VERSION "dbc-export 1 2026.26.6.5"

NS_ :

BS_:

BU_: ADSP APB APP APS APSB BB BMS CC CMP CMPD CP DAS DI DIF DIR DPB EPAS3P EPAS3S EPASTP EPASTS EPBL EPBR ESP EVSE FC GTW HCML HCMR HVP IBST ICR IDB LS OCS1P PARK PCS PCS2 PM PMF PMR PNCD PTC RADC RCM RCM2 RCM3 RCU SCCM SCM SCS SDCR TAS TCU TCU2 TPMS TRCM UI UIS UMC USM V2G VC VCBATT VCBATT0 VCBATT1 VCBATT2 VCCC VCFRONT VCFRONT1 VCFRONT2 VCLEFT VCRIGHT VCSEAT2L VCSEAT2R VCSEC VEH

BO_ 811 APS_warningMatrix0: 8 APS
 SG_ APS_w001_DEPRECATED : 0|1@1+ (1,0) [0|1] "" Vector__XXX
 SG_ APS_w002_ldwDisabled : 1|1@1+ (1,0) [0|1] "" Vector__XXX
 SG_ APS_w003_isaDisabled : 2|1@1+ (1,0) [0|1] "" Vector__XXX
 SG_ APS_w004_accDisabled : 3|1@1+ (1,0) [0|1] "" Vector__XXX
 SG_ APS_w005_fcwCancelled : 4|1@1+ (1,0) [0|1] "" Vector__XXX
 SG_ APS_w006_aebCancelled : 5|1@1+ (1,0) [0|1] "" Vector__XXX
 SG_ APS_w007_ahlbDisabled : 6|1@1+ (1,0) [0|1] "" Vector__XXX
 SG_ APS_w008_parkDisabled : 7|1@1+ (1,0) [0|1] "" Vector__XXX
 SG_ APS_w009_aebFault : 8|1@1+ (1,0) [0|1] "" Vector__XXX
 SG_ APS_w010_radcCalibIssue : 9|1@1+ (1,0) [0|1] "" Vector__XXX
 SG_ APS_w011_scaEvent : 10|1@1+ (1,0) [0|1] "" Vector__XXX
 SG_ APS_w012_Cam_BootFailure : 11|1@1+ (1,0) [0|1] "" Vector__XXX
 SG_ APS_w013_Cam_Watchdog : 12|1@1+ (1,0) [0|1] "" Vector__XXX
 SG_ APS_w014_swAssert : 13|1@1+ (1,0) [0|1] "" Vector__XXX
 SG_ APS_w015_Camera_Failsafes : 14|1@1+ (1,0) [0|1] "" Vector__XXX
 SG_ APS_w016_aeb_e_event : 15|1@1+ (1,0) [0|1] "" Vector__XXX
 SG_ APS_w017_Cam_Msg_MIA : 16|1@1+ (1,0) [0|1] "" Vector__XXX
 SG_ APS_w018_ECU_Power_Issue : 17|1@1+ (1,0) [0|1] "" Vector__XXX
 SG_ APS_w019_ECU_Stack_Overflow : 18|1@1+ (1,0) [0|1] "" Vector__XXX
 SG_ APS_w020_ECU_checkstopError : 19|1@1+ (1,0) [0|1] "" Vector__XXX
 SG_ APS_w021_ECU_Temperature_Issue : 20|1@1+ (1,0) [0|1] "" Vector__XXX
 SG_ APS_w022_ECU_EEPROM_Failure : 21|1@1+ (1,0) [0|1] "" Vector__XXX
 SG_ APS_w023_ECU_Cam_Statemismatc : 22|1@1+ (1,0) [0|1] "" Vector__XXX
 SG_ APS_w024_ECU_Watchdog_Reset : 23|1@1+ (1,0) [0|1] "" Vector__XXX
 SG_ APS_w025_LC_Steering_Override : 24|1@1+ (1,0) [0|1] "" Vector__XXX
 SG_ APS_w026_ECU_timingIssue : 25|1@1+ (1,0) [0|1] "" Vector__XXX
 SG_ APS_w027_ECU_Reset_Fault : 26|1@1+ (1,0) [0|1] "" Vector__XXX
 SG_ APS_w028_spi_rx_error : 27|1@1+ (1,0) [0|1] "" Vector__XXX
 SG_ APS_w029_spi_tx_error : 28|1@1+ (1,0) [0|1] "" Vector__XXX
 SG_ APS_w030_Heater_Issue : 29|1@1+ (1,0) [0|1] "" Vector__XXX
 SG_ APS_w031_canRxError : 30|1@1+ (1,0) [0|1] "" Vector__XXX
 SG_ APS_w032_canTxError : 31|1@1+ (1,0) [0|1] "" Vector__XXX
 SG_ APS_w033_gtwMia : 32|1@1+ (1,0) [0|1] "" Vector__XXX
 SG_ APS_w034_sccmMia : 33|1@1+ (1,0) [0|1] "" Vector__XXX
 SG_ APS_w035_espMia : 34|1@1+ (1,0) [0|1] "" Vector__XXX
 SG_ APS_w036_bdyMia : 35|1@1+ (1,0) [0|1] "" Vector__XXX
 SG_ APS_w037_camTacIssue : 36|1@1+ (1,0) [0|1] "" Vector__XXX
 SG_ APS_w038_camFailure : 37|1@1+ (1,0) [0|1] "" Vector__XXX
 SG_ APS_w039_sdm_rcm_Mia : 38|1@1+ (1,0) [0|1] "" Vector__XXX
 SG_ APS_w040_autopilotAngleSaturated : 39|1@1+ (1,0) [0|1] "" Vector__XXX
 SG_ APS_w041_autopilotRateSaturated : 40|1@1+ (1,0) [0|1] "" Vector__XXX
 SG_ APS_w042_autopilotAborting : 41|1@1+ (1,0) [0|1] "" Vector__XXX
 SG_ APS_w043_camLongRunTime : 42|1@1+ (1,0) [0|1] "" Vector__XXX
 SG_ APS_w044_appMobileyeFailure : 43|1@1+ (1,0) [0|1] "" Vector__XXX
 SG_ APS_w045_radMia : 44|1@1+ (1,0) [0|1] "" Vector__XXX
 SG_ APS_w046_eepromRecordAbsent : 45|1@1+ (1,0) [0|1] "" Vector__XXX
 SG_ APS_w047_edrEvent : 46|1@1+ (1,0) [0|1] "" Vector__XXX
 SG_ APS_w048_DAS_Features_Disabled : 47|1@1+ (1,0) [0|1] "" Vector__XXX
 SG_ APS_w049_eyeqVersionMismatch : 48|1@1+ (1,0) [0|1] "" Vector__XXX
 SG_ APS_w050_aeb_event : 49|1@1+ (1,0) [0|1] "" Vector__XXX
 SG_ APS_w051_radcEcuIssue : 50|1@1+ (1,0) [0|1] "" Vector__XXX
 SG_ APS_w052_radcSensorIssue : 51|1@1+ (1,0) [0|1] "" Vector__XXX
 SG_ APS_w053_radcCommIssue : 52|1@1+ (1,0) [0|1] "" Vector__XXX
 SG_ APS_w054_camAutofix : 53|1@1+ (1,0) [0|1] "" Vector__XXX
 SG_ APS_w055_radcVersionMismatch : 54|1@1+ (1,0) [0|1] "" Vector__XXX
 SG_ APS_w056_diMia : 55|1@1+ (1,0) [0|1] "" Vector__XXX
 SG_ APS_w057_mcuMia : 56|1@1+ (1,0) [0|1] "" Vector__XXX
 SG_ APS_w058_epbMia : 57|1@1+ (1,0) [0|1] "" Vector__XXX
 SG_ APS_w059_parkMia : 58|1@1+ (1,0) [0|1] "" Vector__XXX
 SG_ APS_w060_fcw_event : 59|1@1+ (1,0) [0|1] "" Vector__XXX
 SG_ APS_w061_tasMia : 60|1@1+ (1,0) [0|1] "" Vector__XXX
 SG_ APS_w062_radcAlignment : 61|1@1+ (1,0) [0|1] "" Vector__XXX
 SG_ APS_w063_parkVersionMismatch : 62|1@1+ (1,0) [0|1] "" Vector__XXX
 SG_ APS_w064_epasMia : 63|1@1+ (1,0) [0|1] "" Vector__XXX

BO_ 876 APS_warningMatrix1: 8 APS
 SG_ APS_w065_deserializerOvercurrent : 0|1@1+ (1,0) [0|1] "" Vector__XXX
 SG_ APS_w066_deserializerLockLost : 1|1@1+ (1,0) [0|1] "" Vector__XXX
 SG_ APS_w067_steeringAlignment : 2|1@1+ (1,0) [0|1] "" Vector__XXX
 SG_ APS_w068_vlInconsistency : 3|1@1+ (1,0) [0|1] "" Vector__XXX
 SG_ APS_w069_apcSpaceMasked : 4|1@1+ (1,0) [0|1] "" Vector__XXX
 SG_ APS_w070_apcIncompleteCal : 5|1@1+ (1,0) [0|1] "" Vector__XXX
 SG_ APS_w071_selfparkStarted : 6|1@1+ (1,0) [0|1] "" Vector__XXX
 SG_ APS_w072_selfparkComplete : 7|1@1+ (1,0) [0|1] "" Vector__XXX
 SG_ APS_w073_issueEscalatedLDW : 8|1@1+ (1,0) [0|1] "" Vector__XXX
 SG_ APS_w074_inPathStationaryObst : 9|1@1+ (1,0) [0|1] "" Vector__XXX
 SG_ APS_w075_scMia : 10|1@1+ (1,0) [0|1] "" Vector__XXX
 SG_ APS_w076_mobilEyeSetC : 11|1@1+ (1,0) [0|1] "" Vector__XXX
 SG_ APS_w077_pmmActive : 12|1@1+ (1,0) [0|1] "" Vector__XXX
 SG_ APS_w078_pmmActive2 : 13|1@1+ (1,0) [0|1] "" Vector__XXX
 SG_ APS_w079_edrAvailable : 14|1@1+ (1,0) [0|1] "" Vector__XXX
 SG_ APS_w080_accFailedActivation : 15|1@1+ (1,0) [0|1] "" Vector__XXX
 SG_ APS_w081_pmmActiveBraking : 16|1@1+ (1,0) [0|1] "" Vector__XXX
 SG_ APS_w082_inPathFSviolation : 17|1@1+ (1,0) [0|1] "" Vector__XXX
 SG_ APS_w083_inPathRADObject : 18|1@1+ (1,0) [0|1] "" Vector__XXX
 SG_ APS_w084_pmmIPSO : 19|1@1+ (1,0) [0|1] "" Vector__XXX
 SG_ APS_w085_pmmSteering : 20|1@1+ (1,0) [0|1] "" Vector__XXX
 SG_ APS_w086_robCollision : 21|1@1+ (1,0) [0|1] "" Vector__XXX
 SG_ APS_w087_DEPRECATED : 22|1@1+ (1,0) [0|1] "" Vector__XXX
 SG_ APS_w088_DEPRECATED : 23|1@1+ (1,0) [0|1] "" Vector__XXX
 SG_ APS_w089_DEPRECATED : 24|1@1+ (1,0) [0|1] "" Vector__XXX
 SG_ APS_w090_DEPRECATED : 25|1@1+ (1,0) [0|1] "" Vector__XXX
 SG_ APS_w091_DEPRECATED : 26|1@1+ (1,0) [0|1] "" Vector__XXX
 SG_ APS_w092_DEPRECATED : 27|1@1+ (1,0) [0|1] "" Vector__XXX
 SG_ APS_w093_DEPRECATED : 28|1@1+ (1,0) [0|1] "" Vector__XXX
 SG_ APS_w094_DEPRECATED : 29|1@1+ (1,0) [0|1] "" Vector__XXX
 SG_ APS_w095_DEPRECATED : 30|1@1+ (1,0) [0|1] "" Vector__XXX
 SG_ APS_w096_DEPRECATED : 31|1@1+ (1,0) [0|1] "" Vector__XXX
 SG_ APS_w097_DEPRECATED : 32|1@1+ (1,0) [0|1] "" Vector__XXX
 SG_ APS_w098_DEPRECATED : 33|1@1+ (1,0) [0|1] "" Vector__XXX
 SG_ APS_w099_DEPRECATED : 34|1@1+ (1,0) [0|1] "" Vector__XXX
 SG_ APS_w100_DEPRECATED : 35|1@1+ (1,0) [0|1] "" Vector__XXX
 SG_ APS_w101_DEPRECATED : 36|1@1+ (1,0) [0|1] "" Vector__XXX
 SG_ APS_w102_DEPRECATED : 37|1@1+ (1,0) [0|1] "" Vector__XXX
 SG_ APS_w103_robExperimentalAEB : 38|1@1+ (1,0) [0|1] "" Vector__XXX
 SG_ APS_w104_DEPRECATED : 39|1@1+ (1,0) [0|1] "" Vector__XXX
 SG_ APS_w105_DEPRECATED : 40|1@1+ (1,0) [0|1] "" Vector__XXX
 SG_ APS_w106_torsionBarOffset : 41|1@1+ (1,0) [0|1] "" Vector__XXX

BO_ 1113 APS_warningMatrix2: 8 APS
 SG_ APS_w129_ECU_Power_Issue : 0|1@1+ (1,0) [0|1] "" Vector__XXX
 SG_ APS_w130_ECU_Thermal_Issue : 1|1@1+ (1,0) [0|1] "" Vector__XXX
 SG_ APS_w131_trap_exception : 2|1@1+ (1,0) [0|1] "" Vector__XXX
 SG_ APS_w132_appVersionMismatch : 3|1@1+ (1,0) [0|1] "" Vector__XXX
 SG_ APS_w133_ETHSwitchError : 4|1@1+ (1,0) [0|1] "" Vector__XXX
 SG_ APS_w134_appMia : 5|1@1+ (1,0) [0|1] "" Vector__XXX
 SG_ APS_w135_appCritical : 6|1@1+ (1,0) [0|1] "" Vector__XXX
 SG_ APS_w136_gpsDisabled : 7|1@1+ (1,0) [0|1] "" Vector__XXX
 SG_ APS_w137_gpsFaultReset : 8|1@1+ (1,0) [0|1] "" Vector__XXX
 SG_ APS_w138_gpsComIssue : 9|1@1+ (1,0) [0|1] "" Vector__XXX
 SG_ APS_w139_udpBufferOverflow : 10|1@1+ (1,0) [0|1] "" Vector__XXX
 SG_ APS_w140_vcfrontMiaVehicleBus : 11|1@1+ (1,0) [0|1] "" Vector__XXX
 SG_ APS_w141_rcmMiaPartyBus : 12|1@1+ (1,0) [0|1] "" Vector__XXX
 SG_ APS_w142_diMiaPartyBus : 13|1@1+ (1,0) [0|1] "" Vector__XXX
 SG_ APS_w143_espMiaPartyBus : 14|1@1+ (1,0) [0|1] "" Vector__XXX
 SG_ APS_w144_vcleftMiaPartyBus : 15|1@1+ (1,0) [0|1] "" Vector__XXX
 SG_ APS_w145_vcrightMiaPartyBus : 16|1@1+ (1,0) [0|1] "" Vector__XXX
 SG_ APS_w146_epas3pMiaPartyBus : 17|1@1+ (1,0) [0|1] "" Vector__XXX
 SG_ APS_w147_vcleftMiaVehBus : 18|1@1+ (1,0) [0|1] "" Vector__XXX
 SG_ APS_w148_vcrightMiaVehBus : 19|1@1+ (1,0) [0|1] "" Vector__XXX
 SG_ APS_w149_epblMiaVehBus : 20|1@1+ (1,0) [0|1] "" Vector__XXX
 SG_ APS_w150_sccmMiaVehBus : 21|1@1+ (1,0) [0|1] "" Vector__XXX
 SG_ APS_w151_apRecovered : 22|1@1+ (1,0) [0|1] "" Vector__XXX
 SG_ APS_w152_gpsFusionStatus : 23|1@1+ (1,0) [0|1] "" Vector__XXX
 SG_ APS_w153_eacInhibit : 24|1@1+ (1,0) [0|1] "" Vector__XXX
 SG_ APS_w155_ethLwipError : 26|1@1+ (1,0) [0|1] "" Vector__XXX
 SG_ APS_w156_lwipAssert : 27|1@1+ (1,0) [0|1] "" Vector__XXX
 SG_ APS_w157_autopilotReboot : 28|1@1+ (1,0) [0|1] "" Vector__XXX
 SG_ APS_w158_apbMia : 29|1@1+ (1,0) [0|1] "" Vector__XXX
 SG_ APS_w159_apbCritical : 30|1@1+ (1,0) [0|1] "" Vector__XXX
 SG_ APS_w160_apbVersionMismatch : 31|1@1+ (1,0) [0|1] "" Vector__XXX
 SG_ APS_w161_gpsAntennaDisconnected : 32|1@1+ (1,0) [0|1] "" Vector__XXX
 SG_ APS_w162_TurboA_DisRegPgoodErr : 33|1@1+ (1,0) [0|1] "" Vector__XXX
 SG_ APS_w163_TurboA_DisRegNFault : 34|1@1+ (1,0) [0|1] "" Vector__XXX
 SG_ APS_w164_TurboA_12VFuseFault : 35|1@1+ (1,0) [0|1] "" Vector__XXX
 SG_ APS_w165_TurboA_Temp_NOS : 36|1@1+ (1,0) [0|1] "" Vector__XXX
 SG_ APS_w166_TurboA_SMSLockStepErr : 37|1@1+ (1,0) [0|1] "" Vector__XXX
 SG_ APS_w167_TurboA_TMU_Throttle : 38|1@1+ (1,0) [0|1] "" Vector__XXX
 SG_ APS_w168_TurboA_SMS_WDOG : 39|1@1+ (1,0) [0|1] "" Vector__XXX
 SG_ APS_w169_TurboA_SCS_LKUP : 40|1@1+ (1,0) [0|1] "" Vector__XXX
 SG_ APS_w170_TurboA_A72_watchdog : 41|1@1+ (1,0) [0|1] "" Vector__XXX
 SG_ APS_w171_TurboA_SMS_taskUtilErr : 42|1@1+ (1,0) [0|1] "" Vector__XXX
 SG_ APS_w172_apFeaturesUnavailable : 43|1@1+ (1,0) [0|1] "" Vector__XXX
 SG_ APS_w178_TurboB_DisRegPgoodErr : 49|1@1+ (1,0) [0|1] "" Vector__XXX
 SG_ APS_w179_TurboB_DisRegNFault : 50|1@1+ (1,0) [0|1] "" Vector__XXX
 SG_ APS_w180_TurboB_12VFuseFault : 51|1@1+ (1,0) [0|1] "" Vector__XXX
 SG_ APS_w181_TurboB_Temp_NOS : 52|1@1+ (1,0) [0|1] "" Vector__XXX
 SG_ APS_w182_TurboB_SMSLockStepErr : 53|1@1+ (1,0) [0|1] "" Vector__XXX
 SG_ APS_w183_TurboB_TMU_Throttle : 54|1@1+ (1,0) [0|1] "" Vector__XXX
 SG_ APS_w184_TurboB_SMS_WDOG : 55|1@1+ (1,0) [0|1] "" Vector__XXX
 SG_ APS_w185_TurboB_SCS_LKUP : 56|1@1+ (1,0) [0|1] "" Vector__XXX
 SG_ APS_w186_TurboB_A72_watchdog : 57|1@1+ (1,0) [0|1] "" Vector__XXX
 SG_ APS_w187_TurboB_SMS_taskUtilErr : 58|1@1+ (1,0) [0|1] "" Vector__XXX
 SG_ APS_w188_otherTurboUartMIA : 59|1@1+ (1,0) [0|1] "" Vector__XXX
 SG_ APS_w189_vcfrontMiaPartyBus : 60|1@1+ (1,0) [0|1] "" Vector__XXX
 SG_ APS_w190_iboosterMia : 61|1@1+ (1,0) [0|1] "" Vector__XXX
 SG_ APS_w191_timesyncError : 62|1@1+ (1,0) [0|1] "" Vector__XXX
 SG_ APS_w192_CANFault : 63|1@1+ (1,0) [0|1] "" Vector__XXX

BO_ 848 APS_warningMatrix3: 8 APS
 SG_ APS_w193_camWindshieldUnclean : 0|1@1+ (1,0) [0|1] "" Vector__XXX
 SG_ APS_w194_accDriverResumeRqrd : 1|1@1+ (1,0) [0|1] "" Vector__XXX
 SG_ APS_w195_scwUnavailable : 2|1@1+ (1,0) [0|1] "" Vector__XXX
 SG_ APS_w196_stopSignWarning : 3|1@1+ (1,0) [0|1] "" Vector__XXX
 SG_ APS_w197_redLightWarning : 4|1@1+ (1,0) [0|1] "" Vector__XXX
 SG_ APS_w198_tsrUnavailable : 5|1@1+ (1,0) [0|1] "" Vector__XXX
 SG_ APS_w199_apcAbort : 6|1@1+ (1,0) [0|1] "" Vector__XXX
 SG_ APS_w200_lcSlowdown : 7|1@1+ (1,0) [0|1] "" Vector__XXX
 SG_ APS_w201_lcAborting : 8|1@1+ (1,0) [0|1] "" Vector__XXX
 SG_ APS_w202_scwNoisyEnvironment : 9|1@1+ (1,0) [0|1] "" Vector__XXX
 SG_ APS_w203_apcActivation : 10|1@1+ (1,0) [0|1] "" Vector__XXX
 SG_ APS_w204_apcFinalFront : 11|1@1+ (1,0) [0|1] "" Vector__XXX
 SG_ APS_w205_apcFinalRear : 12|1@1+ (1,0) [0|1] "" Vector__XXX
 SG_ APS_w206_autosteerNotEnabled : 13|1@1+ (1,0) [0|1] "" Vector__XXX
 SG_ APS_w207_autosteerUnavailable : 14|1@1+ (1,0) [0|1] "" Vector__XXX
 SG_ APS_w208_rackDetected : 15|1@1+ (1,0) [0|1] "" Vector__XXX
 SG_ APS_w209_autoSummonRequest : 16|1@1+ (1,0) [0|1] "" Vector__XXX
 SG_ APS_w210_camObstrcted : 17|1@1+ (1,0) [0|1] "" Vector__XXX
 SG_ APS_w211_accNoSeatBelt : 18|1@1+ (1,0) [0|1] "" Vector__XXX
 SG_ APS_w212_lcUnavailableStrikeOut : 19|1@1+ (1,0) [0|1] "" Vector__XXX
 SG_ APS_w213_autosteerStruckOut : 20|1@1+ (1,0) [0|1] "" Vector__XXX
 SG_ APS_w214_driverNotIntracting : 21|1@1+ (1,0) [0|1] "" Vector__XXX
 SG_ APS_w215_contDriverNotIntracting : 22|1@1+ (1,0) [0|1] "" Vector__XXX
 SG_ APS_w216_driverOverriding : 23|1@1+ (1,0) [0|1] "" Vector__XXX
 SG_ APS_w217_lcUnavailableSpeeding : 24|1@1+ (1,0) [0|1] "" Vector__XXX
 SG_ APS_w218_lcSpeedExceededLimit : 25|1@1+ (1,0) [0|1] "" Vector__XXX
 SG_ APS_w219_lcTempUnavailableSpeed : 26|1@1+ (1,0) [0|1] "" Vector__XXX
 SG_ APS_w220_lcTempUnavailableRoad : 27|1@1+ (1,0) [0|1] "" Vector__XXX
 SG_ APS_w221_accRadarBlind : 28|1@1+ (1,0) [0|1] "" Vector__XXX
 SG_ APS_w222_accCameraBlind : 29|1@1+ (1,0) [0|1] "" Vector__XXX
 SG_ APS_w223_accObjectInPath : 30|1@1+ (1,0) [0|1] "" Vector__XXX
 SG_ APS_w224_accCameraCalibration : 31|1@1+ (1,0) [0|1] "" Vector__XXX
 SG_ APS_w225_lcDegradedVisSpeedLmt : 32|1@1+ (1,0) [0|1] "" Vector__XXX
 SG_ APS_w226_lcCamCalNeededSpeedLmt : 33|1@1+ (1,0) [0|1] "" Vector__XXX
 SG_ APS_w227_virtualWallBlocked : 34|1@1+ (1,0) [0|1] "" Vector__XXX
 SG_ APS_w228_DEPRECATED : 35|1@1+ (1,0) [0|1] "" Vector__XXX
 SG_ APS_w229_alcUltrasoundDamaged : 36|1@1+ (1,0) [0|1] "" Vector__XXX
 SG_ APS_w230_alcUltrasoundBlocked : 37|1@1+ (1,0) [0|1] "" Vector__XXX
 SG_ APS_w231_idfEvent : 38|1@1+ (1,0) [0|1] "" Vector__XXX
 SG_ APS_w232_laneChangeRequested : 39|1@1+ (1,0) [0|1] "" Vector__XXX
 SG_ APS_w235_a72LoopDetected : 42|1@1+ (1,0) [0|1] "" Vector__XXX
 SG_ APS_w236_canSharedMemError : 43|1@1+ (1,0) [0|1] "" Vector__XXX
 SG_ APS_w237_faultMgrEventDetected : 44|1@1+ (1,0) [0|1] "" Vector__XXX
 SG_ APS_w238_resetReason : 45|1@1+ (1,0) [0|1] "" Vector__XXX
 SG_ APS_w241_ddrInitFailures : 48|1@1+ (1,0) [0|1] "" Vector__XXX
 SG_ APS_w242_tripMBISTFailure : 49|1@1+ (1,0) [0|1] "" Vector__XXX
 SG_ APS_w243_tripHWErrorStatus : 50|1@1+ (1,0) [0|1] "" Vector__XXX
 SG_ APS_w244_gpuHWFaultStatus : 51|1@1+ (1,0) [0|1] "" Vector__XXX
 SG_ APS_w245_eloopRxFromUnexpectedSo : 52|1@1+ (1,0) [0|1] "" Vector__XXX
 SG_ APS_w246_ethloopSwitchPortLinkDo : 53|1@1+ (1,0) [0|1] "" Vector__XXX
 SG_ APS_w247_ethernetFrameError : 54|1@1+ (1,0) [0|1] "" Vector__XXX
 SG_ APS_w248_ethloopSwitchPoorSqi : 55|1@1+ (1,0) [0|1] "" Vector__XXX
 SG_ APS_w249_ufsFailures : 56|1@1+ (1,0) [0|1] "" Vector__XXX
 SG_ APS_w250_ethloopSwitchMemUsageTo : 57|1@1+ (1,0) [0|1] "" Vector__XXX
 SG_ APS_w251_ethloopSwitchMemUsageTo : 58|1@1+ (1,0) [0|1] "" Vector__XXX
 SG_ APS_w252_ethSwitchPortLinkDown : 59|1@1+ (1,0) [0|1] "" Vector__XXX
 SG_ APS_w253_powerStateTimeout : 60|1@1+ (1,0) [0|1] "" Vector__XXX
 SG_ APS_w254_sleepStateTimeout : 61|1@1+ (1,0) [0|1] "" Vector__XXX
 SG_ APS_w255_bootHealth : 62|1@1+ (1,0) [0|1] "" Vector__XXX

BO_ 784 APS_warningMatrix4: 8 APS
 SG_ APS_w257_assertFailure : 0|1@1+ (1,0) [0|1] "" Vector__XXX
 SG_ APS_w258_qspiFlashSectorChecksum : 1|1@1+ (1,0) [0|1] "" Vector__XXX
 SG_ APS_w259_qspiFailure : 2|1@1+ (1,0) [0|1] "" Vector__XXX
 SG_ APS_w260_pgoodFailure : 3|1@1+ (1,0) [0|1] "" Vector__XXX
 SG_ APS_w261_vrmFaultGrpA : 4|1@1+ (1,0) [0|1] "" Vector__XXX
 SG_ APS_w262_vrmFaultGrpB : 5|1@1+ (1,0) [0|1] "" Vector__XXX
 SG_ APS_w263_vrmFaultGrpC : 6|1@1+ (1,0) [0|1] "" Vector__XXX
 SG_ APS_w264_ddrPhy0Failures : 7|1@1+ (1,0) [0|1] "" Vector__XXX
 SG_ APS_w265_ddrPhy1Failures : 8|1@1+ (1,0) [0|1] "" Vector__XXX
 SG_ APS_w266_ddrPhy2Failures : 9|1@1+ (1,0) [0|1] "" Vector__XXX
 SG_ APS_w267_ddrPhy3Failures : 10|1@1+ (1,0) [0|1] "" Vector__XXX
 SG_ APS_w268_ddrControllerFailures : 11|1@1+ (1,0) [0|1] "" Vector__XXX
 SG_ APS_w269_ethSwitchRxPageCountToo : 12|1@1+ (1,0) [0|1] "" Vector__XXX
 SG_ APS_w270_ethSwitchRxPageCountToo : 13|1@1+ (1,0) [0|1] "" Vector__XXX
 SG_ APS_w271_ddrScheduler0EccErrors : 14|1@1+ (1,0) [0|1] "" Vector__XXX
 SG_ APS_w272_ddrScheduler1EccErrors : 15|1@1+ (1,0) [0|1] "" Vector__XXX
 SG_ APS_w273_ddrScheduler2EccErrors : 16|1@1+ (1,0) [0|1] "" Vector__XXX
 SG_ APS_w274_ddrScheduler3EccErrors : 17|1@1+ (1,0) [0|1] "" Vector__XXX
 SG_ APS_w275_ddrScheduler4EccErrors : 18|1@1+ (1,0) [0|1] "" Vector__XXX
 SG_ APS_w276_ddrScheduler5EccErrors : 19|1@1+ (1,0) [0|1] "" Vector__XXX
 SG_ APS_w277_ddrScheduler6EccErrors : 20|1@1+ (1,0) [0|1] "" Vector__XXX
 SG_ APS_w278_ddrScheduler7EccErrors : 21|1@1+ (1,0) [0|1] "" Vector__XXX
 SG_ APS_w279_ufsPartitionError : 22|1@1+ (1,0) [0|1] "" Vector__XXX
 SG_ APS_w280_pepsMia : 23|1@1+ (1,0) [0|1] "" Vector__XXX
 SG_ APS_w281_rsaMia : 24|1@1+ (1,0) [0|1] "" Vector__XXX
 SG_ APS_w282_smmuError : 25|1@1+ (1,0) [0|1] "" Vector__XXX
 SG_ APS_w283_psfaMia : 26|1@1+ (1,0) [0|1] "" Vector__XXX
 SG_ APS_w284_cam12VBuckBoostAPwrIssu : 27|1@1+ (1,0) [0|1] "" Vector__XXX
 SG_ APS_w285_cam12VBuckBoostBPwrIssu : 28|1@1+ (1,0) [0|1] "" Vector__XXX
 SG_ APS_w286_cam12VEFuseAPrimaryIssu : 29|1@1+ (1,0) [0|1] "" Vector__XXX
 SG_ APS_w287_cam12VEFuseASecondaryIs : 30|1@1+ (1,0) [0|1] "" Vector__XXX
 SG_ APS_w288_brakeboosterMia : 31|1@1+ (1,0) [0|1] "" Vector__XXX
 SG_ APS_w289_turboTemperatureWarning : 32|1@1+ (1,0) [0|1] "" Vector__XXX
 SG_ APS_w290_cam12VBuckBoostBPwrRing : 33|1@1+ (1,0) [0|1] "" Vector__XXX
 SG_ APS_w291_eplannerError : 34|1@1+ (1,0) [0|1] "" Vector__XXX
 SG_ APS_w292_CH_busOff : 35|1@1+ (1,0) [0|1] "" Vector__XXX
 SG_ APS_w293_PARTY_busOff : 36|1@1+ (1,0) [0|1] "" Vector__XXX
 SG_ APS_w294_VEH_busOff : 37|1@1+ (1,0) [0|1] "" Vector__XXX
 SG_ APS_w295_PT_busOff : 38|1@1+ (1,0) [0|1] "" Vector__XXX
 SG_ APS_w296_wdogMonTaskDeadlineMiss : 39|1@1+ (1,0) [0|1] "" Vector__XXX
 SG_ APS_w297_earlyWDogAlert : 40|1@1+ (1,0) [0|1] "" Vector__XXX
 SG_ APS_w298_cpuToApCanSharedMemErro : 41|1@1+ (1,0) [0|1] "" Vector__XXX
 SG_ APS_w299_apToCpuCanSharedMemErro : 42|1@1+ (1,0) [0|1] "" Vector__XXX
 SG_ APS_w300_sharedMemoryAccessError : 43|1@1+ (1,0) [0|1] "" Vector__XXX
 SG_ APS_w301_nocTimeoutDetected : 44|1@1+ (1,0) [0|1] "" Vector__XXX
 SG_ APS_w302_canAPShmFifoFull : 45|1@1+ (1,0) [0|1] "" Vector__XXX
 SG_ APS_w303_canAPShmFifoEmpty : 46|1@1+ (1,0) [0|1] "" Vector__XXX
 SG_ APS_w304_dataAbort : 47|1@1+ (1,0) [0|1] "" Vector__XXX
 SG_ APS_w305_gpsPgoodFailure : 48|1@1+ (1,0) [0|1] "" Vector__XXX
 SG_ APS_w306_ethPgoodFailure : 49|1@1+ (1,0) [0|1] "" Vector__XXX
 SG_ APS_w307_eccEventDetected : 50|1@1+ (1,0) [0|1] "" Vector__XXX
 SG_ APS_w308_pmicErrorDetected : 51|1@1+ (1,0) [0|1] "" Vector__XXX
 SG_ APS_w309_ethBridgeDown : 52|1@1+ (1,0) [0|1] "" Vector__XXX
 SG_ APS_w310_wakeBootMetrics : 53|1@1+ (1,0) [0|1] "" Vector__XXX
 SG_ APS_w311_apbdgDasMia : 54|1@1+ (1,0) [0|1] "" Vector__XXX
 SG_ APS_w312_apbdgApMia : 55|1@1+ (1,0) [0|1] "" Vector__XXX
 SG_ APS_w313_BDY_busOff : 56|1@1+ (1,0) [0|1] "" Vector__XXX
 SG_ APS_w315_epas3pMiaBdyBus : 58|1@1+ (1,0) [0|1] "" Vector__XXX
 SG_ APS_w316_apBootHealth : 59|1@1+ (1,0) [0|1] "" Vector__XXX
 SG_ APS_w317_uiMia : 60|1@1+ (1,0) [0|1] "" Vector__XXX
 SG_ APS_w318_ethernetNetworkBufferHi : 61|1@1+ (1,0) [0|1] "" Vector__XXX
 SG_ APS_w319_vehDasImposterDetected : 62|1@1+ (1,0) [0|1] "" Vector__XXX
 SG_ APS_w320_eplannerPreconditionsMe : 63|1@1+ (1,0) [0|1] "" Vector__XXX

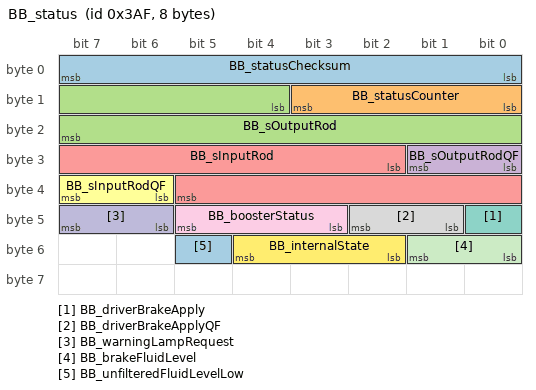
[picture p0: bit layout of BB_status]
BO_ 943 BB_status: 8 BB
 SG_ BB_statusChecksum : 0|8@1+ (1,0) [0|255] "" Vector__XXX
 SG_ BB_statusCounter : 8|4@1+ (1,0) [0|15] "" Vector__XXX
 SG_ BB_sOutputRod : 12|12@1+ (0.015625,-5) [-5|47] "mm" Vector__XXX
 SG_ BB_sOutputRodQF : 24|2@1+ (1,0) [0|3] "" Vector__XXX
 SG_ BB_sInputRod : 26|12@1+ (0.015625,-5) [-5|47] "mm" Vector__XXX
 SG_ BB_sInputRodQF : 38|2@1+ (1,0) [0|3] "" Vector__XXX
 SG_ BB_driverBrakeApply : 40|1@1+ (1,0) [0|1] "" Vector__XXX
 SG_ BB_driverBrakeApplyQF : 41|2@1+ (1,0) [0|3] "" Vector__XXX
 SG_ BB_boosterStatus : 43|3@1+ (1,0) [0|7] "" Vector__XXX
 SG_ BB_warningLampRequest : 46|2@1+ (1,0) [0|3] "" Vector__XXX
 SG_ BB_brakeFluidLevel : 48|2@1+ (1,0) [0|3] "" Vector__XXX
 SG_ BB_internalState : 50|3@1+ (1,0) [0|7] "" Vector__XXX
 SG_ BB_unfilteredFluidLevelLow : 53|1@1+ (1,0) [0|1] "" Vector__XXX

BO_ 1343 BMS_alertLog: 8 BMS
 SG_ BMS_alertID M : 0|9@1+ (1,0) [0|511] "" Vector__XXX
 SG_ BMS_alertSet : 15|1@1+ (1,0) [0|1] "" Vector__XXX
 SG_ BMS_a001_gatewayPackEnergy m1 : 16|2@1+ (1,0) [0|3] "" Vector__XXX
 SG_ BMS_a001_expectedPackEnergy m1 : 18|2@1+ (1,0) [0|3] "" Vector__XXX
 SG_ BMS_a002_gatewayPackPerformanceD m2 : 16|3@1+ (1,0) [0|7] "" Vector__XXX
 SG_ BMS_a002_expectedPackPerformance m2 : 19|3@1+ (1,0) [0|7] "" Vector__XXX
 SG_ BMS_a002_bmsPackMass m2 : 24|8@1+ (1,300) [300|555] "" Vector__XXX
 SG_ BMS_a003_calBlockData_0 m3 : 16|32@1+ (1,0) [0|4294967295] "" Vector__XXX
 SG_ BMS_a017_packCurrent m17 : 16|8@1+ (8,-1500) [-1500|540] "" Vector__XXX
 SG_ BMS_a017_ovBrickVID m17 : 24|7@1+ (1,1) [1|128] "" Vector__XXX
 SG_ BMS_a017_ovBrickV m17 : 32|16@1+ (7.62939453125e-05,0) [0|4.99992370605] "" Vector__XXX
 SG_ BMS_a018_packCurrent m18 : 16|8@1+ (8,-1496) [-1496|544] "" Vector__XXX
 SG_ BMS_a018_uvBrickVID m18 : 24|7@1+ (1,1) [1|128] "" Vector__XXX
 SG_ BMS_a018_uvBrickV m18 : 32|16@1+ (7.62939453125e-05,0) [0|4.99992370605] "" Vector__XXX
 SG_ BMS_a019_coolantInletT m19 : 16|8@1+ (0.4,-20) [-20|82] "" Vector__XXX
 SG_ BMS_a019_activeCoolingTarget m19 : 24|8@1+ (0.4,-20) [-20|82] "" Vector__XXX
 SG_ BMS_a019_maxBrickT m19 : 32|8@1+ (0.4,-20) [-20|82] "" Vector__XXX
 SG_ BMS_a019_maxBrickTID m19 : 40|5@1+ (1,1) [1|32] "" Vector__XXX
 SG_ BMS_a021_chargeViolation m21 : 16|1@1+ (1,0) [0|1] "" Vector__XXX
 SG_ BMS_a021_currentLimit m21 : 24|8@1+ (8,-1496) [-1496|544] "" Vector__XXX
 SG_ BMS_a021_packCurrent m21 : 32|8@1+ (8,-1496) [-1496|544] "" Vector__XXX
 SG_ BMS_a022_chargeAccumulatorViolat m22 : 16|1@1+ (1,0) [0|1] "" Vector__XXX
 SG_ BMS_a022_chargeAccumulatorValue m22 : 17|23@1+ (10,0) [0|83886070] "" Vector__XXX
 SG_ BMS_a022_chargeAccumulatorLimit m22 : 40|23@1+ (10,0) [0|83886070] "" Vector__XXX
 SG_ BMS_a023_ovStackDeviceID m23 : 16|5@1+ (1,1) [1|32] "" Vector__XXX
 SG_ BMS_a023_ovStackV m23 : 24|16@1+ (0.00128,0) [0|83.8848] "" Vector__XXX
 SG_ BMS_a024_brickID m24 : 16|8@1+ (1,1) [1|256] "" Vector__XXX
 SG_ BMS_a024_deltaV m24 : 24|16@1- (0.0001,0) [-3.2768|3.2767] "" Vector__XXX
 SG_ BMS_a024_avgDvPrev m24 : 40|16@1- (0.0001,0) [-3.2768|3.2767] "" Vector__XXX
 SG_ BMS_a024_packCurrent m24 : 56|8@1+ (8,-1500) [-1500|540] "" Vector__XXX
 SG_ BMS_a027_swIsolationCount m27 : 16|8@1+ (1,0) [0|255] "" Vector__XXX
 SG_ BMS_a030_worstBrickID m30 : 16|8@1+ (1,1) [1|256] "" Vector__XXX
 SG_ BMS_a030_maxBrickImpedance m30 : 24|10@1+ (0.1,0) [0|102.3] "" Vector__XXX
 SG_ BMS_a030_maxNormalizedImpedanceD m30 : 34|7@1+ (0.04,0) [0|5.08] "" Vector__XXX
 SG_ BMS_a030_faultThreshold m30 : 41|7@1+ (0.04,0) [0|5.08] "" Vector__XXX
 SG_ BMS_a030_numBricks m30 : 48|8@1+ (1,0) [0|255] "" Vector__XXX
 SG_ BMS_a030_worstBrickSoc m30 : 56|8@1+ (0.5,0) [0|127.5] "" Vector__XXX
 SG_ BMS_a035_isoR m35 : 16|9@1+ (10,0) [0|5110] "" Vector__XXX
 SG_ BMS_a035_mode m35 : 25|3@1+ (1,0) [0|7] "" Vector__XXX
 SG_ BMS_a035_activeSideVNoR m35 : 28|9@1+ (1,0) [0|511] "" Vector__XXX
 SG_ BMS_a035_activeSideVWithR m35 : 37|9@1+ (1,0) [0|511] "" Vector__XXX
 SG_ BMS_a035_passiveSideVNoR m35 : 46|9@1+ (1,0) [0|511] "" Vector__XXX
 SG_ BMS_a035_passiveSideVWithR m35 : 55|9@1+ (1,0) [0|511] "" Vector__XXX
 SG_ BMS_a039_dcLinkVoltage m39 : 16|10@1+ (1,0) [0|1023] "" Vector__XXX
 SG_ BMS_a039_packVoltage m39 : 26|10@1+ (1,0) [0|1023] "" Vector__XXX
 SG_ BMS_a039_packContactorState m39 : 36|4@1+ (1,0) [0|15] "" Vector__XXX
 SG_ BMS_a039_packCurrent m39 : 40|8@1+ (8,-1496) [-1496|544] "" Vector__XXX
 SG_ BMS_a039_maxBrickV m39 : 48|8@1+ (0.01,2) [2|4.55] "" Vector__XXX
 SG_ BMS_a039_state m39 : 56|4@1+ (1,0) [0|15] "" Vector__XXX
 SG_ BMS_a041_resetType m41 : 16|4@1+ (1,0) [0|15] "" Vector__XXX
 SG_ BMS_a050_MIA_numBadReadings m50 : 16|8@1+ (1,0) [0|255] "" Vector__XXX
 SG_ BMS_a050_MIA_numSnaReadings m50 : 24|8@1+ (1,0) [0|255] "" Vector__XXX
 SG_ BMS_a050_MIA_brickId m50 : 32|8@1+ (1,1) [1|256] "" Vector__XXX
 SG_ BMS_a051_hvp1V5Ref m51 : 16|12@1+ (0.001,0) [0|4.095] "" Vector__XXX
 SG_ BMS_a051_hvp3V0Ref m51 : 28|12@1+ (0.001,0) [0|4.095] "" Vector__XXX
 SG_ BMS_a051_bms3V0Ref m51 : 40|12@1+ (0.001,0) [0|4.095] "" Vector__XXX
 SG_ BMS_a059_sumBrickVoltages m59 : 16|16@1+ (0.01,0) [0|655.35] "" Vector__XXX
 SG_ BMS_a059_packVoltage m59 : 32|16@1+ (0.01,0) [0|655.35] "" Vector__XXX
 SG_ BMS_a062_state m62 : 16|4@1+ (1,0) [0|15] "" Vector__XXX
 SG_ BMS_a062_minBrickVId m62 : 24|7@1+ (1,1) [1|128] "" Vector__XXX
 SG_ BMS_a062_minBrickVoltage m62 : 32|12@1+ (0.002,0) [0|8.19] "" Vector__XXX
 SG_ BMS_a062_maxBrickVId m62 : 44|7@1+ (1,1) [1|128] "" Vector__XXX
 SG_ BMS_a062_maxBrickVoltage m62 : 51|12@1+ (0.002,0) [0|8.19] "" Vector__XXX
 SG_ BMS_a063_cpFaultInV m63 : 16|12@1+ (0.001,0) [0|4.095] "" Vector__XXX
 SG_ BMS_a064_minBrickSOCID m64 : 16|7@1+ (1,1) [1|128] "" Vector__XXX
 SG_ BMS_a064_minBrickSOC m64 : 24|8@1+ (0.5,0) [0|127.5] "" Vector__XXX
 SG_ BMS_a064_maxBrickSOCID m64 : 32|7@1+ (1,1) [1|128] "" Vector__XXX
 SG_ BMS_a064_maxBrickSOC m64 : 40|8@1+ (0.5,0) [0|127.5] "" Vector__XXX
 SG_ BMS_a064_avgBrickSOC m64 : 48|8@1+ (0.5,0) [0|127.5] "" Vector__XXX
 SG_ BMS_a065_minBrickCacId m65 : 16|7@1+ (1,1) [1|128] "" Vector__XXX
 SG_ BMS_a065_minBrickCac m65 : 24|13@1+ (0.1,0) [0|819.1] "" Vector__XXX
 SG_ BMS_a065_avgBrickCac m65 : 40|13@1+ (0.1,0) [0|819.1] "" Vector__XXX
 SG_ BMS_a065_modCacImbalancePct m65 : 53|10@1+ (0.1,0) [0|102.3] "" Vector__XXX
 SG_ BMS_a066_minBrickSocId m66 : 16|7@1+ (1,1) [1|128] "" Vector__XXX
 SG_ BMS_a066_minBrickSocByOcvMax m66 : 24|8@1+ (0.5,0) [0|127.5] "" Vector__XXX
 SG_ BMS_a066_maxBrickSocId m66 : 32|7@1+ (1,1) [1|128] "" Vector__XXX
 SG_ BMS_a066_maxBrickSocByOcvMin m66 : 40|8@1+ (0.5,0) [0|127.5] "" Vector__XXX
 SG_ BMS_a066_maxBrickSoc m66 : 48|8@1+ (0.5,0) [0|127.5] "" Vector__XXX
 SG_ BMS_a066_avgBrickSoc m66 : 56|8@1+ (0.5,0) [0|127.5] "" Vector__XXX
 SG_ BMS_a067_minBrickCacId m67 : 16|7@1+ (1,1) [1|128] "" Vector__XXX
 SG_ BMS_a067_minBrickCac m67 : 24|13@1+ (0.1,0) [0|819.1] "" Vector__XXX
 SG_ BMS_a067_avgBrickCac m67 : 40|13@1+ (0.1,0) [0|819.1] "" Vector__XXX
 SG_ BMS_a067_modCacImbalancePct m67 : 53|10@1+ (0.1,0) [0|102.3] "" Vector__XXX
 SG_ BMS_a068_minBrickCacId m68 : 16|7@1+ (1,1) [1|128] "" Vector__XXX
 SG_ BMS_a068_minBrickCac m68 : 24|13@1+ (0.1,0) [0|819.1] "" Vector__XXX
 SG_ BMS_a068_avgBrickCac m68 : 40|13@1+ (0.1,0) [0|819.1] "" Vector__XXX
 SG_ BMS_a068_modCacImbalancePct m68 : 53|10@1+ (0.1,0) [0|102.3] "" Vector__XXX
 SG_ BMS_a069_dischargePowerPackVolta m69 : 16|8@1- (0.025,-3.15) [-6.35|0.025] "" Vector__XXX
 SG_ BMS_a069_dischargePowerBrickVolt m69 : 24|8@1- (0.005,-0.63) [-1.27|0.005] "" Vector__XXX
 SG_ BMS_a069_SOC m69 : 32|8@1+ (0.05,0) [0|12.75] "" Vector__XXX
 SG_ BMS_a069_minBrickT m69 : 40|8@1- (0.5,24) [-40|87.5] "" Vector__XXX
 SG_ BMS_a069_minBrickVLimit m69 : 48|8@1+ (0.01,2) [2|4.55] "" Vector__XXX
 SG_ BMS_a069_minBrickV m69 : 56|8@1+ (0.01,2) [2|4.55] "" Vector__XXX
 SG_ BMS_a070_state m70 : 16|4@1+ (1,0) [0|15] "" Vector__XXX
 SG_ BMS_a070_minBrickVId m70 : 24|7@1+ (1,1) [1|128] "" Vector__XXX
 SG_ BMS_a070_minBrickVoltage m70 : 32|12@1+ (0.002,0) [0|8.19] "" Vector__XXX
 SG_ BMS_a070_maxBrickVId m70 : 44|7@1+ (1,1) [1|128] "" Vector__XXX
 SG_ BMS_a070_maxBrickVoltage m70 : 51|12@1+ (0.002,0) [0|8.19] "" Vector__XXX
 SG_ BMS_a071_stateRequest m71 : 16|4@1+ (1,0) [0|15] "" Vector__XXX
 SG_ BMS_a071_state m71 : 20|4@1+ (1,0) [0|15] "" Vector__XXX
 SG_ BMS_a071_transitionAlertId m71 : 24|10@1+ (1,0) [0|1023] "" Vector__XXX
 SG_ BMS_a074_maxBrickVTarget m74 : 16|8@1+ (0.01,2) [2|4.55] "" Vector__XXX
 SG_ BMS_a074_maxBrickV m74 : 24|8@1+ (0.01,2) [2|4.55] "" Vector__XXX
 SG_ BMS_a075_chargeType m75 : 16|1@1+ (1,0) [0|1] "" Vector__XXX
 SG_ BMS_a076_netAh m76 : 16|21@1- (0.01,0) [-10485.76|10485.75] "" Vector__XXX
 SG_ BMS_a076_tetheringActive m76 : 37|1@1+ (1,0) [0|1] "" Vector__XXX
 SG_ BMS_a077_chargeErrType m77 : 16|1@1+ (1,0) [0|1] "" Vector__XXX
 SG_ BMS_a077_maxBrickVTarget m77 : 24|8@1+ (0.01,2) [2|4.55] "" Vector__XXX
 SG_ BMS_a077_maxBrickV m77 : 32|8@1+ (0.01,2) [2|4.55] "" Vector__XXX
 SG_ BMS_a077_packTargetCurrent m77 : 40|8@1+ (8,-1496) [-1496|544] "" Vector__XXX
 SG_ BMS_a077_packCurrent m77 : 48|8@1+ (8,-1496) [-1496|544] "" Vector__XXX
 SG_ BMS_a078_peakDchInChg m78 : 16|16@1- (0.1,0) [-3276.8|3276.7] "" Vector__XXX
 SG_ BMS_a079_maxBrickVTarget m79 : 16|8@1+ (0.01,2) [2|4.55] "" Vector__XXX
 SG_ BMS_a079_maxBrickV m79 : 24|8@1+ (0.01,2) [2|4.55] "" Vector__XXX
 SG_ BMS_a081_stateRequest m81 : 16|4@1+ (1,0) [0|15] "" Vector__XXX
 SG_ BMS_a081_firstBlockingAlertId m81 : 20|9@1+ (1,0) [0|511] "" Vector__XXX
 SG_ BMS_a081_secondBlockingAlertId m81 : 29|9@1+ (1,0) [0|511] "" Vector__XXX
 SG_ BMS_a081_thirdBlockingAlertId m81 : 38|9@1+ (1,0) [0|511] "" Vector__XXX
 SG_ BMS_a081_fourthBlockingAlertId m81 : 47|9@1+ (1,0) [0|511] "" Vector__XXX
 SG_ BMS_a081_totalAlertCount m81 : 56|8@1+ (1,0) [0|255] "" Vector__XXX
 SG_ BMS_a082_stateRequest m82 : 16|4@1+ (1,0) [0|15] "" Vector__XXX
 SG_ BMS_a082_firstAlertId m82 : 20|9@1+ (1,0) [0|511] "" Vector__XXX
 SG_ BMS_a082_secondAlertId m82 : 29|9@1+ (1,0) [0|511] "" Vector__XXX
 SG_ BMS_a082_thirdAlertId m82 : 38|9@1+ (1,0) [0|511] "" Vector__XXX
 SG_ BMS_a082_fourthAlertId m82 : 47|9@1+ (1,0) [0|511] "" Vector__XXX
 SG_ BMS_a082_totalAlertCount m82 : 56|8@1+ (1,0) [0|255] "" Vector__XXX
 SG_ BMS_a083_packContactorRequest m83 : 16|3@1+ (1,0) [0|7] "" Vector__XXX
 SG_ BMS_a085_packContactorSetStatePr m85 : 16|4@1+ (1,0) [0|15] "" Vector__XXX
 SG_ BMS_a085_packContactorSetState m85 : 20|4@1+ (1,0) [0|15] "" Vector__XXX
 SG_ BMS_a085_packContactorSetRe_0001 m85 : 24|3@1+ (1,0) [0|7] "" Vector__XXX
 SG_ BMS_a085_packContactorSetRequest m85 : 27|3@1+ (1,0) [0|7] "" Vector__XXX
 SG_ BMS_a086_fcContactorSetStatePrev m86 : 16|4@1+ (1,0) [0|15] "" Vector__XXX
 SG_ BMS_a086_fcContactorSetState m86 : 20|4@1+ (1,0) [0|15] "" Vector__XXX
 SG_ BMS_a086_fcContactorSetRequestPr m86 : 24|3@1+ (1,0) [0|7] "" Vector__XXX
 SG_ BMS_a086_fcContactorSetRequest m86 : 27|3@1+ (1,0) [0|7] "" Vector__XXX
 SG_ BMS_a087_blockingAlert m87 : 16|9@1+ (1,0) [0|511] "" Vector__XXX
 SG_ BMS_a090_GTWmessageTout m90 : 16|4@1+ (1,0) [0|15] "" Vector__XXX
 SG_ BMS_a098_breakLocationA m98 : 16|5@1+ (1,0) [0|31] "" Vector__XXX
 SG_ BMS_a098_bmbCommStatusTypeA m98 : 21|2@1+ (1,0) [0|3] "" Vector__XXX
 SG_ BMS_a098_breakLocationB m98 : 24|5@1+ (1,0) [0|31] "" Vector__XXX
 SG_ BMS_a098_bmbCommStatusTypeB m98 : 29|2@1+ (1,0) [0|3] "" Vector__XXX
 SG_ BMS_a098_alertFromHvp m98 : 31|1@1+ (1,0) [0|1] "" Vector__XXX
 SG_ BMS_a099_breakLocationA m99 : 16|5@1+ (1,0) [0|31] "" Vector__XXX
 SG_ BMS_a099_bmbCommStatusTypeA m99 : 21|2@1+ (1,0) [0|3] "" Vector__XXX
 SG_ BMS_a099_breakLocationB m99 : 24|5@1+ (1,0) [0|31] "" Vector__XXX
 SG_ BMS_a099_bmbCommStatusTypeB m99 : 29|2@1+ (1,0) [0|3] "" Vector__XXX
 SG_ BMS_a099_bmbChainBreakType m99 : 32|3@1+ (1,0) [0|7] "" Vector__XXX
 SG_ BMS_a099_alertFromHvp m99 : 35|1@1+ (1,0) [0|1] "" Vector__XXX
 SG_ BMS_a100_testTrigger m100 : 16|1@1+ (1,0) [0|1] "" Vector__XXX
 SG_ BMS_a100_setFromNvm m100 : 17|1@1+ (1,0) [0|1] "" Vector__XXX
 SG_ BMS_a100_voltageDeviation m100 : 18|1@1+ (1,0) [0|1] "" Vector__XXX
 SG_ BMS_a100_voltageLoss m100 : 19|1@1+ (1,0) [0|1] "" Vector__XXX
 SG_ BMS_a105_tSenseFailedModule1 m105 : 16|1@1+ (1,0) [0|1] "" Vector__XXX
 SG_ BMS_a105_avgBrickTModule1 m105 : 17|8@1+ (0.5,0) [0|127.5] "" Vector__XXX
 SG_ BMS_a105_tSenseFailedModule2 m105 : 25|1@1+ (1,0) [0|1] "" Vector__XXX
 SG_ BMS_a105_avgBrickTModule2 m105 : 26|8@1+ (0.5,0) [0|127.5] "" Vector__XXX
 SG_ BMS_a105_tSenseFailedModule3 m105 : 34|1@1+ (1,0) [0|1] "" Vector__XXX
 SG_ BMS_a105_avgBrickTModule3 m105 : 35|8@1+ (0.5,0) [0|127.5] "" Vector__XXX
 SG_ BMS_a105_tSenseFailedModule4 m105 : 43|1@1+ (1,0) [0|1] "" Vector__XXX
 SG_ BMS_a105_avgBrickTModule4 m105 : 44|8@1+ (0.5,0) [0|127.5] "" Vector__XXX
 SG_ BMS_a105_inletTemp m105 : 52|8@1+ (0.5,0) [0|127.5] "" Vector__XXX
 SG_ BMS_a106_minBrickT m106 : 16|8@1+ (0.5,0) [0|127.5] "" Vector__XXX
 SG_ BMS_a106_maxBrickT m106 : 24|8@1+ (0.5,0) [0|127.5] "" Vector__XXX
 SG_ BMS_a106_avgBrickT m106 : 32|8@1+ (0.5,0) [0|127.5] "" Vector__XXX
 SG_ BMS_a106_inletTemp m106 : 40|8@1+ (0.5,0) [0|127.5] "" Vector__XXX
 SG_ BMS_a107_MIA_numBadReadings m107 : 16|8@1+ (1,0) [0|255] "" Vector__XXX
 SG_ BMS_a107_MIA_numSnaReadings m107 : 24|8@1+ (1,0) [0|255] "" Vector__XXX
 SG_ BMS_a107_MIA_stackId m107 : 32|8@1+ (1,1) [1|256] "" Vector__XXX
 SG_ BMS_a109_muteMask m109 : 16|16@1+ (1,0) [0|65535] "" Vector__XXX
 SG_ BMS_a109_packInBleed m109 : 32|1@1+ (1,0) [0|1] "" Vector__XXX
 SG_ BMS_a117_brickID m117 : 16|7@1+ (1,1) [1|128] "" Vector__XXX
 SG_ BMS_a117_brickSoc2 m117 : 23|10@1+ (0.1,0) [0|102.3] "" Vector__XXX
 SG_ BMS_a117_dSocAlertThreshold m117 : 33|5@1+ (0.125,-4) [-4|-0.125] "" Vector__XXX
 SG_ BMS_a117_dSocAlpha m117 : 48|12@1+ (0.0030517578125,-12.4969482422) [-12.4969482422|-1.25002230789e-11] "" Vector__XXX
 SG_ BMS_a118_brickID m118 : 16|7@1+ (1,1) [1|128] "" Vector__XXX
 SG_ BMS_a118_brickSoc2 m118 : 23|10@1+ (0.1,0) [0|102.3] "" Vector__XXX
 SG_ BMS_a118_dSocAlertThreshold m118 : 33|5@1+ (0.125,-4) [-4|-0.125] "" Vector__XXX
 SG_ BMS_a118_dSocAlpha m118 : 48|12@1+ (0.0030517578125,-12.4969482422) [-12.4969482422|-1.25002230789e-11] "" Vector__XXX
 SG_ BMS_a122_thermistorID m122 : 16|5@1+ (1,1) [1|32] "" Vector__XXX
 SG_ BMS_a122_irrationalThermistorTem m122 : 24|8@1+ (0.5,-40) [-40|87.5] "" Vector__XXX
 SG_ BMS_a122_averageRawThermistorTem m122 : 32|8@1+ (0.5,-40) [-40|87.5] "" Vector__XXX
 SG_ BMS_a122_minRawThermistorTemp m122 : 40|8@1+ (0.5,-40) [-40|87.5] "" Vector__XXX
 SG_ BMS_a122_maxRawThermistorTemp m122 : 48|8@1+ (0.5,-40) [-40|87.5] "" Vector__XXX
 SG_ BMS_a122_numValidThermistors m122 : 56|5@1+ (1,0) [0|31] "" Vector__XXX
 SG_ BMS_a123_packPlus m123 : 32|8@1+ (4,0) [0|1020] "" Vector__XXX
 SG_ BMS_a123_isoR m123 : 40|10@1+ (10,0) [0|10230] "" Vector__XXX
 SG_ BMS_a123_packMinus m123 : 56|8@1- (4,0) [-512|508] "" Vector__XXX
 SG_ BMS_a129_brickID m129 : 16|8@1+ (1,1) [1|256] "" Vector__XXX
 SG_ BMS_a129_deltaV m129 : 24|16@1- (0.0002,0) [-6.5536|6.5534] "" Vector__XXX
 SG_ BMS_a129_retryCount m129 : 40|4@1+ (1,0) [0|15] "" Vector__XXX
 SG_ BMS_a131_brickID m131 : 16|8@1+ (1,1) [1|256] "" Vector__XXX
 SG_ BMS_a131_deltaV m131 : 24|16@1- (0.0002,0) [-6.5536|6.5534] "" Vector__XXX
 SG_ BMS_a131_retryCount m131 : 40|4@1+ (1,0) [0|15] "" Vector__XXX
 SG_ BMS_a132_multiVendorErrorMask m132 : 16|16@1+ (1,0) [0|65535] "" Vector__XXX
 SG_ BMS_a135_bmbDiagnosticsType m135 : 16|2@1+ (1,0) [0|3] "" Vector__XXX
 SG_ BMS_a135_bmbDeviceId m135 : 18|4@1+ (1,1) [1|16] "" Vector__XXX
 SG_ BMS_a135_readCVA m135 : 22|1@1+ (1,0) [0|1] "" Vector__XXX
 SG_ BMS_a135_readCVB m135 : 23|1@1+ (1,0) [0|1] "" Vector__XXX
 SG_ BMS_a135_readCVC m135 : 24|1@1+ (1,0) [0|1] "" Vector__XXX
 SG_ BMS_a135_readCVD m135 : 25|1@1+ (1,0) [0|1] "" Vector__XXX
 SG_ BMS_a135_readCVE m135 : 26|1@1+ (1,0) [0|1] "" Vector__XXX
 SG_ BMS_a135_readCVF m135 : 27|1@1+ (1,0) [0|1] "" Vector__XXX
 SG_ BMS_a135_readSNA m135 : 28|1@1+ (1,0) [0|1] "" Vector__XXX
 SG_ BMS_a135_readSNB m135 : 29|1@1+ (1,0) [0|1] "" Vector__XXX
 SG_ BMS_a135_readSNC m135 : 30|1@1+ (1,0) [0|1] "" Vector__XXX
 SG_ BMS_a135_readSND m135 : 31|1@1+ (1,0) [0|1] "" Vector__XXX
 SG_ BMS_a135_readSNE m135 : 32|1@1+ (1,0) [0|1] "" Vector__XXX
 SG_ BMS_a135_readSNF m135 : 33|1@1+ (1,0) [0|1] "" Vector__XXX
 SG_ BMS_a135_readAUXA m135 : 34|1@1+ (1,0) [0|1] "" Vector__XXX
 SG_ BMS_a135_readAUXB m135 : 35|1@1+ (1,0) [0|1] "" Vector__XXX
 SG_ BMS_a135_readSTAT m135 : 36|1@1+ (1,0) [0|1] "" Vector__XXX
 SG_ BMS_a136_maxBrickTID m136 : 16|5@1+ (1,1) [1|32] "" Vector__XXX
 SG_ BMS_a136_coolantInletT m136 : 24|8@1+ (0.4,-20) [-20|82] "" Vector__XXX
 SG_ BMS_a136_activeCoolingTarget m136 : 32|8@1+ (0.4,-20) [-20|82] "" Vector__XXX
 SG_ BMS_a136_maxBrickT m136 : 40|8@1+ (0.4,-20) [-20|82] "" Vector__XXX
 SG_ BMS_a139_packVoltage m139 : 16|16@1- (0.01,0) [-327.68|327.67] "" Vector__XXX
 SG_ BMS_a139_dcLinkVoltage m139 : 32|16@1+ (0.01,0) [0|655.35] "" Vector__XXX
 SG_ BMS_a140_bmbDeviceMask m140 : 16|16@1+ (1,0) [0|65535] "" Vector__XXX
 SG_ BMS_a140_faultType m140 : 32|8@1+ (1,0) [0|255] "" Vector__XXX
 SG_ BMS_a142_isolationResistance m142 : 16|10@1+ (10,0) [0|10230] "" Vector__XXX
 SG_ BMS_a142_mode m142 : 32|3@1+ (1,0) [0|7] "" Vector__XXX
 SG_ BMS_a143_initialSoc m143 : 16|9@1+ (0.2,0) [0|102.2] "" Vector__XXX
 SG_ BMS_a143_endingSoc m143 : 25|9@1+ (0.2,0) [0|102.2] "" Vector__XXX
 SG_ BMS_a143_deltaAh m143 : 34|9@1+ (0.5,0) [0|255.5] "" Vector__XXX
 SG_ BMS_a143_cacChangeBrickID m143 : 48|7@1+ (1,1) [1|128] "" Vector__XXX
 SG_ BMS_a143_cacUpdateError m143 : 56|8@1+ (0.1,0) [0|25.5] "" Vector__XXX
 SG_ BMS_a144_HVP_major_version m144 : 16|16@1+ (1,0) [0|65535] "" Vector__XXX
 SG_ BMS_a144_HVP_minor_version m144 : 32|16@1+ (1,0) [0|65535] "" Vector__XXX
 SG_ BMS_a144_BMS_minor_version m144 : 48|16@1+ (1,0) [0|65535] "" Vector__XXX
 SG_ BMS_a145_maxSocChange m145 : 16|11@1- (0.1,0) [-102.4|102.3] "" Vector__XXX
 SG_ BMS_a145_maxSocChangeBrickID m145 : 32|7@1+ (1,1) [1|128] "" Vector__XXX
 SG_ BMS_a145_numBricksChanged m145 : 40|7@1+ (1,0) [0|127] "" Vector__XXX
 SG_ BMS_a145_brickChangeHystRatio m145 : 48|10@1+ (0.001,0) [0|1.023] "" Vector__XXX
 SG_ BMS_a146_maxBrickV m146 : 16|8@1+ (0.01,2) [2|4.55] "" Vector__XXX
 SG_ BMS_a146_state m146 : 24|4@1+ (1,0) [0|15] "" Vector__XXX
 SG_ BMS_a146_packCurrent m146 : 32|8@1+ (8,-1496) [-1496|544] "" Vector__XXX
 SG_ BMS_a146_uvBrickVID m146 : 40|7@1+ (1,1) [1|128] "" Vector__XXX
 SG_ BMS_a146_uvBrickV m146 : 48|16@1+ (7.62939453125e-05,0) [0|4.99992370605] "" Vector__XXX
 SG_ BMS_a151_isoPositiveR m151 : 32|10@1+ (10,0) [0|10230] "" Vector__XXX
 SG_ BMS_a151_isoNegativeR m151 : 42|10@1+ (10,0) [0|10230] "" Vector__XXX
 SG_ BMS_a152_isoR m152 : 16|9@1+ (10,0) [0|5110] "" Vector__XXX
 SG_ BMS_a152_mode m152 : 25|3@1+ (1,0) [0|7] "" Vector__XXX
 SG_ BMS_a152_activeSideVNoR m152 : 28|9@1+ (1,0) [0|511] "" Vector__XXX
 SG_ BMS_a152_activeSideVWithR m152 : 37|9@1+ (1,0) [0|511] "" Vector__XXX
 SG_ BMS_a152_passiveSideVNoR m152 : 46|9@1+ (1,0) [0|511] "" Vector__XXX
 SG_ BMS_a152_passiveSideVWithR m152 : 55|9@1+ (1,0) [0|511] "" Vector__XXX
 SG_ BMS_a154_packCurrent m154 : 16|8@1+ (4,0) [0|1020] "" Vector__XXX
 SG_ BMS_a154_ovBrickVID m154 : 24|7@1+ (1,1) [1|128] "" Vector__XXX
 SG_ BMS_a154_ovBrickV m154 : 32|16@1+ (7.62939453125e-05,0) [0|4.99992370605] "" Vector__XXX
 SG_ BMS_a156_VrefSample m156 : 16|16@1+ (0.0001,0) [0|6.5535] "" Vector__XXX
 SG_ BMS_a156_bmbDeviceId m156 : 32|4@1+ (1,1) [1|16] "" Vector__XXX
 SG_ BMS_a156_VrefStatus m156 : 36|2@1+ (1,0) [0|3] "" Vector__XXX
 SG_ BMS_a158_shuntCurrentMia m158 : 16|1@1+ (1,0) [0|1] "" Vector__XXX
 SG_ BMS_a158_contactorStateMia m158 : 17|1@1+ (1,0) [0|1] "" Vector__XXX
 SG_ BMS_a158_hvpFaultsMia m158 : 18|1@1+ (1,0) [0|1] "" Vector__XXX
 SG_ BMS_a162_dischargePower_W m162 : 16|16@1- (1,0) [-32768|32767] "" Vector__XXX
 SG_ BMS_a162_minSoc m162 : 32|16@1+ (1,0) [0|65535] "" Vector__XXX
 SG_ BMS_a162_socThreshold m162 : 48|16@1+ (1,0) [0|65535] "" Vector__XXX
 SG_ BMS_a164_regenPower m164 : 16|32@1+ (1,0) [0|4294967295] "" Vector__XXX
 SG_ BMS_a165_packPositiveV m165 : 16|12@1- (0.25,0) [-512|511.75] "" Vector__XXX
 SG_ BMS_a165_packNegativeV m165 : 28|12@1- (0.25,0) [-512|511.75] "" Vector__XXX
 SG_ BMS_a165_dcLinkPositiveV m165 : 40|12@1- (0.25,0) [-512|511.75] "" Vector__XXX
 SG_ BMS_a165_dcLinkNegativeV m165 : 52|12@1- (0.25,0) [-512|511.75] "" Vector__XXX
 SG_ BMS_a166_packPositiveV m166 : 16|12@1- (0.25,0) [-512|511.75] "" Vector__XXX
 SG_ BMS_a166_packNegativeV m166 : 28|12@1- (0.25,0) [-512|511.75] "" Vector__XXX
 SG_ BMS_a166_dcLinkPositiveV m166 : 40|12@1- (0.25,0) [-512|511.75] "" Vector__XXX
 SG_ BMS_a166_dcLinkNegativeV m166 : 52|12@1- (0.25,0) [-512|511.75] "" Vector__XXX
 SG_ BMS_a167_fcContPositiveAuxOpen m167 : 16|1@1+ (1,0) [0|1] "" Vector__XXX
 SG_ BMS_a167_fcContNegativeAuxOpen m167 : 17|1@1+ (1,0) [0|1] "" Vector__XXX
 SG_ BMS_a167_dcLinkPositiveV m167 : 18|11@1- (0.5,0) [-512|511.5] "" Vector__XXX
 SG_ BMS_a167_dcLinkNegativeV m167 : 29|11@1- (0.5,0) [-512|511.5] "" Vector__XXX
 SG_ BMS_a167_fcLinkPositiveV m167 : 40|11@1- (0.5,0) [-512|511.5] "" Vector__XXX
 SG_ BMS_a167_fcLinkNegativeV m167 : 51|11@1- (0.5,0) [-512|511.5] "" Vector__XXX
 SG_ BMS_a168_fcContPositiveAuxOpen m168 : 16|1@1+ (1,0) [0|1] "" Vector__XXX
 SG_ BMS_a168_fcContNegativeAuxOpen m168 : 17|1@1+ (1,0) [0|1] "" Vector__XXX
 SG_ BMS_a168_dcLinkPositiveV m168 : 18|11@1- (0.5,0) [-512|511.5] "" Vector__XXX
 SG_ BMS_a168_dcLinkNegativeV m168 : 29|11@1- (0.5,0) [-512|511.5] "" Vector__XXX
 SG_ BMS_a168_fcLinkPositiveV m168 : 40|11@1- (0.5,0) [-512|511.5] "" Vector__XXX
 SG_ BMS_a168_fcLinkNegativeV m168 : 51|11@1- (0.5,0) [-512|511.5] "" Vector__XXX
 SG_ BMS_a169_DCAndFCContactorsWelded m169 : 16|1@1+ (1,0) [0|1] "" Vector__XXX
 SG_ BMS_a170_limpModeActive m170 : 16|1@1+ (1,0) [0|1] "" Vector__XXX
 SG_ BMS_a171_stackVoltage m171 : 16|16@1+ (0.00128,0) [0|83.8848] "" Vector__XXX
 SG_ BMS_a171_sumBrickVoltage m171 : 32|16@1+ (0.00128,0) [0|83.8848] "" Vector__XXX
 SG_ BMS_a171_stackId m171 : 48|8@1+ (1,1) [1|256] "" Vector__XXX
 SG_ BMS_a172_swIsolationCount m172 : 16|8@1+ (1,0) [0|255] "" Vector__XXX
 SG_ BMS_a177_energyAlertThreshold m177 : 16|10@1+ (0.1,0) [0|102.3] "" Vector__XXX
 SG_ BMS_a177_energyBuffer m177 : 26|10@1+ (0.1,0) [0|102.3] "" Vector__XXX
 SG_ BMS_a178_diPower m178 : 16|9@1- (4.3137254715,250.196075439) [-854.117645265|1350.19607067] "" Vector__XXX
 SG_ BMS_a178_energyError m178 : 25|8@1- (2,0) [-256|254] "" Vector__XXX
 SG_ BMS_a178_powerError m178 : 33|9@1- (1,0) [-256|255] "" Vector__XXX
 SG_ BMS_a178_minPowerError m178 : 42|9@1- (1,0) [-256|255] "" Vector__XXX
 SG_ BMS_a178_maxPowerError m178 : 51|9@1- (1,0) [-256|255] "" Vector__XXX
 SG_ BMS_a178_diMiaCount m178 : 60|2@1+ (1,0) [0|3] "" Vector__XXX
 SG_ BMS_a178_diSnaCount m178 : 62|2@1+ (1,0) [0|3] "" Vector__XXX
 SG_ BMS_a188_currentTripThreshold m188 : 16|16@1+ (0.0025,0) [0|163.8375] "" Vector__XXX
 SG_ BMS_a188_dcLinkDetectedCurrent m188 : 32|16@1+ (0.0025,0) [0|163.8375] "" Vector__XXX
 SG_ BMS_a189_currentTripThreshold m189 : 16|16@1- (0.0025,-75) [-156.92|6.9175] "" Vector__XXX
 SG_ BMS_a189_dcLinkDetectedCurrent m189 : 32|16@1- (0.0025,-75) [-156.92|6.9175] "" Vector__XXX
 SG_ BMS_a190_voltageTripThreshold m190 : 16|16@1+ (0.025,0) [0|1638.375] "" Vector__XXX
 SG_ BMS_a190_dcLinkDetectedVoltage m190 : 32|16@1+ (0.025,0) [0|1638.375] "" Vector__XXX
 SG_ BMS_a191_voltageTripThreshold m191 : 16|16@1+ (0.025,0) [0|1638.375] "" Vector__XXX
 SG_ BMS_a191_dcLinkDetectedVoltage m191 : 32|16@1+ (0.025,0) [0|1638.375] "" Vector__XXX
 SG_ BMS_a192_detectedChargeCurrent m192 : 16|16@1+ (0.0025,0) [0|163.8375] "" Vector__XXX
 SG_ BMS_a193_maxBrickVoltageLimit m193 : 16|12@1+ (0.001,1) [1|5.095] "" Vector__XXX
 SG_ BMS_a193_detectedMaxBrickVoltage m193 : 28|12@1+ (0.001,1) [1|5.095] "" Vector__XXX
 SG_ BMS_a201_maxBrickV m201 : 16|16@1+ (7.62939453125e-05,0) [0|4.99992370605] "" Vector__XXX
 SG_ BMS_a201_maxBrickVIndex m201 : 32|7@1+ (1,1) [1|128] "" Vector__XXX
 SG_ BMS_a227_packCurrent m227 : 16|16@1- (0.1,0) [-3276.8|3276.7] "" Vector__XXX
 SG_ BMS_a227_dcChargeCurrentRequest m227 : 32|16@1- (0.1,0) [-3276.8|3276.7] "" Vector__XXX
 SG_ BMS_a256_minBrickT m256 : 16|8@1- (0.5,24) [-40|87.5] "" Vector__XXX
 SG_ BMS_a256_maxBrickT m256 : 24|8@1- (0.5,24) [-40|87.5] "" Vector__XXX
 SG_ BMS_a256_minBrickV m256 : 32|8@1+ (0.01,2) [2|4.55] "" Vector__XXX
 SG_ BMS_a256_maxBrickV m256 : 40|8@1+ (0.01,2) [2|4.55] "" Vector__XXX
 SG_ BMS_a256_packSoe m256 : 48|8@1+ (0.393700778484,0) [0|100.393698513] "" Vector__XXX
 SG_ BMS_a256_SOC m256 : 56|8@1+ (0.05,0) [0|12.75] "" Vector__XXX

BO_ 800 BMS_alertMatrix: 8 BMS
 SG_ BMS_matrixIndex M : 0|4@1+ (1,0) [0|15] "" Vector__XXX
 SG_ BMS_a001_Pack_Config_Mismatch m0 : 4|1@1+ (1,0) [0|1] "" Vector__XXX
 SG_ BMS_a002_Pack_Performance_Config m0 : 5|1@1+ (1,0) [0|1] "" Vector__XXX
 SG_ BMS_a003_SW_Pack_Birth_Date_Miss m0 : 6|1@1+ (1,0) [0|1] "" Vector__XXX
 SG_ BMS_a004_Cal_Vs_Serial_Birth_Dat m0 : 7|1@1+ (1,0) [0|1] "" Vector__XXX
 SG_ BMS_a016_Pack_Module_Id_Mismatch m0 : 19|1@1+ (1,0) [0|1] "" Vector__XXX
 SG_ BMS_a017_SW_Brick_OV m0 : 20|1@1+ (1,0) [0|1] "" Vector__XXX
 SG_ BMS_a018_SW_Brick_UV m0 : 21|1@1+ (1,0) [0|1] "" Vector__XXX
 SG_ BMS_a019_SW_Module_OT m0 : 22|1@1+ (1,0) [0|1] "" Vector__XXX
 SG_ BMS_a020_SW_Brick_Instability m0 : 23|1@1+ (1,0) [0|1] "" Vector__XXX
 SG_ BMS_a021_SW_Dr_Limits_Regulation m0 : 24|1@1+ (1,0) [0|1] "" Vector__XXX
 SG_ BMS_a022_SW_Over_Current m0 : 25|1@1+ (1,0) [0|1] "" Vector__XXX
 SG_ BMS_a023_SW_Stack_OV m0 : 26|1@1+ (1,0) [0|1] "" Vector__XXX
 SG_ BMS_a024_SW_Islanded_Brick m0 : 27|1@1+ (1,0) [0|1] "" Vector__XXX
 SG_ BMS_a025_SW_PwrBalance_Anomaly m0 : 28|1@1+ (1,0) [0|1] "" Vector__XXX
 SG_ BMS_a026_SW_HFCurrent_Anomaly m0 : 29|1@1+ (1,0) [0|1] "" Vector__XXX
 SG_ BMS_a027_SW_Repeated_Isolation_F m0 : 30|1@1+ (1,0) [0|1] "" Vector__XXX
 SG_ BMS_a028_ShuntAsicCurrentOffsetD m0 : 31|1@1+ (1,0) [0|1] "" Vector__XXX
 SG_ BMS_a029_dSoc_Limiting m0 : 32|1@1+ (1,0) [0|1] "" Vector__XXX
 SG_ BMS_a030_Impedance_Deviation m0 : 33|1@1+ (1,0) [0|1] "" Vector__XXX
 SG_ BMS_a031_AlertsSetDuringSleep m0 : 34|1@1+ (1,0) [0|1] "" Vector__XXX
 SG_ BMS_a032_VoltageLoss m0 : 35|1@1+ (1,0) [0|1] "" Vector__XXX
 SG_ BMS_a033_VoltageDeviation m0 : 36|1@1+ (1,0) [0|1] "" Vector__XXX
 SG_ BMS_a034_SW_Passive_Isolation m0 : 37|1@1+ (1,0) [0|1] "" Vector__XXX
 SG_ BMS_a035_SW_Isolation m0 : 38|1@1+ (1,0) [0|1] "" Vector__XXX
 SG_ BMS_a036_SW_HvpHvilFault m0 : 39|1@1+ (1,0) [0|1] "" Vector__XXX
 SG_ BMS_a037_SW_Flood_Port_Open m0 : 40|1@1+ (1,0) [0|1] "" Vector__XXX
 SG_ BMS_a039_SW_DC_Link_Over_Voltage m0 : 42|1@1+ (1,0) [0|1] "" Vector__XXX
 SG_ BMS_a040_SW_Watch_Dog_HW_Trigger m0 : 43|1@1+ (1,0) [0|1] "" Vector__XXX
 SG_ BMS_a041_SW_Destructive_Reset_So m0 : 44|1@1+ (1,0) [0|1] "" Vector__XXX
 SG_ BMS_a042_SW_MPU_Error m0 : 45|1@1+ (1,0) [0|1] "" Vector__XXX
 SG_ BMS_a043_SW_Watch_Dog_Reset m0 : 46|1@1+ (1,0) [0|1] "" Vector__XXX
 SG_ BMS_a044_SW_Assertion m0 : 47|1@1+ (1,0) [0|1] "" Vector__XXX
 SG_ BMS_a045_SW_Exception m0 : 48|1@1+ (1,0) [0|1] "" Vector__XXX
 SG_ BMS_a046_SW_Task_Stack_Usage m0 : 49|1@1+ (1,0) [0|1] "" Vector__XXX
 SG_ BMS_a047_SW_Task_Stack_Overflow m0 : 50|1@1+ (1,0) [0|1] "" Vector__XXX
 SG_ BMS_a048_SW_Watch_Dog_Warning m0 : 51|1@1+ (1,0) [0|1] "" Vector__XXX
 SG_ BMS_a049_SW_Thermal_Event m0 : 52|1@1+ (1,0) [0|1] "" Vector__XXX
 SG_ BMS_a050_SW_Brick_Voltage_MIA m0 : 53|1@1+ (1,0) [0|1] "" Vector__XXX
 SG_ BMS_a051_SW_HVC_Vref_Bad m0 : 54|1@1+ (1,0) [0|1] "" Vector__XXX
 SG_ BMS_a052_SW_PCS_MIA m0 : 55|1@1+ (1,0) [0|1] "" Vector__XXX
 SG_ BMS_a054_SW_Ver_Supply_Fault m0 : 57|1@1+ (1,0) [0|1] "" Vector__XXX
 SG_ BMS_a055_SW_HvChain_Model_Fault m0 : 58|1@1+ (1,0) [0|1] "" Vector__XXX
 SG_ BMS_a056_SW_Standby_Supply_Fault m0 : 59|1@1+ (1,0) [0|1] "" Vector__XXX
 SG_ BMS_a057_SW_Bandolier_Model_Warn m0 : 60|1@1+ (1,0) [0|1] "" Vector__XXX
 SG_ BMS_a058_SW_Bandolier_Model_Rese m0 : 61|1@1+ (1,0) [0|1] "" Vector__XXX
 SG_ BMS_a059_SW_Pack_Voltage_Sensing m0 : 62|1@1+ (1,0) [0|1] "" Vector__XXX
 SG_ BMS_a060_SW_Leakage_Test_Failure m0 : 63|1@1+ (1,0) [0|1] "" Vector__XXX
 SG_ BMS_a061_SW_BrickV_Change m1 : 4|1@1+ (1,0) [0|1] "" Vector__XXX
 SG_ BMS_a062_SW_BrickV_Imbalance m1 : 5|1@1+ (1,0) [0|1] "" Vector__XXX
 SG_ BMS_a063_SW_ChargePort_Fault m1 : 6|1@1+ (1,0) [0|1] "" Vector__XXX
 SG_ BMS_a064_SW_SOC_Imbalance m1 : 7|1@1+ (1,0) [0|1] "" Vector__XXX
 SG_ BMS_a065_SW_CAC_Imbalance m1 : 8|1@1+ (1,0) [0|1] "" Vector__XXX
 SG_ BMS_a066_SOC_Imbalance_Warning m1 : 9|1@1+ (1,0) [0|1] "" Vector__XXX
 SG_ BMS_a067_CAC_Imbalance_Limiting m1 : 10|1@1+ (1,0) [0|1] "" Vector__XXX
 SG_ BMS_a068_CAC_Imbalance_Limp m1 : 11|1@1+ (1,0) [0|1] "" Vector__XXX
 SG_ BMS_a069_SW_Low_Power m1 : 12|1@1+ (1,0) [0|1] "" Vector__XXX
 SG_ BMS_a070_BrickV_Imbalance_Limiti m1 : 13|1@1+ (1,0) [0|1] "" Vector__XXX
 SG_ BMS_a071_SW_SM_TransCon_Not_Met m1 : 14|1@1+ (1,0) [0|1] "" Vector__XXX
 SG_ BMS_a072_Module_Brick_Split m1 : 15|1@1+ (1,0) [0|1] "" Vector__XXX
 SG_ BMS_a073_Unexpected_Loss_Of_Lv m1 : 16|1@1+ (1,0) [0|1] "" Vector__XXX
 SG_ BMS_a074_Max_Charge_Level_Reduce m1 : 17|1@1+ (1,0) [0|1] "" Vector__XXX
 SG_ BMS_a075_SW_Chg_Disable_Failure m1 : 18|1@1+ (1,0) [0|1] "" Vector__XXX
 SG_ BMS_a076_SW_Dch_While_Charging m1 : 19|1@1+ (1,0) [0|1] "" Vector__XXX
 SG_ BMS_a077_SW_Charger_Regulation m1 : 20|1@1+ (1,0) [0|1] "" Vector__XXX
 SG_ BMS_a078_Rapid_Dch_While_Chargin m1 : 21|1@1+ (1,0) [0|1] "" Vector__XXX
 SG_ BMS_a079_Max_Charge_Level_Exceed m1 : 22|1@1+ (1,0) [0|1] "" Vector__XXX
 SG_ BMS_a080_SW_Pack_Ctr_Impedance m1 : 23|1@1+ (1,0) [0|1] "" Vector__XXX
 SG_ BMS_a081_SW_Ctr_Close_Blocked m1 : 24|1@1+ (1,0) [0|1] "" Vector__XXX
 SG_ BMS_a082_SW_Ctr_Force_Open m1 : 25|1@1+ (1,0) [0|1] "" Vector__XXX
 SG_ BMS_a083_SW_Ctr_Close_Failure m1 : 26|1@1+ (1,0) [0|1] "" Vector__XXX
 SG_ BMS_a084_SW_Sleep_Wake_Aborted m1 : 27|1@1+ (1,0) [0|1] "" Vector__XXX
 SG_ BMS_a085_SW_Pack_Contactor_Misma m1 : 28|1@1+ (1,0) [0|1] "" Vector__XXX
 SG_ BMS_a086_SW_FC_Contactor_Mismatc m1 : 29|1@1+ (1,0) [0|1] "" Vector__XXX
 SG_ BMS_a087_SW_Feim_Test_Blocked m1 : 30|1@1+ (1,0) [0|1] "" Vector__XXX
 SG_ BMS_a088_SW_VcFront_MIA_InDrive m1 : 31|1@1+ (1,0) [0|1] "" Vector__XXX
 SG_ BMS_a089_SW_VcFront_MIA m1 : 32|1@1+ (1,0) [0|1] "" Vector__XXX
 SG_ BMS_a090_SW_Gateway_MIA m1 : 33|1@1+ (1,0) [0|1] "" Vector__XXX
 SG_ BMS_a091_SW_ChargePort_MIA m1 : 34|1@1+ (1,0) [0|1] "" Vector__XXX
 SG_ BMS_a092_SW_ChargePort_Mia_On_Hv m1 : 35|1@1+ (1,0) [0|1] "" Vector__XXX
 SG_ BMS_a094_SW_Drive_Inverter_MIA m1 : 37|1@1+ (1,0) [0|1] "" Vector__XXX
 SG_ BMS_a095_SW_UI_MIA m1 : 38|1@1+ (1,0) [0|1] "" Vector__XXX
 SG_ BMS_a097_SW_BMB_Over_CAN_Communi m1 : 40|1@1+ (1,0) [0|1] "" Vector__XXX
 SG_ BMS_a098_SW_BMB_Data_Integrity_L m1 : 41|1@1+ (1,0) [0|1] "" Vector__XXX
 SG_ BMS_a099_SW_BMB_Communication m1 : 42|1@1+ (1,0) [0|1] "" Vector__XXX
 SG_ BMS_a100_ThermalEventSuspected m1 : 43|1@1+ (1,0) [0|1] "" Vector__XXX
 SG_ BMS_a105_SW_One_Module_Tsense m1 : 48|1@1+ (1,0) [0|1] "" Vector__XXX
 SG_ BMS_a106_SW_All_Module_Tsense m1 : 49|1@1+ (1,0) [0|1] "" Vector__XXX
 SG_ BMS_a107_SW_Stack_Voltage_MIA m1 : 50|1@1+ (1,0) [0|1] "" Vector__XXX
 SG_ BMS_a108_SW_BMB_Device_OT m1 : 51|1@1+ (1,0) [0|1] "" Vector__XXX
 SG_ BMS_a109_HW_BMB_Mute_Status_Mism m1 : 52|1@1+ (1,0) [0|1] "" Vector__XXX
 SG_ BMS_a110_LifeModel_AvgOffset_Cha m1 : 53|1@1+ (1,0) [0|1] "" Vector__XXX
 SG_ BMS_a111_LifeModel_Spread_Change m1 : 54|1@1+ (1,0) [0|1] "" Vector__XXX
 SG_ BMS_a112_LifeModel_Discontinuity m1 : 55|1@1+ (1,0) [0|1] "" Vector__XXX
 SG_ BMS_a115_Energy_Rubberbanding_Re m1 : 58|1@1+ (1,0) [0|1] "" Vector__XXX
 SG_ BMS_a117_SW_Delta_SOC_Weak_Short m1 : 60|1@1+ (1,0) [0|1] "" Vector__XXX
 SG_ BMS_a118_SW_Delta_SOC_Weak_Short m1 : 61|1@1+ (1,0) [0|1] "" Vector__XXX
 SG_ BMS_a119_Fast_Open_Vsh_Detected m1 : 62|1@1+ (1,0) [0|1] "" Vector__XXX
 SG_ BMS_a120_SW_Delta_SOC_User_Warni m1 : 63|1@1+ (1,0) [0|1] "" Vector__XXX
 SG_ BMS_a121_SW_NVRAM_Config_Error m2 : 4|1@1+ (1,0) [0|1] "" Vector__XXX
 SG_ BMS_a122_SW_BMS_Therm_Irrational m2 : 5|1@1+ (1,0) [0|1] "" Vector__XXX
 SG_ BMS_a123_SW_Internal_Isolation m2 : 6|1@1+ (1,0) [0|1] "" Vector__XXX
 SG_ BMS_a124_Battery_Coolant_Flood m2 : 7|1@1+ (1,0) [0|1] "" Vector__XXX
 SG_ BMS_a126_SW_Thermistor_Failure m2 : 9|1@1+ (1,0) [0|1] "" Vector__XXX
 SG_ BMS_a127_SW_shunt_SNA m2 : 10|1@1+ (1,0) [0|1] "" Vector__XXX
 SG_ BMS_a128_SW_shunt_MIA m2 : 11|1@1+ (1,0) [0|1] "" Vector__XXX
 SG_ BMS_a129_SW_VSH_Failure m2 : 12|1@1+ (1,0) [0|1] "" Vector__XXX
 SG_ BMS_a130_IO_CAN_Error m2 : 13|1@1+ (1,0) [0|1] "" Vector__XXX
 SG_ BMS_a131_Bleed_FET_Failure m2 : 14|1@1+ (1,0) [0|1] "" Vector__XXX
 SG_ BMS_a132_HW_BMB_OTP_Uncorrctbl m2 : 15|1@1+ (1,0) [0|1] "" Vector__XXX
 SG_ BMS_a133_IO_CAN_Bus_Off m2 : 16|1@1+ (1,0) [0|1] "" Vector__XXX
 SG_ BMS_a134_SW_Delayed_Ctr_Off m2 : 17|1@1+ (1,0) [0|1] "" Vector__XXX
 SG_ BMS_a135_HW_BMB_Diagnostics_Fail m2 : 18|1@1+ (1,0) [0|1] "" Vector__XXX
 SG_ BMS_a136_SW_Module_OT_Warning m2 : 19|1@1+ (1,0) [0|1] "" Vector__XXX
 SG_ BMS_a137_SW_Brick_UV_Warning m2 : 20|1@1+ (1,0) [0|1] "" Vector__XXX
 SG_ BMS_a138_SW_Brick_OV_Warning m2 : 21|1@1+ (1,0) [0|1] "" Vector__XXX
 SG_ BMS_a139_SW_DC_Link_V_Irrational m2 : 22|1@1+ (1,0) [0|1] "" Vector__XXX
 SG_ BMS_a140_HW_BMB_Status_Fault m2 : 23|1@1+ (1,0) [0|1] "" Vector__XXX
 SG_ BMS_a141_SW_BMB_Status_Warning m2 : 24|1@1+ (1,0) [0|1] "" Vector__XXX
 SG_ BMS_a142_SW_Isolation_Degradatio m2 : 25|1@1+ (1,0) [0|1] "" Vector__XXX
 SG_ BMS_a143_SW_CAC_Change m2 : 26|1@1+ (1,0) [0|1] "" Vector__XXX
 SG_ BMS_a144_Hvp_Config_Mismatch m2 : 27|1@1+ (1,0) [0|1] "" Vector__XXX
 SG_ BMS_a145_SW_SOC_Change m2 : 28|1@1+ (1,0) [0|1] "" Vector__XXX
 SG_ BMS_a146_SW_Brick_Overdischarged m2 : 29|1@1+ (1,0) [0|1] "" Vector__XXX
 SG_ BMS_a147_SW_SOC_High_Ah_Error m2 : 30|1@1+ (1,0) [0|1] "" Vector__XXX
 SG_ BMS_a148_SW_Unsupported_BMB_ASIC m2 : 31|1@1+ (1,0) [0|1] "" Vector__XXX
 SG_ BMS_a149_SW_Missing_Config_Block m2 : 32|1@1+ (1,0) [0|1] "" Vector__XXX
 SG_ BMS_a150_SW_Missing_Part_Number m2 : 33|1@1+ (1,0) [0|1] "" Vector__XXX
 SG_ BMS_a151_SW_external_isolation m2 : 34|1@1+ (1,0) [0|1] "" Vector__XXX
 SG_ BMS_a152_Isolation_In_Dc_Charge m2 : 35|1@1+ (1,0) [0|1] "" Vector__XXX
 SG_ BMS_a153_GridFormFaulted m2 : 36|1@1+ (1,0) [0|1] "" Vector__XXX
 SG_ BMS_a154_SW_Brick_OV_Warning_Sto m2 : 37|1@1+ (1,0) [0|1] "" Vector__XXX
 SG_ BMS_a155_SW_Weak_short_impedence m2 : 38|1@1+ (1,0) [0|1] "" Vector__XXX
 SG_ BMS_a156_SW_BMB_Vref_bad m2 : 39|1@1+ (1,0) [0|1] "" Vector__XXX
 SG_ BMS_a157_SW_Hist_Update_Missed m2 : 40|1@1+ (1,0) [0|1] "" Vector__XXX
 SG_ BMS_a158_SW_HVP_HVI_Comms m2 : 41|1@1+ (1,0) [0|1] "" Vector__XXX
 SG_ BMS_a159_SW_HVP_ECU_Error m2 : 42|1@1+ (1,0) [0|1] "" Vector__XXX
 SG_ BMS_a160_SW_FC_Ctr_Clean_Failed m2 : 43|1@1+ (1,0) [0|1] "" Vector__XXX
 SG_ BMS_a161_SW_BMB_Vref_warning m2 : 44|1@1+ (1,0) [0|1] "" Vector__XXX
 SG_ BMS_a162_SW_No_Power_For_Support m2 : 45|1@1+ (1,0) [0|1] "" Vector__XXX
 SG_ BMS_a163_GridFormAborted m2 : 46|1@1+ (1,0) [0|1] "" Vector__XXX
 SG_ BMS_a164_SW_Uncontrolled_Regen m2 : 47|1@1+ (1,0) [0|1] "" Vector__XXX
 SG_ BMS_a165_SW_Pack_Partial_Weld m2 : 48|1@1+ (1,0) [0|1] "" Vector__XXX
 SG_ BMS_a166_SW_Pack_Full_Weld m2 : 49|1@1+ (1,0) [0|1] "" Vector__XXX
 SG_ BMS_a167_SW_FC_Partial_Weld m2 : 50|1@1+ (1,0) [0|1] "" Vector__XXX
 SG_ BMS_a168_SW_FC_Full_Weld m2 : 51|1@1+ (1,0) [0|1] "" Vector__XXX
 SG_ BMS_a169_SW_FC_Pack_Weld m2 : 52|1@1+ (1,0) [0|1] "" Vector__XXX
 SG_ BMS_a170_SW_Limp_Mode m2 : 53|1@1+ (1,0) [0|1] "" Vector__XXX
 SG_ BMS_a171_SW_Stack_Voltage_Sense m2 : 54|1@1+ (1,0) [0|1] "" Vector__XXX
 SG_ BMS_a172_SW_Isolation_Failure_In m2 : 55|1@1+ (1,0) [0|1] "" Vector__XXX
 SG_ BMS_a173_FullPackEnergyDegraded m2 : 56|1@1+ (1,0) [0|1] "" Vector__XXX
 SG_ BMS_a174_SW_Charge_Failure m2 : 57|1@1+ (1,0) [0|1] "" Vector__XXX
 SG_ BMS_a175_Charge_Failure_External m2 : 58|1@1+ (1,0) [0|1] "" Vector__XXX
 SG_ BMS_a176_SW_GracefulPowerOff m2 : 59|1@1+ (1,0) [0|1] "" Vector__XXX
 SG_ BMS_a177_SW_Energy_Buffer_Size m2 : 60|1@1+ (1,0) [0|1] "" Vector__XXX
 SG_ BMS_a178_SW_Uncontrolled_Regen_P m2 : 61|1@1+ (1,0) [0|1] "" Vector__XXX
 SG_ BMS_a179_HvpGpoRequestActive m2 : 62|1@1+ (1,0) [0|1] "" Vector__XXX
 SG_ BMS_a180_SW_ECU_reset_blocked m2 : 63|1@1+ (1,0) [0|1] "" Vector__XXX
 SG_ BMS_a181_SW_Shunt_Over_Temperatu m3 : 4|1@1+ (1,0) [0|1] "" Vector__XXX
 SG_ BMS_a182_LifeModel_NoCurrentLoss m3 : 5|1@1+ (1,0) [0|1] "" Vector__XXX
 SG_ BMS_a183_LifeModel_StoDcrGrowth_ m3 : 6|1@1+ (1,0) [0|1] "" Vector__XXX
 SG_ BMS_a184_LifeModel_CyclingLoss_C m3 : 7|1@1+ (1,0) [0|1] "" Vector__XXX
 SG_ BMS_a185_LifeModel_CyclingDcrGro m3 : 8|1@1+ (1,0) [0|1] "" Vector__XXX
 SG_ BMS_a186_RippleHeatingChargeFaul m3 : 9|1@1+ (1,0) [0|1] "" Vector__XXX
 SG_ BMS_a187_RippleHeatingEmergencyS m3 : 10|1@1+ (1,0) [0|1] "" Vector__XXX
 SG_ BMS_a188_PowershareChargeCurrent m3 : 11|1@1+ (1,0) [0|1] "" Vector__XXX
 SG_ BMS_a189_PowershareDischargeCurr m3 : 12|1@1+ (1,0) [0|1] "" Vector__XXX
 SG_ BMS_a190_PowershareMaxVoltageVio m3 : 13|1@1+ (1,0) [0|1] "" Vector__XXX
 SG_ BMS_a191_PowershareMinVoltageVio m3 : 14|1@1+ (1,0) [0|1] "" Vector__XXX
 SG_ BMS_a192_PowershareExternalCharg m3 : 15|1@1+ (1,0) [0|1] "" Vector__XXX
 SG_ BMS_a193_PowershareMaxBrickVolta m3 : 16|1@1+ (1,0) [0|1] "" Vector__XXX
 SG_ BMS_a194_PowershareLimitViolatio m3 : 17|1@1+ (1,0) [0|1] "" Vector__XXX
 SG_ BMS_a195_SW_DeltaTempOverThresho m3 : 18|1@1+ (1,0) [0|1] "" Vector__XXX
 SG_ BMS_a196_SW_PackVoltageUnderThre m3 : 19|1@1+ (1,0) [0|1] "" Vector__XXX
 SG_ BMS_a197_SW_High_SOC_OV m3 : 20|1@1+ (1,0) [0|1] "" Vector__XXX
 SG_ BMS_a198_SW_SOC_Abrupt_Change m3 : 21|1@1+ (1,0) [0|1] "" Vector__XXX
 SG_ BMS_a199_GridFollowAborted m3 : 22|1@1+ (1,0) [0|1] "" Vector__XXX
 SG_ BMS_a200_GridFollowFaulted m3 : 23|1@1+ (1,0) [0|1] "" Vector__XXX
 SG_ BMS_a201_SW_Brick_OV_During_Char m3 : 24|1@1+ (1,0) [0|1] "" Vector__XXX
 SG_ BMS_a202_AcChargeFaulted m3 : 25|1@1+ (1,0) [0|1] "" Vector__XXX
 SG_ BMS_a204_AcCpEmergencyShutdownRe m3 : 27|1@1+ (1,0) [0|1] "" Vector__XXX
 SG_ BMS_a214_AcChargeAborted m3 : 37|1@1+ (1,0) [0|1] "" Vector__XXX
 SG_ BMS_a221_PcsEmergencyShutdownReq m3 : 44|1@1+ (1,0) [0|1] "" Vector__XXX
 SG_ BMS_a227_ExcessChargeCurrentInCh m3 : 50|1@1+ (1,0) [0|1] "" Vector__XXX
 SG_ BMS_a254_LdcsCacImbalance m4 : 17|1@1+ (1,0) [0|1] "" Vector__XXX
 SG_ BMS_a255_EstimatedRangeReduced m4 : 18|1@1+ (1,0) [0|1] "" Vector__XXX
 SG_ BMS_a256_SW_Low_Power_Warning m4 : 19|1@1+ (1,0) [0|1] "" Vector__XXX
 SG_ BMS_d257_internalIsolationFault m4 : 20|1@1+ (1,0) [0|1] "" Vector__XXX
 SG_ BMS_d258_externalIsolationFault m4 : 21|1@1+ (1,0) [0|1] "" Vector__XXX
 SG_ BMS_d259_highVoltageInterlockFai m4 : 22|1@1+ (1,0) [0|1] "" Vector__XXX
 SG_ BMS_d260_chargePortInterlockFail m4 : 23|1@1+ (1,0) [0|1] "" Vector__XXX
 SG_ BMS_d261_batteryPackCellVoltageH m4 : 24|1@1+ (1,0) [0|1] "" Vector__XXX
 SG_ BMS_d262_batteryPackLowStateOfCh m4 : 25|1@1+ (1,0) [0|1] "" Vector__XXX
 SG_ BMS_d263_batterySystemCurrentHig m4 : 26|1@1+ (1,0) [0|1] "" Vector__XXX
 SG_ BMS_d264_invalidFirmwareConfig m4 : 27|1@1+ (1,0) [0|1] "" Vector__XXX
 SG_ BMS_d265_replaceBatteryPack m4 : 28|1@1+ (1,0) [0|1] "" Vector__XXX
 SG_ BMS_d266_energyReserveVoltageLow m4 : 29|1@1+ (1,0) [0|1] "" Vector__XXX
 SG_ BMS_d267_batteryPackCellVoltageS m4 : 30|1@1+ (1,0) [0|1] "" Vector__XXX
 SG_ BMS_d268_hvpInvalidFirmwareConfi m4 : 31|1@1+ (1,0) [0|1] "" Vector__XXX
 SG_ BMS_d269_highVoltageFuseABlown m4 : 32|1@1+ (1,0) [0|1] "" Vector__XXX
 SG_ BMS_d270_hvpCommsLost m4 : 33|1@1+ (1,0) [0|1] "" Vector__XXX
 SG_ BMS_d271_batteryPackSensorFailur m4 : 34|1@1+ (1,0) [0|1] "" Vector__XXX
 SG_ BMS_d272_batteryPackSensorCommsL m4 : 35|1@1+ (1,0) [0|1] "" Vector__XXX
 SG_ BMS_d273_vcFrontCommsLost m4 : 36|1@1+ (1,0) [0|1] "" Vector__XXX
 SG_ BMS_d274_packCurrentSensorACircu m4 : 37|1@1+ (1,0) [0|1] "" Vector__XXX
 SG_ BMS_d275_packPosContactorACircui m4 : 38|1@1+ (1,0) [0|1] "" Vector__XXX
 SG_ BMS_d276_packPosContactorAStuckC m4 : 39|1@1+ (1,0) [0|1] "" Vector__XXX
 SG_ BMS_d277_packNegContactorACircui m4 : 40|1@1+ (1,0) [0|1] "" Vector__XXX
 SG_ BMS_d278_packNegContactorAStuckC m4 : 41|1@1+ (1,0) [0|1] "" Vector__XXX
 SG_ BMS_d279_fastChargePosContactorA m4 : 42|1@1+ (1,0) [0|1] "" Vector__XXX
 SG_ BMS_d280_fastChargePosContactorA m4 : 43|1@1+ (1,0) [0|1] "" Vector__XXX
 SG_ BMS_d281_fastChargePosContactorA m4 : 44|1@1+ (1,0) [0|1] "" Vector__XXX
 SG_ BMS_d282_fastChargeNegContactorA m4 : 45|1@1+ (1,0) [0|1] "" Vector__XXX
 SG_ BMS_d283_fastChargeNegContactorA m4 : 46|1@1+ (1,0) [0|1] "" Vector__XXX
 SG_ BMS_d284_fastChargeNegContactorA m4 : 47|1@1+ (1,0) [0|1] "" Vector__XXX
 SG_ BMS_d285_packVoltageSensorACircu m4 : 48|1@1+ (1,0) [0|1] "" Vector__XXX
 SG_ BMS_d286_dcLinkVoltageHigh m4 : 49|1@1+ (1,0) [0|1] "" Vector__XXX
 SG_ BMS_d287_systemIsolationWarning m4 : 50|1@1+ (1,0) [0|1] "" Vector__XXX
 SG_ BMS_d288_batteryPackCellVoltageL m4 : 51|1@1+ (1,0) [0|1] "" Vector__XXX
 SG_ BMS_d289_batteryPackAOverTempera m4 : 52|1@1+ (1,0) [0|1] "" Vector__XXX
 SG_ BMS_d290_batteryPackTempSensorAC m4 : 53|1@1+ (1,0) [0|1] "" Vector__XXX
 SG_ BMS_a291_SOC_Imbalance_By_Delta_ m4 : 54|1@1+ (1,0) [0|1] "" Vector__XXX
 SG_ BMS_a299_PowershareFailure m4 : 62|1@1+ (1,0) [0|1] "" Vector__XXX

BO_ 818 BMS_bmbMinMax: 8 BMS
 SG_ BMS_bmbMinMaxMultiplexer M : 0|2@1+ (1,0) [0|3] "" Vector__XXX
 SG_ BMS_thermistorNumTMin m0 : 2|4@1+ (1,0) [0|15] "" Vector__XXX
 SG_ BMS_thermistorNumTMax m0 : 8|4@1+ (1,0) [0|15] "" Vector__XXX
 SG_ BMS_thermistorTMax m0 : 16|8@1+ (0.5,-40) [-40|87.5] "DegC" Vector__XXX
 SG_ BMS_thermistorTMin m0 : 24|8@1+ (0.5,-40) [-40|87.5] "DegC" Vector__XXX
 SG_ BMS_thermistorTAvg m0 : 32|8@1+ (0.5,-40) [-40|87.5] "DegC" Vector__XXX
 SG_ BMS_brickVoltageMax m1 : 2|12@1+ (0.002,0) [0|5] "V" Vector__XXX
 SG_ BMS_brickVoltageMin m1 : 16|12@1+ (0.002,0) [0|5] "V" Vector__XXX
 SG_ BMS_brickNumVoltageMax m1 : 32|7@1+ (1,1) [1|128] "" Vector__XXX
 SG_ BMS_brickNumVoltageMin m1 : 40|7@1+ (1,1) [1|128] "" Vector__XXX

CM_ BO_ 811 "Driver assistance computer (secondary) message: warning matrix0";
CM_ SG_ 811 APS_w001_DEPRECATED "Driver assistance computer (secondary): w001 DEPRECATED";
CM_ SG_ 811 APS_w002_ldwDisabled "Driver assistance computer (secondary): w002 ldw disabled";
CM_ SG_ 811 APS_w003_isaDisabled "Driver assistance computer (secondary): w003 isa disabled";
CM_ SG_ 811 APS_w004_accDisabled "Driver assistance computer (secondary): w004 acc disabled";
CM_ SG_ 811 APS_w005_fcwCancelled "Driver assistance computer (secondary): w005 fcw cancelled";
CM_ SG_ 811 APS_w006_aebCancelled "Driver assistance computer (secondary): w006 aeb cancelled";
CM_ SG_ 811 APS_w007_ahlbDisabled "Driver assistance computer (secondary): w007 ahlb disabled";
CM_ SG_ 811 APS_w008_parkDisabled "Driver assistance computer (secondary): w008 park disabled";
CM_ SG_ 811 APS_w009_aebFault "Driver assistance computer (secondary): w009 aeb fault";
CM_ SG_ 811 APS_w010_radcCalibIssue "Driver assistance computer (secondary): w010 radc calib issue";
CM_ SG_ 811 APS_w011_scaEvent "Driver assistance computer (secondary): w011 sca event";
CM_ SG_ 811 APS_w012_Cam_BootFailure "Driver assistance computer (secondary): w012 cam boot failure";
CM_ SG_ 811 APS_w013_Cam_Watchdog "Driver assistance computer (secondary): w013 cam watchdog";
CM_ SG_ 811 APS_w014_swAssert "Driver assistance computer (secondary): w014 sw assert";
CM_ SG_ 811 APS_w015_Camera_Failsafes "Driver assistance computer (secondary): w015 camera failsafes";
CM_ SG_ 811 APS_w016_aeb_e_event "Driver assistance computer (secondary): w016 aeb e event";
CM_ SG_ 811 APS_w017_Cam_Msg_MIA "Driver assistance computer (secondary): w017 cam msg MIA";
CM_ SG_ 811 APS_w018_ECU_Power_Issue "Driver assistance computer (secondary): w018 ECU power issue";
CM_ SG_ 811 APS_w019_ECU_Stack_Overflow "Driver assistance computer (secondary): w019 ECU stack overflow";
CM_ SG_ 811 APS_w020_ECU_checkstopError "Driver assistance computer (secondary): w020 ECU checkstop error";
CM_ SG_ 811 APS_w021_ECU_Temperature_Issue "Driver assistance computer (secondary): w021 ECU temperature issue";
CM_ SG_ 811 APS_w022_ECU_EEPROM_Failure "Driver assistance computer (secondary): w022 ECU EEPROM failure";
CM_ SG_ 811 APS_w023_ECU_Cam_Statemismatc "Driver assistance computer (secondary): w023 ECU cam statemismatc";
CM_ SG_ 811 APS_w024_ECU_Watchdog_Reset "Driver assistance computer (secondary): w024 ECU watchdog reset";
CM_ SG_ 811 APS_w025_LC_Steering_Override "Driver assistance computer (secondary): w025 LC steering override";
CM_ SG_ 811 APS_w026_ECU_timingIssue "Driver assistance computer (secondary): w026 ECU timing issue";
CM_ SG_ 811 APS_w027_ECU_Reset_Fault "Driver assistance computer (secondary): w027 ECU reset fault";
CM_ SG_ 811 APS_w028_spi_rx_error "Driver assistance computer (secondary): w028 spi rx error";
CM_ SG_ 811 APS_w029_spi_tx_error "Driver assistance computer (secondary): w029 spi tx error";
CM_ SG_ 811 APS_w030_Heater_Issue "Driver assistance computer (secondary): w030 heater issue";
CM_ SG_ 811 APS_w031_canRxError "Driver assistance computer (secondary): w031 can rx error";
CM_ SG_ 811 APS_w032_canTxError "Driver assistance computer (secondary): w032 can tx error";
CM_ SG_ 811 APS_w033_gtwMia "Driver assistance computer (secondary): w033 gtw mia";
CM_ SG_ 811 APS_w034_sccmMia "Driver assistance computer (secondary): w034 sccm mia";
CM_ SG_ 811 APS_w035_espMia "Driver assistance computer (secondary): w035 esp mia";
CM_ SG_ 811 APS_w036_bdyMia "Driver assistance computer (secondary): w036 bdy mia";
CM_ SG_ 811 APS_w037_camTacIssue "Driver assistance computer (secondary): w037 cam tac issue";
CM_ SG_ 811 APS_w038_camFailure "Driver assistance computer (secondary): w038 cam failure";
CM_ SG_ 811 APS_w039_sdm_rcm_Mia "Driver assistance computer (secondary): w039 sdm rcm mia";
CM_ SG_ 811 APS_w040_autopilotAngleSaturated "Driver assistance computer (secondary): w040 autopilot angle saturated";
CM_ SG_ 811 APS_w041_autopilotRateSaturated "Driver assistance computer (secondary): w041 autopilot rate saturated";
CM_ SG_ 811 APS_w042_autopilotAborting "Driver assistance computer (secondary): w042 autopilot aborting";
CM_ SG_ 811 APS_w043_camLongRunTime "Driver assistance computer (secondary): w043 cam long run time";
CM_ SG_ 811 APS_w044_appMobileyeFailure "Driver assistance computer (secondary): w044 app mobileye failure";
CM_ SG_ 811 APS_w045_radMia "Driver assistance computer (secondary): w045 rad mia";
CM_ SG_ 811 APS_w046_eepromRecordAbsent "Driver assistance computer (secondary): w046 eeprom record absent";
CM_ SG_ 811 APS_w047_edrEvent "Driver assistance computer (secondary): w047 edr event";
CM_ SG_ 811 APS_w048_DAS_Features_Disabled "Driver assistance computer (secondary): w048 DAS features disabled";
CM_ SG_ 811 APS_w049_eyeqVersionMismatch "Driver assistance computer (secondary): w049 eyeq version mismatch";
CM_ SG_ 811 APS_w050_aeb_event "Driver assistance computer (secondary): w050 aeb event";
CM_ SG_ 811 APS_w051_radcEcuIssue "Driver assistance computer (secondary): w051 radc ecu issue";
CM_ SG_ 811 APS_w052_radcSensorIssue "Driver assistance computer (secondary): w052 radc sensor issue";
CM_ SG_ 811 APS_w053_radcCommIssue "Driver assistance computer (secondary): w053 radc comm issue";
CM_ SG_ 811 APS_w054_camAutofix "Driver assistance computer (secondary): w054 cam autofix";
CM_ SG_ 811 APS_w055_radcVersionMismatch "Driver assistance computer (secondary): w055 radc version mismatch";
CM_ SG_ 811 APS_w056_diMia "Driver assistance computer (secondary): w056 di mia";
CM_ SG_ 811 APS_w057_mcuMia "Driver assistance computer (secondary): w057 mcu mia";
CM_ SG_ 811 APS_w058_epbMia "Driver assistance computer (secondary): w058 epb mia";
CM_ SG_ 811 APS_w059_parkMia "Driver assistance computer (secondary): w059 park mia";
CM_ SG_ 811 APS_w060_fcw_event "Driver assistance computer (secondary): w060 fcw event";
CM_ SG_ 811 APS_w061_tasMia "Driver assistance computer (secondary): w061 tas mia";
CM_ SG_ 811 APS_w062_radcAlignment "Driver assistance computer (secondary): w062 radc alignment";
CM_ SG_ 811 APS_w063_parkVersionMismatch "Driver assistance computer (secondary): w063 park version mismatch";
CM_ SG_ 811 APS_w064_epasMia "Driver assistance computer (secondary): w064 epas mia";
CM_ BO_ 876 "Driver assistance computer (secondary) message: warning matrix1";
CM_ SG_ 876 APS_w065_deserializerOvercurrent "Driver assistance computer (secondary): w065 deserializer overcurrent";
CM_ SG_ 876 APS_w066_deserializerLockLost "Driver assistance computer (secondary): w066 deserializer lock lost";
CM_ SG_ 876 APS_w067_steeringAlignment "Driver assistance computer (secondary): w067 steering alignment";
CM_ SG_ 876 APS_w068_vlInconsistency "Driver assistance computer (secondary): w068 vl inconsistency";
CM_ SG_ 876 APS_w069_apcSpaceMasked "Driver assistance computer (secondary): w069 apc space masked";
CM_ SG_ 876 APS_w070_apcIncompleteCal "Driver assistance computer (secondary): w070 apc incomplete cal";
CM_ SG_ 876 APS_w071_selfparkStarted "Driver assistance computer (secondary): w071 selfpark started";
CM_ SG_ 876 APS_w072_selfparkComplete "Driver assistance computer (secondary): w072 selfpark complete";
CM_ SG_ 876 APS_w073_issueEscalatedLDW "Driver assistance computer (secondary): w073 issue escalated LDW";
CM_ SG_ 876 APS_w074_inPathStationaryObst "Driver assistance computer (secondary): w074 in path stationary obst";
CM_ SG_ 876 APS_w075_scMia "Driver assistance computer (secondary): w075 sc mia";
CM_ SG_ 876 APS_w076_mobilEyeSetC "Driver assistance computer (secondary): w076 mobil eye set c";
CM_ SG_ 876 APS_w077_pmmActive "Driver assistance computer (secondary): w077 pmm active";
CM_ SG_ 876 APS_w078_pmmActive2 "Driver assistance computer (secondary): w078 pmm active2";
CM_ SG_ 876 APS_w079_edrAvailable "Driver assistance computer (secondary): w079 edr available";
CM_ SG_ 876 APS_w080_accFailedActivation "Driver assistance computer (secondary): w080 acc failed activation";
CM_ SG_ 876 APS_w081_pmmActiveBraking "Driver assistance computer (secondary): w081 pmm active braking";
CM_ SG_ 876 APS_w082_inPathFSviolation "Driver assistance computer (secondary): w082 in path f sviolation";
CM_ SG_ 876 APS_w083_inPathRADObject "Driver assistance computer (secondary): w083 in path RAD object";
CM_ SG_ 876 APS_w084_pmmIPSO "Driver assistance computer (secondary): w084 pmm IPSO";
CM_ SG_ 876 APS_w085_pmmSteering "Driver assistance computer (secondary): w085 pmm steering";
CM_ SG_ 876 APS_w086_robCollision "Driver assistance computer (secondary): w086 rob collision";
CM_ SG_ 876 APS_w087_DEPRECATED "Driver assistance computer (secondary): w087 DEPRECATED";
CM_ SG_ 876 APS_w088_DEPRECATED "Driver assistance computer (secondary): w088 DEPRECATED";
CM_ SG_ 876 APS_w089_DEPRECATED "Driver assistance computer (secondary): w089 DEPRECATED";
CM_ SG_ 876 APS_w090_DEPRECATED "Driver assistance computer (secondary): w090 DEPRECATED";
CM_ SG_ 876 APS_w091_DEPRECATED "Driver assistance computer (secondary): w091 DEPRECATED";
CM_ SG_ 876 APS_w092_DEPRECATED "Driver assistance computer (secondary): w092 DEPRECATED";
CM_ SG_ 876 APS_w093_DEPRECATED "Driver assistance computer (secondary): w093 DEPRECATED";
CM_ SG_ 876 APS_w094_DEPRECATED "Driver assistance computer (secondary): w094 DEPRECATED";
CM_ SG_ 876 APS_w095_DEPRECATED "Driver assistance computer (secondary): w095 DEPRECATED";
CM_ SG_ 876 APS_w096_DEPRECATED "Driver assistance computer (secondary): w096 DEPRECATED";
CM_ SG_ 876 APS_w097_DEPRECATED "Driver assistance computer (secondary): w097 DEPRECATED";
CM_ SG_ 876 APS_w098_DEPRECATED "Driver assistance computer (secondary): w098 DEPRECATED";
CM_ SG_ 876 APS_w099_DEPRECATED "Driver assistance computer (secondary): w099 DEPRECATED";
CM_ SG_ 876 APS_w100_DEPRECATED "Driver assistance computer (secondary): w100 DEPRECATED";
CM_ SG_ 876 APS_w101_DEPRECATED "Driver assistance computer (secondary): w101 DEPRECATED";
CM_ SG_ 876 APS_w102_DEPRECATED "Driver assistance computer (secondary): w102 DEPRECATED";
CM_ SG_ 876 APS_w103_robExperimentalAEB "Driver assistance computer (secondary): w103 rob experimental AEB";
CM_ SG_ 876 APS_w104_DEPRECATED "Driver assistance computer (secondary): w104 DEPRECATED";
CM_ SG_ 876 APS_w105_DEPRECATED "Driver assistance computer (secondary): w105 DEPRECATED";
CM_ SG_ 876 APS_w106_torsionBarOffset "Driver assistance computer (secondary): w106 torsion bar offset";
CM_ BO_ 1113 "Driver assistance computer (secondary) message: warning matrix2";
CM_ SG_ 1113 APS_w129_ECU_Power_Issue "Driver assistance computer (secondary): w129 ECU power issue";
CM_ SG_ 1113 APS_w130_ECU_Thermal_Issue "Driver assistance computer (secondary): w130 ECU thermal issue";
CM_ SG_ 1113 APS_w131_trap_exception "Driver assistance computer (secondary): w131 trap exception";
CM_ SG_ 1113 APS_w132_appVersionMismatch "Driver assistance computer (secondary): w132 app version mismatch";
CM_ SG_ 1113 APS_w133_ETHSwitchError "Driver assistance computer (secondary): w133 ETH switch error";
CM_ SG_ 1113 APS_w134_appMia "Driver assistance computer (secondary): w134 app mia";
CM_ SG_ 1113 APS_w135_appCritical "Driver assistance computer (secondary): w135 app critical";
CM_ SG_ 1113 APS_w136_gpsDisabled "Driver assistance computer (secondary): w136 gps disabled";
CM_ SG_ 1113 APS_w137_gpsFaultReset "Driver assistance computer (secondary): w137 gps fault reset";
CM_ SG_ 1113 APS_w138_gpsComIssue "Driver assistance computer (secondary): w138 gps com issue";
CM_ SG_ 1113 APS_w139_udpBufferOverflow "Driver assistance computer (secondary): w139 udp buffer overflow";
CM_ SG_ 1113 APS_w140_vcfrontMiaVehicleBus "Driver assistance computer (secondary): w140 vcfront mia vehicle bus";
CM_ SG_ 1113 APS_w141_rcmMiaPartyBus "Driver assistance computer (secondary): w141 rcm mia party bus";
CM_ SG_ 1113 APS_w142_diMiaPartyBus "Driver assistance computer (secondary): w142 di mia party bus";
CM_ SG_ 1113 APS_w143_espMiaPartyBus "Driver assistance computer (secondary): w143 esp mia party bus";
CM_ SG_ 1113 APS_w144_vcleftMiaPartyBus "Driver assistance computer (secondary): w144 vcleft mia party bus";
CM_ SG_ 1113 APS_w145_vcrightMiaPartyBus "Driver assistance computer (secondary): w145 vcright mia party bus";
CM_ SG_ 1113 APS_w146_epas3pMiaPartyBus "Driver assistance computer (secondary): w146 epas3p mia party bus";
CM_ SG_ 1113 APS_w147_vcleftMiaVehBus "Driver assistance computer (secondary): w147 vcleft mia veh bus";
CM_ SG_ 1113 APS_w148_vcrightMiaVehBus "Driver assistance computer (secondary): w148 vcright mia veh bus";
CM_ SG_ 1113 APS_w149_epblMiaVehBus "Driver assistance computer (secondary): w149 epbl mia veh bus";
CM_ SG_ 1113 APS_w150_sccmMiaVehBus "Driver assistance computer (secondary): w150 sccm mia veh bus";
CM_ SG_ 1113 APS_w151_apRecovered "Driver assistance computer (secondary): w151 ap recovered";
CM_ SG_ 1113 APS_w152_gpsFusionStatus "Driver assistance computer (secondary): w152 gps fusion status";
CM_ SG_ 1113 APS_w153_eacInhibit "Driver assistance computer (secondary): w153 eac inhibit";
CM_ SG_ 1113 APS_w155_ethLwipError "Driver assistance computer (secondary): w155 eth lwip error";
CM_ SG_ 1113 APS_w156_lwipAssert "Driver assistance computer (secondary): w156 lwip assert";
CM_ SG_ 1113 APS_w157_autopilotReboot "Driver assistance computer (secondary): w157 autopilot reboot";
CM_ SG_ 1113 APS_w158_apbMia "Driver assistance computer (secondary): w158 apb mia";
CM_ SG_ 1113 APS_w159_apbCritical "Driver assistance computer (secondary): w159 apb critical";
CM_ SG_ 1113 APS_w160_apbVersionMismatch "Driver assistance computer (secondary): w160 apb version mismatch";
CM_ SG_ 1113 APS_w161_gpsAntennaDisconnected "Driver assistance computer (secondary): w161 gps antenna disconnected";
CM_ SG_ 1113 APS_w162_TurboA_DisRegPgoodErr "Driver assistance computer (secondary): w162 turbo a dis reg pgood err";
CM_ SG_ 1113 APS_w163_TurboA_DisRegNFault "Driver assistance computer (secondary): w163 turbo a dis reg n fault";
CM_ SG_ 1113 APS_w164_TurboA_12VFuseFault "Driver assistance computer (secondary): w164 turbo a 12 v fuse fault";
CM_ SG_ 1113 APS_w165_TurboA_Temp_NOS "Driver assistance computer (secondary): w165 turbo a temp NOS";
CM_ SG_ 1113 APS_w166_TurboA_SMSLockStepErr "Driver assistance computer (secondary): w166 turbo a SMS lock step err";
CM_ SG_ 1113 APS_w167_TurboA_TMU_Throttle "Driver assistance computer (secondary): w167 turbo a TMU throttle";
CM_ SG_ 1113 APS_w168_TurboA_SMS_WDOG "Driver assistance computer (secondary): w168 turbo a SMS WDOG";
CM_ SG_ 1113 APS_w169_TurboA_SCS_LKUP "Driver assistance computer (secondary): w169 turbo a SCS LKUP";
CM_ SG_ 1113 APS_w170_TurboA_A72_watchdog "Driver assistance computer (secondary): w170 turbo a A72 watchdog";
CM_ SG_ 1113 APS_w171_TurboA_SMS_taskUtilErr "Driver assistance computer (secondary): w171 turbo a SMS task util err";
CM_ SG_ 1113 APS_w172_apFeaturesUnavailable "Driver assistance computer (secondary): w172 ap features unavailable";
CM_ SG_ 1113 APS_w178_TurboB_DisRegPgoodErr "Driver assistance computer (secondary): w178 turbo b dis reg pgood err";
CM_ SG_ 1113 APS_w179_TurboB_DisRegNFault "Driver assistance computer (secondary): w179 turbo b dis reg n fault";
CM_ SG_ 1113 APS_w180_TurboB_12VFuseFault "Driver assistance computer (secondary): w180 turbo b 12 v fuse fault";
CM_ SG_ 1113 APS_w181_TurboB_Temp_NOS "Driver assistance computer (secondary): w181 turbo b temp NOS";
CM_ SG_ 1113 APS_w182_TurboB_SMSLockStepErr "Driver assistance computer (secondary): w182 turbo b SMS lock step err";
CM_ SG_ 1113 APS_w183_TurboB_TMU_Throttle "Driver assistance computer (secondary): w183 turbo b TMU throttle";
CM_ SG_ 1113 APS_w184_TurboB_SMS_WDOG "Driver assistance computer (secondary): w184 turbo b SMS WDOG";
CM_ SG_ 1113 APS_w185_TurboB_SCS_LKUP "Driver assistance computer (secondary): w185 turbo b SCS LKUP";
CM_ SG_ 1113 APS_w186_TurboB_A72_watchdog "Driver assistance computer (secondary): w186 turbo b A72 watchdog";
CM_ SG_ 1113 APS_w187_TurboB_SMS_taskUtilErr "Driver assistance computer (secondary): w187 turbo b SMS task util err";
CM_ SG_ 1113 APS_w188_otherTurboUartMIA "Driver assistance computer (secondary): w188 other turbo uart MIA";
CM_ SG_ 1113 APS_w189_vcfrontMiaPartyBus "Driver assistance computer (secondary): w189 vcfront mia party bus";
CM_ SG_ 1113 APS_w190_iboosterMia "Driver assistance computer (secondary): w190 ibooster mia";
CM_ SG_ 1113 APS_w191_timesyncError "Driver assistance computer (secondary): w191 timesync error";
CM_ SG_ 1113 APS_w192_CANFault "Driver assistance computer (secondary): w192 CAN fault";
CM_ BO_ 848 "Driver assistance computer (secondary) message: warning matrix3";
CM_ SG_ 848 APS_w193_camWindshieldUnclean "Driver assistance computer (secondary): w193 cam windshield unclean";
CM_ SG_ 848 APS_w194_accDriverResumeRqrd "Driver assistance computer (secondary): w194 acc driver resume rqrd";
CM_ SG_ 848 APS_w195_scwUnavailable "Driver assistance computer (secondary): w195 scw unavailable";
CM_ SG_ 848 APS_w196_stopSignWarning "Driver assistance computer (secondary): w196 stop sign warning";
CM_ SG_ 848 APS_w197_redLightWarning "Driver assistance computer (secondary): w197 red light warning";
CM_ SG_ 848 APS_w198_tsrUnavailable "Driver assistance computer (secondary): w198 tsr unavailable";
CM_ SG_ 848 APS_w199_apcAbort "Driver assistance computer (secondary): w199 apc abort";
CM_ SG_ 848 APS_w200_lcSlowdown "Driver assistance computer (secondary): w200 lc slowdown";
CM_ SG_ 848 APS_w201_lcAborting "Driver assistance computer (secondary): w201 lc aborting";
CM_ SG_ 848 APS_w202_scwNoisyEnvironment "Driver assistance computer (secondary): w202 scw noisy environment";
CM_ SG_ 848 APS_w203_apcActivation "Driver assistance computer (secondary): w203 apc activation";
CM_ SG_ 848 APS_w204_apcFinalFront "Driver assistance computer (secondary): w204 apc final front";
CM_ SG_ 848 APS_w205_apcFinalRear "Driver assistance computer (secondary): w205 apc final rear";
CM_ SG_ 848 APS_w206_autosteerNotEnabled "Driver assistance computer (secondary): w206 autosteer not enabled";
CM_ SG_ 848 APS_w207_autosteerUnavailable "Driver assistance computer (secondary): w207 autosteer unavailable";
CM_ SG_ 848 APS_w208_rackDetected "Driver assistance computer (secondary): w208 rack detected";
CM_ SG_ 848 APS_w209_autoSummonRequest "Driver assistance computer (secondary): w209 auto summon request";
CM_ SG_ 848 APS_w210_camObstrcted "Driver assistance computer (secondary): w210 cam obstrcted";
CM_ SG_ 848 APS_w211_accNoSeatBelt "Driver assistance computer (secondary): w211 acc no seat belt";
CM_ SG_ 848 APS_w212_lcUnavailableStrikeOut "Driver assistance computer (secondary): w212 lc unavailable strike out";
CM_ SG_ 848 APS_w213_autosteerStruckOut "Driver assistance computer (secondary): w213 autosteer struck out";
CM_ SG_ 848 APS_w214_driverNotIntracting "Driver assistance computer (secondary): w214 driver not intracting";
CM_ SG_ 848 APS_w215_contDriverNotIntracting "Driver assistance computer (secondary): w215 cont driver not intracting";
CM_ SG_ 848 APS_w216_driverOverriding "Driver assistance computer (secondary): w216 driver overriding";
CM_ SG_ 848 APS_w217_lcUnavailableSpeeding "Driver assistance computer (secondary): w217 lc unavailable speeding";
CM_ SG_ 848 APS_w218_lcSpeedExceededLimit "Driver assistance computer (secondary): w218 lc speed exceeded limit";
CM_ SG_ 848 APS_w219_lcTempUnavailableSpeed "Driver assistance computer (secondary): w219 lc temp unavailable speed";
CM_ SG_ 848 APS_w220_lcTempUnavailableRoad "Driver assistance computer (secondary): w220 lc temp unavailable road";
CM_ SG_ 848 APS_w221_accRadarBlind "Driver assistance computer (secondary): w221 acc radar blind";
CM_ SG_ 848 APS_w222_accCameraBlind "Driver assistance computer (secondary): w222 acc camera blind";
CM_ SG_ 848 APS_w223_accObjectInPath "Driver assistance computer (secondary): w223 acc object in path";
CM_ SG_ 848 APS_w224_accCameraCalibration "Driver assistance computer (secondary): w224 acc camera calibration";
CM_ SG_ 848 APS_w225_lcDegradedVisSpeedLmt "Driver assistance computer (secondary): w225 lc degraded vis speed lmt";
CM_ SG_ 848 APS_w226_lcCamCalNeededSpeedLmt "Driver assistance computer (secondary): w226 lc cam cal needed speed lmt";
CM_ SG_ 848 APS_w227_virtualWallBlocked "Driver assistance computer (secondary): w227 virtual wall blocked";
CM_ SG_ 848 APS_w228_DEPRECATED "Driver assistance computer (secondary): w228 DEPRECATED";
CM_ SG_ 848 APS_w229_alcUltrasoundDamaged "Driver assistance computer (secondary): w229 alc ultrasound damaged";
CM_ SG_ 848 APS_w230_alcUltrasoundBlocked "Driver assistance computer (secondary): w230 alc ultrasound blocked";
CM_ SG_ 848 APS_w231_idfEvent "Driver assistance computer (secondary): w231 idf event";
CM_ SG_ 848 APS_w232_laneChangeRequested "Driver assistance computer (secondary): w232 lane change requested";
CM_ SG_ 848 APS_w235_a72LoopDetected "Driver assistance computer (secondary): w235 a72 loop detected";
CM_ SG_ 848 APS_w236_canSharedMemError "Driver assistance computer (secondary): w236 can shared mem error";
CM_ SG_ 848 APS_w237_faultMgrEventDetected "Driver assistance computer (secondary): w237 fault mgr event detected";
CM_ SG_ 848 APS_w238_resetReason "Driver assistance computer (secondary): w238 reset reason";
CM_ SG_ 848 APS_w241_ddrInitFailures "Driver assistance computer (secondary): w241 ddr init failures";
CM_ SG_ 848 APS_w242_tripMBISTFailure "Driver assistance computer (secondary): w242 trip MBIST failure";
CM_ SG_ 848 APS_w243_tripHWErrorStatus "Driver assistance computer (secondary): w243 trip HW error status";
CM_ SG_ 848 APS_w244_gpuHWFaultStatus "Driver assistance computer (secondary): w244 gpu HW fault status";
CM_ SG_ 848 APS_w245_eloopRxFromUnexpectedSo "Driver assistance computer (secondary): w245 eloop rx from unexpected source MAC";
CM_ SG_ 848 APS_w246_ethloopSwitchPortLinkDo "Driver assistance computer (secondary): w246 ethloop switch port link down";
CM_ SG_ 848 APS_w247_ethernetFrameError "Driver assistance computer (secondary): w247 ethernet frame error";
CM_ SG_ 848 APS_w248_ethloopSwitchPoorSqi "Driver assistance computer (secondary): w248 ethloop switch poor sqi";
CM_ SG_ 848 APS_w249_ufsFailures "Driver assistance computer (secondary): w249 ufs failures";
CM_ SG_ 848 APS_w250_ethloopSwitchMemUsageTo "Driver assistance computer (secondary): w250 ethloop switch mem usage too high port2";
CM_ SG_ 848 APS_w251_ethloopSwitchMemUsageTo "Driver assistance computer (secondary): w251 ethloop switch mem usage too high port3";
CM_ SG_ 848 APS_w252_ethSwitchPortLinkDown "Driver assistance computer (secondary): w252 eth switch port link down";
CM_ SG_ 848 APS_w253_powerStateTimeout "Driver assistance computer (secondary): w253 power state timeout";
CM_ SG_ 848 APS_w254_sleepStateTimeout "Driver assistance computer (secondary): w254 sleep state timeout";
CM_ SG_ 848 APS_w255_bootHealth "Driver assistance computer (secondary): w255 boot health";
CM_ BO_ 784 "Driver assistance computer (secondary) message: warning matrix4";
CM_ SG_ 784 APS_w257_assertFailure "Driver assistance computer (secondary): w257 assert failure";
CM_ SG_ 784 APS_w258_qspiFlashSectorChecksum "Driver assistance computer (secondary): w258 qspi flash sector checksum mismatch";
CM_ SG_ 784 APS_w259_qspiFailure "Driver assistance computer (secondary): w259 qspi failure";
CM_ SG_ 784 APS_w260_pgoodFailure "Driver assistance computer (secondary): w260 pgood failure";
CM_ SG_ 784 APS_w261_vrmFaultGrpA "Driver assistance computer (secondary): w261 vrm fault grp a";
CM_ SG_ 784 APS_w262_vrmFaultGrpB "Driver assistance computer (secondary): w262 vrm fault grp b";
CM_ SG_ 784 APS_w263_vrmFaultGrpC "Driver assistance computer (secondary): w263 vrm fault grp c";
CM_ SG_ 784 APS_w264_ddrPhy0Failures "Driver assistance computer (secondary): w264 ddr phy0 failures";
CM_ SG_ 784 APS_w265_ddrPhy1Failures "Driver assistance computer (secondary): w265 ddr phy1 failures";
CM_ SG_ 784 APS_w266_ddrPhy2Failures "Driver assistance computer (secondary): w266 ddr phy2 failures";
CM_ SG_ 784 APS_w267_ddrPhy3Failures "Driver assistance computer (secondary): w267 ddr phy3 failures";
CM_ SG_ 784 APS_w268_ddrControllerFailures "Driver assistance computer (secondary): w268 ddr controller failures";
CM_ SG_ 784 APS_w269_ethSwitchRxPageCountToo "Driver assistance computer (secondary): w269 eth switch rx page count too high port0 3";
CM_ SG_ 784 APS_w270_ethSwitchRxPageCountToo "Driver assistance computer (secondary): w270 eth switch rx page count too high port4 7";
CM_ SG_ 784 APS_w271_ddrScheduler0EccErrors "Driver assistance computer (secondary): w271 ddr scheduler0 ecc errors";
CM_ SG_ 784 APS_w272_ddrScheduler1EccErrors "Driver assistance computer (secondary): w272 ddr scheduler1 ecc errors";
CM_ SG_ 784 APS_w273_ddrScheduler2EccErrors "Driver assistance computer (secondary): w273 ddr scheduler2 ecc errors";
CM_ SG_ 784 APS_w274_ddrScheduler3EccErrors "Driver assistance computer (secondary): w274 ddr scheduler3 ecc errors";
CM_ SG_ 784 APS_w275_ddrScheduler4EccErrors "Driver assistance computer (secondary): w275 ddr scheduler4 ecc errors";
CM_ SG_ 784 APS_w276_ddrScheduler5EccErrors "Driver assistance computer (secondary): w276 ddr scheduler5 ecc errors";
CM_ SG_ 784 APS_w277_ddrScheduler6EccErrors "Driver assistance computer (secondary): w277 ddr scheduler6 ecc errors";
CM_ SG_ 784 APS_w278_ddrScheduler7EccErrors "Driver assistance computer (secondary): w278 ddr scheduler7 ecc errors";
CM_ SG_ 784 APS_w279_ufsPartitionError "Driver assistance computer (secondary): w279 ufs partition error";
CM_ SG_ 784 APS_w280_pepsMia "Driver assistance computer (secondary): w280 peps mia";
CM_ SG_ 784 APS_w281_rsaMia "Driver assistance computer (secondary): w281 rsa mia";
CM_ SG_ 784 APS_w282_smmuError "Driver assistance computer (secondary): w282 smmu error";
CM_ SG_ 784 APS_w283_psfaMia "Driver assistance computer (secondary): w283 psfa mia";
CM_ SG_ 784 APS_w284_cam12VBuckBoostAPwrIssu "Driver assistance computer (secondary): w284 cam12 v buck boost a pwr issue";
CM_ SG_ 784 APS_w285_cam12VBuckBoostBPwrIssu "Driver assistance computer (secondary): w285 cam12 v buck boost b pwr issue";
CM_ SG_ 784 APS_w286_cam12VEFuseAPrimaryIssu "Driver assistance computer (secondary): w286 cam12 VE fuse a primary issue";
CM_ SG_ 784 APS_w287_cam12VEFuseASecondaryIs "Driver assistance computer (secondary): w287 cam12 VE fuse a secondary issue";
CM_ SG_ 784 APS_w288_brakeboosterMia "Driver assistance computer (secondary): w288 brakebooster mia";
CM_ SG_ 784 APS_w289_turboTemperatureWarning "Driver assistance computer (secondary): w289 turbo temperature warning";
CM_ SG_ 784 APS_w290_cam12VBuckBoostBPwrRing "Driver assistance computer (secondary): w290 cam12 v buck boost b pwr ringing";
CM_ SG_ 784 APS_w291_eplannerError "Driver assistance computer (secondary): w291 eplanner error";
CM_ SG_ 784 APS_w292_CH_busOff "Driver assistance computer (secondary): w292 CH bus off";
CM_ SG_ 784 APS_w293_PARTY_busOff "Driver assistance computer (secondary): w293 PARTY bus off";
CM_ SG_ 784 APS_w294_VEH_busOff "Driver assistance computer (secondary): w294 VEH bus off";
CM_ SG_ 784 APS_w295_PT_busOff "Driver assistance computer (secondary): w295 PT bus off";
CM_ SG_ 784 APS_w296_wdogMonTaskDeadlineMiss "Driver assistance computer (secondary): w296 wdog mon task deadline miss";
CM_ SG_ 784 APS_w297_earlyWDogAlert "Driver assistance computer (secondary): w297 early w dog alert";
CM_ SG_ 784 APS_w298_cpuToApCanSharedMemErro "Driver assistance computer (secondary): w298 cpu to ap can shared mem error";
CM_ SG_ 784 APS_w299_apToCpuCanSharedMemErro "Driver assistance computer (secondary): w299 ap to cpu can shared mem error";
CM_ SG_ 784 APS_w300_sharedMemoryAccessError "Driver assistance computer (secondary): w300 shared memory access error";
CM_ SG_ 784 APS_w301_nocTimeoutDetected "Driver assistance computer (secondary): w301 noc timeout detected";
CM_ SG_ 784 APS_w302_canAPShmFifoFull "Driver assistance computer (secondary): w302 can AP shm fifo full";
CM_ SG_ 784 APS_w303_canAPShmFifoEmpty "Driver assistance computer (secondary): w303 can AP shm fifo empty";
CM_ SG_ 784 APS_w304_dataAbort "Driver assistance computer (secondary): w304 data abort";
CM_ SG_ 784 APS_w305_gpsPgoodFailure "Driver assistance computer (secondary): w305 gps pgood failure";
CM_ SG_ 784 APS_w306_ethPgoodFailure "Driver assistance computer (secondary): w306 eth pgood failure";
CM_ SG_ 784 APS_w307_eccEventDetected "Driver assistance computer (secondary): w307 ecc event detected";
CM_ SG_ 784 APS_w308_pmicErrorDetected "Driver assistance computer (secondary): w308 pmic error detected";
CM_ SG_ 784 APS_w309_ethBridgeDown "Driver assistance computer (secondary): w309 eth bridge down";
CM_ SG_ 784 APS_w310_wakeBootMetrics "Driver assistance computer (secondary): w310 wake boot metrics";
CM_ SG_ 784 APS_w311_apbdgDasMia "Driver assistance computer (secondary): w311 apbdg das mia";
CM_ SG_ 784 APS_w312_apbdgApMia "Driver assistance computer (secondary): w312 apbdg ap mia";
CM_ SG_ 784 APS_w313_BDY_busOff "Driver assistance computer (secondary): w313 BDY bus off";
CM_ SG_ 784 APS_w315_epas3pMiaBdyBus "Driver assistance computer (secondary): w315 epas3p mia bdy bus";
CM_ SG_ 784 APS_w316_apBootHealth "Driver assistance computer (secondary): w316 ap boot health";
CM_ SG_ 784 APS_w317_uiMia "Driver assistance computer (secondary): w317 ui mia";
CM_ SG_ 784 APS_w318_ethernetNetworkBufferHi "Driver assistance computer (secondary): w318 ethernet network buffer high watermark";
CM_ SG_ 784 APS_w319_vehDasImposterDetected "Driver assistance computer (secondary): w319 veh das imposter detected";
CM_ SG_ 784 APS_w320_eplannerPreconditionsMe "Driver assistance computer (secondary): w320 eplanner preconditions met";
CM_ BO_ 943 "BB ECU message: status";
CM_ SG_ 943 BB_statusChecksum "BB ECU: status checksum";
CM_ SG_ 943 BB_statusCounter "BB ECU: status counter";
CM_ SG_ 943 BB_sOutputRod "Reports the measured brake booster (BB) plunger piston position";
CM_ SG_ 943 BB_sOutputRodQF "Reports the BB_sOutputRod signal qualifier";
CM_ SG_ 943 BB_sInputRod "Reports the measured brake booster (BB) input rod stroke.";
CM_ SG_ 943 BB_sInputRodQF "Reports the BB_sInputRod signal qualifier.";
CM_ SG_ 943 BB_driverBrakeApply "Indicates whether the driver operates the brake pedal. Only active when the driver brakes, not when an external brake command implemented on brake booster (BB).";
CM_ SG_ 943 BB_driverBrakeApplyQF "Qualifier for BB_driverBrakeApply";
CM_ SG_ 943 BB_boosterStatus "Indication of the brake booster (BB) functional state";
CM_ SG_ 943 BB_warningLampRequest "Request from brake booster (BB) to enable the red brake lamp";
CM_ SG_ 943 BB_brakeFluidLevel "Indication of the brake fluid reservoir fluid level sensor status measured by the brake booster (BB).";
CM_ SG_ 943 BB_internalState "Indication of the brake booster (BB) internal state";
CM_ SG_ 943 BB_unfilteredFluidLevelLow "Indicates whether the unfiltered brake fluid level is detected as low.";
CM_ BO_ 1343 "High-voltage battery management system message: alert log";
CM_ SG_ 1343 BMS_alertID "High-voltage battery management system: alert ID";
CM_ SG_ 1343 BMS_alertSet "High-voltage battery management system: alert set";
CM_ SG_ 1343 BMS_a001_gatewayPackEnergy "High-voltage battery management system: a001 gateway pack energy";
CM_ SG_ 1343 BMS_a001_expectedPackEnergy "High-voltage battery management system: a001 expected pack energy";
CM_ SG_ 1343 BMS_a002_gatewayPackPerformanceD "High-voltage battery management system: a002 gateway pack performance deviation";
CM_ SG_ 1343 BMS_a002_expectedPackPerformance "High-voltage battery management system: a002 expected pack performance deviation";
CM_ SG_ 1343 BMS_a002_bmsPackMass "High-voltage battery management system: a002 bms pack mass";
CM_ SG_ 1343 BMS_a003_calBlockData_0 "High-voltage battery management system: a003 cal block data 0";
CM_ SG_ 1343 BMS_a017_packCurrent "High-voltage battery management system: a017 pack current";
CM_ SG_ 1343 BMS_a017_ovBrickVID "High-voltage battery management system: a017 ov brick VID";
CM_ SG_ 1343 BMS_a017_ovBrickV "High-voltage battery management system: a017 ov brick v";
CM_ SG_ 1343 BMS_a018_packCurrent "High-voltage battery management system: a018 pack current";
CM_ SG_ 1343 BMS_a018_uvBrickVID "High-voltage battery management system: a018 uv brick VID";
CM_ SG_ 1343 BMS_a018_uvBrickV "High-voltage battery management system: a018 uv brick v";
CM_ SG_ 1343 BMS_a019_coolantInletT "High-voltage battery management system: a019 coolant inlet t";
CM_ SG_ 1343 BMS_a019_activeCoolingTarget "High-voltage battery management system: a019 active cooling target";
CM_ SG_ 1343 BMS_a019_maxBrickT "High-voltage battery management system: a019 max brick t";
CM_ SG_ 1343 BMS_a019_maxBrickTID "High-voltage battery management system: a019 max brick TID";
CM_ SG_ 1343 BMS_a021_chargeViolation "High-voltage battery management system: a021 charge violation";
CM_ SG_ 1343 BMS_a021_currentLimit "High-voltage battery management system: a021 current limit";
CM_ SG_ 1343 BMS_a021_packCurrent "High-voltage battery management system: a021 pack current";
CM_ SG_ 1343 BMS_a022_chargeAccumulatorViolat "High-voltage battery management system: a022 charge accumulator violation";
CM_ SG_ 1343 BMS_a022_chargeAccumulatorValue "High-voltage battery management system: a022 charge accumulator value";
CM_ SG_ 1343 BMS_a022_chargeAccumulatorLimit "High-voltage battery management system: a022 charge accumulator limit";
CM_ SG_ 1343 BMS_a023_ovStackDeviceID "High-voltage battery management system: a023 ov stack device ID";
CM_ SG_ 1343 BMS_a023_ovStackV "High-voltage battery management system: a023 ov stack v";
CM_ SG_ 1343 BMS_a024_brickID "High-voltage battery management system: a024 brick ID";
CM_ SG_ 1343 BMS_a024_deltaV "High-voltage battery management system: a024 delta v";
CM_ SG_ 1343 BMS_a024_avgDvPrev "High-voltage battery management system: a024 avg dv prev";
CM_ SG_ 1343 BMS_a024_packCurrent "High-voltage battery management system: a024 pack current";
CM_ SG_ 1343 BMS_a027_swIsolationCount "High-voltage battery management system: a027 sw isolation count";
CM_ SG_ 1343 BMS_a030_worstBrickID "High-voltage battery management system: a030 worst brick ID";
CM_ SG_ 1343 BMS_a030_maxBrickImpedance "High-voltage battery management system: a030 max brick impedance";
CM_ SG_ 1343 BMS_a030_maxNormalizedImpedanceD "High-voltage battery management system: a030 max normalized impedance dev";
CM_ SG_ 1343 BMS_a030_faultThreshold "High-voltage battery management system: a030 fault threshold";
CM_ SG_ 1343 BMS_a030_numBricks "High-voltage battery management system: a030 num bricks";
CM_ SG_ 1343 BMS_a030_worstBrickSoc "High-voltage battery management system: a030 worst brick soc";
CM_ SG_ 1343 BMS_a035_isoR "High-voltage battery management system: a035 iso r";
CM_ SG_ 1343 BMS_a035_mode "High-voltage battery management system: a035 mode";
CM_ SG_ 1343 BMS_a035_activeSideVNoR "High-voltage battery management system: a035 active side v no r";
CM_ SG_ 1343 BMS_a035_activeSideVWithR "High-voltage battery management system: a035 active side v with r";
CM_ SG_ 1343 BMS_a035_passiveSideVNoR "High-voltage battery management system: a035 passive side v no r";
CM_ SG_ 1343 BMS_a035_passiveSideVWithR "High-voltage battery management system: a035 passive side v with r";
CM_ SG_ 1343 BMS_a039_dcLinkVoltage "High-voltage battery management system: a039 dc link voltage";
CM_ SG_ 1343 BMS_a039_packVoltage "High-voltage battery management system: a039 pack voltage";
CM_ SG_ 1343 BMS_a039_packContactorState "High-voltage battery management system: a039 pack contactor state";
CM_ SG_ 1343 BMS_a039_packCurrent "High-voltage battery management system: a039 pack current";
CM_ SG_ 1343 BMS_a039_maxBrickV "High-voltage battery management system: a039 max brick v";
CM_ SG_ 1343 BMS_a039_state "High-voltage battery management system: a039 state";
CM_ SG_ 1343 BMS_a041_resetType "High-voltage battery management system: a041 reset type";
CM_ SG_ 1343 BMS_a050_MIA_numBadReadings "High-voltage battery management system: a050 MIA num bad readings";
CM_ SG_ 1343 BMS_a050_MIA_numSnaReadings "High-voltage battery management system: a050 MIA num sna readings";
CM_ SG_ 1343 BMS_a050_MIA_brickId "High-voltage battery management system: a050 MIA brick id";
CM_ SG_ 1343 BMS_a051_hvp1V5Ref "High-voltage battery management system: a051 hvp1 V5 ref";
CM_ SG_ 1343 BMS_a051_hvp3V0Ref "High-voltage battery management system: a051 hvp3 V0 ref";
CM_ SG_ 1343 BMS_a051_bms3V0Ref "High-voltage battery management system: a051 bms3 V0 ref";
CM_ SG_ 1343 BMS_a059_sumBrickVoltages "High-voltage battery management system: a059 sum brick voltages";
CM_ SG_ 1343 BMS_a059_packVoltage "High-voltage battery management system: a059 pack voltage";
CM_ SG_ 1343 BMS_a062_state "High-voltage battery management system: a062 state";
CM_ SG_ 1343 BMS_a062_minBrickVId "High-voltage battery management system: a062 min brick v id";
CM_ SG_ 1343 BMS_a062_minBrickVoltage "High-voltage battery management system: a062 min brick voltage";
CM_ SG_ 1343 BMS_a062_maxBrickVId "High-voltage battery management system: a062 max brick v id";
CM_ SG_ 1343 BMS_a062_maxBrickVoltage "High-voltage battery management system: a062 max brick voltage";
CM_ SG_ 1343 BMS_a063_cpFaultInV "High-voltage battery management system: a063 cp fault in v";
CM_ SG_ 1343 BMS_a064_minBrickSOCID "High-voltage battery management system: a064 min brick SOCID";
CM_ SG_ 1343 BMS_a064_minBrickSOC "High-voltage battery management system: a064 min brick SOC";
CM_ SG_ 1343 BMS_a064_maxBrickSOCID "High-voltage battery management system: a064 max brick SOCID";
CM_ SG_ 1343 BMS_a064_maxBrickSOC "High-voltage battery management system: a064 max brick SOC";
CM_ SG_ 1343 BMS_a064_avgBrickSOC "High-voltage battery management system: a064 avg brick SOC";
CM_ SG_ 1343 BMS_a065_minBrickCacId "High-voltage battery management system: a065 min brick cac id";
CM_ SG_ 1343 BMS_a065_minBrickCac "High-voltage battery management system: a065 min brick cac";
CM_ SG_ 1343 BMS_a065_avgBrickCac "High-voltage battery management system: a065 avg brick cac";
CM_ SG_ 1343 BMS_a065_modCacImbalancePct "High-voltage battery management system: a065 mod cac imbalance pct";
CM_ SG_ 1343 BMS_a066_minBrickSocId "High-voltage battery management system: a066 min brick soc id";
CM_ SG_ 1343 BMS_a066_minBrickSocByOcvMax "High-voltage battery management system: a066 min brick soc by ocv max";
CM_ SG_ 1343 BMS_a066_maxBrickSocId "High-voltage battery management system: a066 max brick soc id";
CM_ SG_ 1343 BMS_a066_maxBrickSocByOcvMin "High-voltage battery management system: a066 max brick soc by ocv min";
CM_ SG_ 1343 BMS_a066_maxBrickSoc "High-voltage battery management system: a066 max brick soc";
CM_ SG_ 1343 BMS_a066_avgBrickSoc "High-voltage battery management system: a066 avg brick soc";
CM_ SG_ 1343 BMS_a067_minBrickCacId "High-voltage battery management system: a067 min brick cac id";
CM_ SG_ 1343 BMS_a067_minBrickCac "High-voltage battery management system: a067 min brick cac";
CM_ SG_ 1343 BMS_a067_avgBrickCac "High-voltage battery management system: a067 avg brick cac";
CM_ SG_ 1343 BMS_a067_modCacImbalancePct "High-voltage battery management system: a067 mod cac imbalance pct";
CM_ SG_ 1343 BMS_a068_minBrickCacId "High-voltage battery management system: a068 min brick cac id";
CM_ SG_ 1343 BMS_a068_minBrickCac "High-voltage battery management system: a068 min brick cac";
CM_ SG_ 1343 BMS_a068_avgBrickCac "High-voltage battery management system: a068 avg brick cac";
CM_ SG_ 1343 BMS_a068_modCacImbalancePct "High-voltage battery management system: a068 mod cac imbalance pct";
CM_ SG_ 1343 BMS_a069_dischargePowerPackVolta "High-voltage battery management system: a069 discharge power pack voltage floor";
CM_ SG_ 1343 BMS_a069_dischargePowerBrickVolt "High-voltage battery management system: a069 discharge power brick voltage floor";
CM_ SG_ 1343 BMS_a069_SOC "High-voltage battery management system: a069 SOC";
CM_ SG_ 1343 BMS_a069_minBrickT "High-voltage battery management system: a069 min brick t";
CM_ SG_ 1343 BMS_a069_minBrickVLimit "High-voltage battery management system: a069 min brick v limit";
CM_ SG_ 1343 BMS_a069_minBrickV "High-voltage battery management system: a069 min brick v";
CM_ SG_ 1343 BMS_a070_state "High-voltage battery management system: a070 state";
CM_ SG_ 1343 BMS_a070_minBrickVId "High-voltage battery management system: a070 min brick v id";
CM_ SG_ 1343 BMS_a070_minBrickVoltage "High-voltage battery management system: a070 min brick voltage";
CM_ SG_ 1343 BMS_a070_maxBrickVId "High-voltage battery management system: a070 max brick v id";
CM_ SG_ 1343 BMS_a070_maxBrickVoltage "High-voltage battery management system: a070 max brick voltage";
CM_ SG_ 1343 BMS_a071_stateRequest "High-voltage battery management system: a071 state request";
CM_ SG_ 1343 BMS_a071_state "High-voltage battery management system: a071 state";
CM_ SG_ 1343 BMS_a071_transitionAlertId "High-voltage battery management system: a071 transition alert id";
CM_ SG_ 1343 BMS_a074_maxBrickVTarget "High-voltage battery management system: a074 max brick v target";
CM_ SG_ 1343 BMS_a074_maxBrickV "High-voltage battery management system: a074 max brick v";
CM_ SG_ 1343 BMS_a075_chargeType "High-voltage battery management system: a075 charge type";
CM_ SG_ 1343 BMS_a076_netAh "High-voltage battery management system: a076 net ah";
CM_ SG_ 1343 BMS_a076_tetheringActive "High-voltage battery management system: a076 tethering active";
CM_ SG_ 1343 BMS_a077_chargeErrType "High-voltage battery management system: a077 charge err type";
CM_ SG_ 1343 BMS_a077_maxBrickVTarget "High-voltage battery management system: a077 max brick v target";
CM_ SG_ 1343 BMS_a077_maxBrickV "High-voltage battery management system: a077 max brick v";
CM_ SG_ 1343 BMS_a077_packTargetCurrent "High-voltage battery management system: a077 pack target current";
CM_ SG_ 1343 BMS_a077_packCurrent "High-voltage battery management system: a077 pack current";
CM_ SG_ 1343 BMS_a078_peakDchInChg "High-voltage battery management system: a078 peak dch in chg";
CM_ SG_ 1343 BMS_a079_maxBrickVTarget "High-voltage battery management system: a079 max brick v target";
CM_ SG_ 1343 BMS_a079_maxBrickV "High-voltage battery management system: a079 max brick v";
CM_ SG_ 1343 BMS_a081_stateRequest "High-voltage battery management system: a081 state request";
CM_ SG_ 1343 BMS_a081_firstBlockingAlertId "High-voltage battery management system: a081 first blocking alert id";
CM_ SG_ 1343 BMS_a081_secondBlockingAlertId "High-voltage battery management system: a081 second blocking alert id";
CM_ SG_ 1343 BMS_a081_thirdBlockingAlertId "High-voltage battery management system: a081 third blocking alert id";
CM_ SG_ 1343 BMS_a081_fourthBlockingAlertId "High-voltage battery management system: a081 fourth blocking alert id";
CM_ SG_ 1343 BMS_a081_totalAlertCount "High-voltage battery management system: a081 total alert count";
CM_ SG_ 1343 BMS_a082_stateRequest "High-voltage battery management system: a082 state request";
CM_ SG_ 1343 BMS_a082_firstAlertId "High-voltage battery management system: a082 first alert id";
CM_ SG_ 1343 BMS_a082_secondAlertId "High-voltage battery management system: a082 second alert id";
CM_ SG_ 1343 BMS_a082_thirdAlertId "High-voltage battery management system: a082 third alert id";
CM_ SG_ 1343 BMS_a082_fourthAlertId "High-voltage battery management system: a082 fourth alert id";
CM_ SG_ 1343 BMS_a082_totalAlertCount "High-voltage battery management system: a082 total alert count";
CM_ SG_ 1343 BMS_a083_packContactorRequest "High-voltage battery management system: a083 pack contactor request";
CM_ SG_ 1343 BMS_a085_packContactorSetStatePr "High-voltage battery management system: a085 pack contactor set state prev";
CM_ SG_ 1343 BMS_a085_packContactorSetState "High-voltage battery management system: a085 pack contactor set state";
CM_ SG_ 1343 BMS_a085_packContactorSetRe_0001 "High-voltage battery management system: a085 pack contactor set request prev";
CM_ SG_ 1343 BMS_a085_packContactorSetRequest "High-voltage battery management system: a085 pack contactor set request";
CM_ SG_ 1343 BMS_a086_fcContactorSetStatePrev "High-voltage battery management system: a086 fc contactor set state prev";
CM_ SG_ 1343 BMS_a086_fcContactorSetState "High-voltage battery management system: a086 fc contactor set state";
CM_ SG_ 1343 BMS_a086_fcContactorSetRequestPr "High-voltage battery management system: a086 fc contactor set request prev";
CM_ SG_ 1343 BMS_a086_fcContactorSetRequest "High-voltage battery management system: a086 fc contactor set request";
CM_ SG_ 1343 BMS_a087_blockingAlert "High-voltage battery management system: a087 blocking alert";
CM_ SG_ 1343 BMS_a090_GTWmessageTout "High-voltage battery management system: a090 GT wmessage tout";
CM_ SG_ 1343 BMS_a098_breakLocationA "High-voltage battery management system: a098 break location a";
CM_ SG_ 1343 BMS_a098_bmbCommStatusTypeA "High-voltage battery management system: a098 bmb comm status type a";
CM_ SG_ 1343 BMS_a098_breakLocationB "High-voltage battery management system: a098 break location b";
CM_ SG_ 1343 BMS_a098_bmbCommStatusTypeB "High-voltage battery management system: a098 bmb comm status type b";
CM_ SG_ 1343 BMS_a098_alertFromHvp "High-voltage battery management system: a098 alert from hvp";
CM_ SG_ 1343 BMS_a099_breakLocationA "High-voltage battery management system: a099 break location a";
CM_ SG_ 1343 BMS_a099_bmbCommStatusTypeA "High-voltage battery management system: a099 bmb comm status type a";
CM_ SG_ 1343 BMS_a099_breakLocationB "High-voltage battery management system: a099 break location b";
CM_ SG_ 1343 BMS_a099_bmbCommStatusTypeB "High-voltage battery management system: a099 bmb comm status type b";
CM_ SG_ 1343 BMS_a099_bmbChainBreakType "High-voltage battery management system: a099 bmb chain break type";
CM_ SG_ 1343 BMS_a099_alertFromHvp "High-voltage battery management system: a099 alert from hvp";
CM_ SG_ 1343 BMS_a100_testTrigger "High-voltage battery management system: a100 test trigger";
CM_ SG_ 1343 BMS_a100_setFromNvm "High-voltage battery management system: a100 set from nvm";
CM_ SG_ 1343 BMS_a100_voltageDeviation "High-voltage battery management system: a100 voltage deviation";
CM_ SG_ 1343 BMS_a100_voltageLoss "High-voltage battery management system: a100 voltage loss";
CM_ SG_ 1343 BMS_a105_tSenseFailedModule1 "High-voltage battery management system: a105 t sense failed module1";
CM_ SG_ 1343 BMS_a105_avgBrickTModule1 "High-voltage battery management system: a105 avg brick t module1";
CM_ SG_ 1343 BMS_a105_tSenseFailedModule2 "High-voltage battery management system: a105 t sense failed module2";
CM_ SG_ 1343 BMS_a105_avgBrickTModule2 "High-voltage battery management system: a105 avg brick t module2";
CM_ SG_ 1343 BMS_a105_tSenseFailedModule3 "High-voltage battery management system: a105 t sense failed module3";
CM_ SG_ 1343 BMS_a105_avgBrickTModule3 "High-voltage battery management system: a105 avg brick t module3";
CM_ SG_ 1343 BMS_a105_tSenseFailedModule4 "High-voltage battery management system: a105 t sense failed module4";
CM_ SG_ 1343 BMS_a105_avgBrickTModule4 "High-voltage battery management system: a105 avg brick t module4";
CM_ SG_ 1343 BMS_a105_inletTemp "High-voltage battery management system: a105 inlet temp";
CM_ SG_ 1343 BMS_a106_minBrickT "High-voltage battery management system: a106 min brick t";
CM_ SG_ 1343 BMS_a106_maxBrickT "High-voltage battery management system: a106 max brick t";
CM_ SG_ 1343 BMS_a106_avgBrickT "High-voltage battery management system: a106 avg brick t";
CM_ SG_ 1343 BMS_a106_inletTemp "High-voltage battery management system: a106 inlet temp";
CM_ SG_ 1343 BMS_a107_MIA_numBadReadings "High-voltage battery management system: a107 MIA num bad readings";
CM_ SG_ 1343 BMS_a107_MIA_numSnaReadings "High-voltage battery management system: a107 MIA num sna readings";
CM_ SG_ 1343 BMS_a107_MIA_stackId "High-voltage battery management system: a107 MIA stack id";
CM_ SG_ 1343 BMS_a109_muteMask "High-voltage battery management system: a109 mute mask";
CM_ SG_ 1343 BMS_a109_packInBleed "High-voltage battery management system: a109 pack in bleed";
CM_ SG_ 1343 BMS_a117_brickID "High-voltage battery management system: a117 brick ID";
CM_ SG_ 1343 BMS_a117_brickSoc2 "High-voltage battery management system: a117 brick soc2";
CM_ SG_ 1343 BMS_a117_dSocAlertThreshold "High-voltage battery management system: a117 d soc alert threshold";
CM_ SG_ 1343 BMS_a117_dSocAlpha "High-voltage battery management system: a117 d soc alpha";
CM_ SG_ 1343 BMS_a118_brickID "High-voltage battery management system: a118 brick ID";
CM_ SG_ 1343 BMS_a118_brickSoc2 "High-voltage battery management system: a118 brick soc2";
CM_ SG_ 1343 BMS_a118_dSocAlertThreshold "High-voltage battery management system: a118 d soc alert threshold";
CM_ SG_ 1343 BMS_a118_dSocAlpha "High-voltage battery management system: a118 d soc alpha";
CM_ SG_ 1343 BMS_a122_thermistorID "High-voltage battery management system: a122 thermistor ID";
CM_ SG_ 1343 BMS_a122_irrationalThermistorTem "High-voltage battery management system: a122 irrational thermistor temp";
CM_ SG_ 1343 BMS_a122_averageRawThermistorTem "High-voltage battery management system: a122 average raw thermistor temp";
CM_ SG_ 1343 BMS_a122_minRawThermistorTemp "High-voltage battery management system: a122 min raw thermistor temp";
CM_ SG_ 1343 BMS_a122_maxRawThermistorTemp "High-voltage battery management system: a122 max raw thermistor temp";
CM_ SG_ 1343 BMS_a122_numValidThermistors "High-voltage battery management system: a122 num valid thermistors";
CM_ SG_ 1343 BMS_a123_packPlus "High-voltage battery management system: a123 pack plus";
CM_ SG_ 1343 BMS_a123_isoR "High-voltage battery management system: a123 iso r";
CM_ SG_ 1343 BMS_a123_packMinus "High-voltage battery management system: a123 pack minus";
CM_ SG_ 1343 BMS_a129_brickID "High-voltage battery management system: a129 brick ID";
CM_ SG_ 1343 BMS_a129_deltaV "High-voltage battery management system: a129 delta v";
CM_ SG_ 1343 BMS_a129_retryCount "High-voltage battery management system: a129 retry count";
CM_ SG_ 1343 BMS_a131_brickID "High-voltage battery management system: a131 brick ID";
CM_ SG_ 1343 BMS_a131_deltaV "High-voltage battery management system: a131 delta v";
CM_ SG_ 1343 BMS_a131_retryCount "High-voltage battery management system: a131 retry count";
CM_ SG_ 1343 BMS_a132_multiVendorErrorMask "High-voltage battery management system: a132 multi vendor error mask";
CM_ SG_ 1343 BMS_a135_bmbDiagnosticsType "High-voltage battery management system: a135 bmb diagnostics type";
CM_ SG_ 1343 BMS_a135_bmbDeviceId "High-voltage battery management system: a135 bmb device id";
CM_ SG_ 1343 BMS_a135_readCVA "High-voltage battery management system: a135 read CVA";
CM_ SG_ 1343 BMS_a135_readCVB "High-voltage battery management system: a135 read CVB";
CM_ SG_ 1343 BMS_a135_readCVC "High-voltage battery management system: a135 read CVC";
CM_ SG_ 1343 BMS_a135_readCVD "High-voltage battery management system: a135 read CVD";
CM_ SG_ 1343 BMS_a135_readCVE "High-voltage battery management system: a135 read CVE";
CM_ SG_ 1343 BMS_a135_readCVF "High-voltage battery management system: a135 read CVF";
CM_ SG_ 1343 BMS_a135_readSNA "High-voltage battery management system: a135 read SNA";
CM_ SG_ 1343 BMS_a135_readSNB "High-voltage battery management system: a135 read SNB";
CM_ SG_ 1343 BMS_a135_readSNC "High-voltage battery management system: a135 read SNC";
CM_ SG_ 1343 BMS_a135_readSND "High-voltage battery management system: a135 read SND";
CM_ SG_ 1343 BMS_a135_readSNE "High-voltage battery management system: a135 read SNE";
CM_ SG_ 1343 BMS_a135_readSNF "High-voltage battery management system: a135 read SNF";
CM_ SG_ 1343 BMS_a135_readAUXA "High-voltage battery management system: a135 read AUXA";
CM_ SG_ 1343 BMS_a135_readAUXB "High-voltage battery management system: a135 read AUXB";
CM_ SG_ 1343 BMS_a135_readSTAT "High-voltage battery management system: a135 read STAT";
CM_ SG_ 1343 BMS_a136_maxBrickTID "High-voltage battery management system: a136 max brick TID";
CM_ SG_ 1343 BMS_a136_coolantInletT "High-voltage battery management system: a136 coolant inlet t";
CM_ SG_ 1343 BMS_a136_activeCoolingTarget "High-voltage battery management system: a136 active cooling target";
CM_ SG_ 1343 BMS_a136_maxBrickT "High-voltage battery management system: a136 max brick t";
CM_ SG_ 1343 BMS_a139_packVoltage "High-voltage battery management system: a139 pack voltage";
CM_ SG_ 1343 BMS_a139_dcLinkVoltage "High-voltage battery management system: a139 dc link voltage";
CM_ SG_ 1343 BMS_a140_bmbDeviceMask "High-voltage battery management system: a140 bmb device mask";
CM_ SG_ 1343 BMS_a140_faultType "High-voltage battery management system: a140 fault type";
CM_ SG_ 1343 BMS_a142_isolationResistance "High-voltage battery management system: a142 isolation resistance";
CM_ SG_ 1343 BMS_a142_mode "High-voltage battery management system: a142 mode";
CM_ SG_ 1343 BMS_a143_initialSoc "High-voltage battery management system: a143 initial soc";
CM_ SG_ 1343 BMS_a143_endingSoc "High-voltage battery management system: a143 ending soc";
CM_ SG_ 1343 BMS_a143_deltaAh "High-voltage battery management system: a143 delta ah";
CM_ SG_ 1343 BMS_a143_cacChangeBrickID "High-voltage battery management system: a143 cac change brick ID";
CM_ SG_ 1343 BMS_a143_cacUpdateError "High-voltage battery management system: a143 cac update error";
CM_ SG_ 1343 BMS_a144_HVP_major_version "High-voltage battery management system: a144 HVP major version";
CM_ SG_ 1343 BMS_a144_HVP_minor_version "High-voltage battery management system: a144 HVP minor version";
CM_ SG_ 1343 BMS_a144_BMS_minor_version "High-voltage battery management system: a144 BMS minor version";
CM_ SG_ 1343 BMS_a145_maxSocChange "High-voltage battery management system: a145 max soc change";
CM_ SG_ 1343 BMS_a145_maxSocChangeBrickID "High-voltage battery management system: a145 max soc change brick ID";
CM_ SG_ 1343 BMS_a145_numBricksChanged "High-voltage battery management system: a145 num bricks changed";
CM_ SG_ 1343 BMS_a145_brickChangeHystRatio "High-voltage battery management system: a145 brick change hyst ratio";
CM_ SG_ 1343 BMS_a146_maxBrickV "High-voltage battery management system: a146 max brick v";
CM_ SG_ 1343 BMS_a146_state "High-voltage battery management system: a146 state";
CM_ SG_ 1343 BMS_a146_packCurrent "High-voltage battery management system: a146 pack current";
CM_ SG_ 1343 BMS_a146_uvBrickVID "High-voltage battery management system: a146 uv brick VID";
CM_ SG_ 1343 BMS_a146_uvBrickV "High-voltage battery management system: a146 uv brick v";
CM_ SG_ 1343 BMS_a151_isoPositiveR "High-voltage battery management system: a151 iso positive r";
CM_ SG_ 1343 BMS_a151_isoNegativeR "High-voltage battery management system: a151 iso negative r";
CM_ SG_ 1343 BMS_a152_isoR "High-voltage battery management system: a152 iso r";
CM_ SG_ 1343 BMS_a152_mode "High-voltage battery management system: a152 mode";
CM_ SG_ 1343 BMS_a152_activeSideVNoR "High-voltage battery management system: a152 active side v no r";
CM_ SG_ 1343 BMS_a152_activeSideVWithR "High-voltage battery management system: a152 active side v with r";
CM_ SG_ 1343 BMS_a152_passiveSideVNoR "High-voltage battery management system: a152 passive side v no r";
CM_ SG_ 1343 BMS_a152_passiveSideVWithR "High-voltage battery management system: a152 passive side v with r";
CM_ SG_ 1343 BMS_a154_packCurrent "High-voltage battery management system: a154 pack current";
CM_ SG_ 1343 BMS_a154_ovBrickVID "High-voltage battery management system: a154 ov brick VID";
CM_ SG_ 1343 BMS_a154_ovBrickV "High-voltage battery management system: a154 ov brick v";
CM_ SG_ 1343 BMS_a156_VrefSample "High-voltage battery management system: a156 vref sample";
CM_ SG_ 1343 BMS_a156_bmbDeviceId "High-voltage battery management system: a156 bmb device id";
CM_ SG_ 1343 BMS_a156_VrefStatus "High-voltage battery management system: a156 vref status";
CM_ SG_ 1343 BMS_a158_shuntCurrentMia "High-voltage battery management system: a158 shunt current mia";
CM_ SG_ 1343 BMS_a158_contactorStateMia "High-voltage battery management system: a158 contactor state mia";
CM_ SG_ 1343 BMS_a158_hvpFaultsMia "High-voltage battery management system: a158 hvp faults mia";
CM_ SG_ 1343 BMS_a162_dischargePower_W "High-voltage battery management system: a162 discharge power w";
CM_ SG_ 1343 BMS_a162_minSoc "High-voltage battery management system: a162 min soc";
CM_ SG_ 1343 BMS_a162_socThreshold "High-voltage battery management system: a162 soc threshold";
CM_ SG_ 1343 BMS_a164_regenPower "High-voltage battery management system: a164 regen power";
CM_ SG_ 1343 BMS_a165_packPositiveV "High-voltage battery management system: a165 pack positive v";
CM_ SG_ 1343 BMS_a165_packNegativeV "High-voltage battery management system: a165 pack negative v";
CM_ SG_ 1343 BMS_a165_dcLinkPositiveV "High-voltage battery management system: a165 dc link positive v";
CM_ SG_ 1343 BMS_a165_dcLinkNegativeV "High-voltage battery management system: a165 dc link negative v";
CM_ SG_ 1343 BMS_a166_packPositiveV "High-voltage battery management system: a166 pack positive v";
CM_ SG_ 1343 BMS_a166_packNegativeV "High-voltage battery management system: a166 pack negative v";
CM_ SG_ 1343 BMS_a166_dcLinkPositiveV "High-voltage battery management system: a166 dc link positive v";
CM_ SG_ 1343 BMS_a166_dcLinkNegativeV "High-voltage battery management system: a166 dc link negative v";
CM_ SG_ 1343 BMS_a167_fcContPositiveAuxOpen "High-voltage battery management system: a167 fc cont positive aux open";
CM_ SG_ 1343 BMS_a167_fcContNegativeAuxOpen "High-voltage battery management system: a167 fc cont negative aux open";
CM_ SG_ 1343 BMS_a167_dcLinkPositiveV "High-voltage battery management system: a167 dc link positive v";
CM_ SG_ 1343 BMS_a167_dcLinkNegativeV "High-voltage battery management system: a167 dc link negative v";
CM_ SG_ 1343 BMS_a167_fcLinkPositiveV "High-voltage battery management system: a167 fc link positive v";
CM_ SG_ 1343 BMS_a167_fcLinkNegativeV "High-voltage battery management system: a167 fc link negative v";
CM_ SG_ 1343 BMS_a168_fcContPositiveAuxOpen "High-voltage battery management system: a168 fc cont positive aux open";
CM_ SG_ 1343 BMS_a168_fcContNegativeAuxOpen "High-voltage battery management system: a168 fc cont negative aux open";
CM_ SG_ 1343 BMS_a168_dcLinkPositiveV "High-voltage battery management system: a168 dc link positive v";
CM_ SG_ 1343 BMS_a168_dcLinkNegativeV "High-voltage battery management system: a168 dc link negative v";
CM_ SG_ 1343 BMS_a168_fcLinkPositiveV "High-voltage battery management system: a168 fc link positive v";
CM_ SG_ 1343 BMS_a168_fcLinkNegativeV "High-voltage battery management system: a168 fc link negative v";
CM_ SG_ 1343 BMS_a169_DCAndFCContactorsWelded "High-voltage battery management system: a169 DC and FC contactors welded";
CM_ SG_ 1343 BMS_a170_limpModeActive "High-voltage battery management system: a170 limp mode active";
CM_ SG_ 1343 BMS_a171_stackVoltage "High-voltage battery management system: a171 stack voltage";
CM_ SG_ 1343 BMS_a171_sumBrickVoltage "High-voltage battery management system: a171 sum brick voltage";
CM_ SG_ 1343 BMS_a171_stackId "High-voltage battery management system: a171 stack id";
CM_ SG_ 1343 BMS_a172_swIsolationCount "High-voltage battery management system: a172 sw isolation count";
CM_ SG_ 1343 BMS_a177_energyAlertThreshold "High-voltage battery management system: a177 energy alert threshold";
CM_ SG_ 1343 BMS_a177_energyBuffer "High-voltage battery management system: a177 energy buffer";
CM_ SG_ 1343 BMS_a178_diPower "High-voltage battery management system: a178 di power";
CM_ SG_ 1343 BMS_a178_energyError "High-voltage battery management system: a178 energy error";
CM_ SG_ 1343 BMS_a178_powerError "High-voltage battery management system: a178 power error";
CM_ SG_ 1343 BMS_a178_minPowerError "High-voltage battery management system: a178 min power error";
CM_ SG_ 1343 BMS_a178_maxPowerError "High-voltage battery management system: a178 max power error";
CM_ SG_ 1343 BMS_a178_diMiaCount "High-voltage battery management system: a178 di mia count";
CM_ SG_ 1343 BMS_a178_diSnaCount "High-voltage battery management system: a178 di sna count";
CM_ SG_ 1343 BMS_a188_currentTripThreshold "High-voltage battery management system: a188 current trip threshold";
CM_ SG_ 1343 BMS_a188_dcLinkDetectedCurrent "High-voltage battery management system: a188 dc link detected current";
CM_ SG_ 1343 BMS_a189_currentTripThreshold "High-voltage battery management system: a189 current trip threshold";
CM_ SG_ 1343 BMS_a189_dcLinkDetectedCurrent "High-voltage battery management system: a189 dc link detected current";
CM_ SG_ 1343 BMS_a190_voltageTripThreshold "High-voltage battery management system: a190 voltage trip threshold";
CM_ SG_ 1343 BMS_a190_dcLinkDetectedVoltage "High-voltage battery management system: a190 dc link detected voltage";
CM_ SG_ 1343 BMS_a191_voltageTripThreshold "High-voltage battery management system: a191 voltage trip threshold";
CM_ SG_ 1343 BMS_a191_dcLinkDetectedVoltage "High-voltage battery management system: a191 dc link detected voltage";
CM_ SG_ 1343 BMS_a192_detectedChargeCurrent "High-voltage battery management system: a192 detected charge current";
CM_ SG_ 1343 BMS_a193_maxBrickVoltageLimit "High-voltage battery management system: a193 max brick voltage limit";
CM_ SG_ 1343 BMS_a193_detectedMaxBrickVoltage "High-voltage battery management system: a193 detected max brick voltage";
CM_ SG_ 1343 BMS_a201_maxBrickV "High-voltage battery management system: a201 max brick v";
CM_ SG_ 1343 BMS_a201_maxBrickVIndex "High-voltage battery management system: a201 max brick v index";
CM_ SG_ 1343 BMS_a227_packCurrent "High-voltage battery management system: a227 pack current";
CM_ SG_ 1343 BMS_a227_dcChargeCurrentRequest "High-voltage battery management system: a227 dc charge current request";
CM_ SG_ 1343 BMS_a256_minBrickT "High-voltage battery management system: a256 min brick t";
CM_ SG_ 1343 BMS_a256_maxBrickT "High-voltage battery management system: a256 max brick t";
CM_ SG_ 1343 BMS_a256_minBrickV "High-voltage battery management system: a256 min brick v";
CM_ SG_ 1343 BMS_a256_maxBrickV "High-voltage battery management system: a256 max brick v";
CM_ SG_ 1343 BMS_a256_packSoe "High-voltage battery management system: a256 pack soe";
CM_ SG_ 1343 BMS_a256_SOC "High-voltage battery management system: a256 SOC";
CM_ BO_ 800 "High-voltage battery management system message: alert matrix";
CM_ SG_ 800 BMS_matrixIndex "High-voltage battery management system: matrix index";
CM_ SG_ 800 BMS_a001_Pack_Config_Mismatch "High-voltage battery management system: a001 pack config mismatch";
CM_ SG_ 800 BMS_a002_Pack_Performance_Config "High-voltage battery management system: a002 pack performance config mismatch";
CM_ SG_ 800 BMS_a003_SW_Pack_Birth_Date_Miss "High-voltage battery management system: a003 SW pack birth date missing";
CM_ SG_ 800 BMS_a004_Cal_Vs_Serial_Birth_Dat "High-voltage battery management system: a004 cal vs serial birth date mismatch";
CM_ SG_ 800 BMS_a016_Pack_Module_Id_Mismatch "High-voltage battery management system: a016 pack module id mismatch";
CM_ SG_ 800 BMS_a017_SW_Brick_OV "High-voltage battery management system: a017 SW brick OV";
CM_ SG_ 800 BMS_a018_SW_Brick_UV "High-voltage battery management system: a018 SW brick UV";
CM_ SG_ 800 BMS_a019_SW_Module_OT "High-voltage battery management system: a019 SW module OT";
CM_ SG_ 800 BMS_a020_SW_Brick_Instability "High-voltage battery management system: a020 SW brick instability";
CM_ SG_ 800 BMS_a021_SW_Dr_Limits_Regulation "High-voltage battery management system: a021 SW dr limits regulation";
CM_ SG_ 800 BMS_a022_SW_Over_Current "High-voltage battery management system: a022 SW over current";
CM_ SG_ 800 BMS_a023_SW_Stack_OV "High-voltage battery management system: a023 SW stack OV";
CM_ SG_ 800 BMS_a024_SW_Islanded_Brick "High-voltage battery management system: a024 SW islanded brick";
CM_ SG_ 800 BMS_a025_SW_PwrBalance_Anomaly "High-voltage battery management system: a025 SW pwr balance anomaly";
CM_ SG_ 800 BMS_a026_SW_HFCurrent_Anomaly "High-voltage battery management system: a026 SW HF current anomaly";
CM_ SG_ 800 BMS_a027_SW_Repeated_Isolation_F "High-voltage battery management system: a027 SW repeated isolation failure in drive";
CM_ SG_ 800 BMS_a028_ShuntAsicCurrentOffsetD "High-voltage battery management system: a028 shunt asic current offset deviation";
CM_ SG_ 800 BMS_a029_dSoc_Limiting "High-voltage battery management system: a029 d soc limiting";
CM_ SG_ 800 BMS_a030_Impedance_Deviation "High-voltage battery management system: a030 impedance deviation";
CM_ SG_ 800 BMS_a031_AlertsSetDuringSleep "High-voltage battery management system: a031 alerts set during sleep";
CM_ SG_ 800 BMS_a032_VoltageLoss "High-voltage battery management system: a032 voltage loss";
CM_ SG_ 800 BMS_a033_VoltageDeviation "High-voltage battery management system: a033 voltage deviation";
CM_ SG_ 800 BMS_a034_SW_Passive_Isolation "High-voltage battery management system: a034 SW passive isolation";
CM_ SG_ 800 BMS_a035_SW_Isolation "High-voltage battery management system: a035 SW isolation";
CM_ SG_ 800 BMS_a036_SW_HvpHvilFault "High-voltage battery management system: a036 SW hvp hvil fault";
CM_ SG_ 800 BMS_a037_SW_Flood_Port_Open "High-voltage battery management system: a037 SW flood port open";
CM_ SG_ 800 BMS_a039_SW_DC_Link_Over_Voltage "High-voltage battery management system: a039 SW DC link over voltage";
CM_ SG_ 800 BMS_a040_SW_Watch_Dog_HW_Trigger "High-voltage battery management system: a040 SW watch dog HW triggered";
CM_ SG_ 800 BMS_a041_SW_Destructive_Reset_So "High-voltage battery management system: a041 SW destructive reset source";
CM_ SG_ 800 BMS_a042_SW_MPU_Error "High-voltage battery management system: a042 SW MPU error";
CM_ SG_ 800 BMS_a043_SW_Watch_Dog_Reset "High-voltage battery management system: a043 SW watch dog reset";
CM_ SG_ 800 BMS_a044_SW_Assertion "High-voltage battery management system: a044 SW assertion";
CM_ SG_ 800 BMS_a045_SW_Exception "High-voltage battery management system: a045 SW exception";
CM_ SG_ 800 BMS_a046_SW_Task_Stack_Usage "High-voltage battery management system: a046 SW task stack usage";
CM_ SG_ 800 BMS_a047_SW_Task_Stack_Overflow "High-voltage battery management system: a047 SW task stack overflow";
CM_ SG_ 800 BMS_a048_SW_Watch_Dog_Warning "High-voltage battery management system: a048 SW watch dog warning";
CM_ SG_ 800 BMS_a049_SW_Thermal_Event "High-voltage battery management system: a049 SW thermal event";
CM_ SG_ 800 BMS_a050_SW_Brick_Voltage_MIA "High-voltage battery management system: a050 SW brick voltage MIA";
CM_ SG_ 800 BMS_a051_SW_HVC_Vref_Bad "High-voltage battery management system: a051 SW HVC vref bad";
CM_ SG_ 800 BMS_a052_SW_PCS_MIA "High-voltage battery management system: a052 SW PCS MIA";
CM_ SG_ 800 BMS_a054_SW_Ver_Supply_Fault "High-voltage battery management system: a054 SW ver supply fault";
CM_ SG_ 800 BMS_a055_SW_HvChain_Model_Fault "High-voltage battery management system: a055 SW hv chain model fault";
CM_ SG_ 800 BMS_a056_SW_Standby_Supply_Fault "High-voltage battery management system: a056 SW standby supply fault";
CM_ SG_ 800 BMS_a057_SW_Bandolier_Model_Warn "High-voltage battery management system: a057 SW bandolier model warning";
CM_ SG_ 800 BMS_a058_SW_Bandolier_Model_Rese "High-voltage battery management system: a058 SW bandolier model reset";
CM_ SG_ 800 BMS_a059_SW_Pack_Voltage_Sensing "High-voltage battery management system: a059 SW pack voltage sensing";
CM_ SG_ 800 BMS_a060_SW_Leakage_Test_Failure "High-voltage battery management system: a060 SW leakage test failure";
CM_ SG_ 800 BMS_a061_SW_BrickV_Change "High-voltage battery management system: a061 SW brick v change";
CM_ SG_ 800 BMS_a062_SW_BrickV_Imbalance "High-voltage battery management system: a062 SW brick v imbalance";
CM_ SG_ 800 BMS_a063_SW_ChargePort_Fault "High-voltage battery management system: a063 SW charge port fault";
CM_ SG_ 800 BMS_a064_SW_SOC_Imbalance "High-voltage battery management system: a064 SW SOC imbalance";
CM_ SG_ 800 BMS_a065_SW_CAC_Imbalance "High-voltage battery management system: a065 SW CAC imbalance";
CM_ SG_ 800 BMS_a066_SOC_Imbalance_Warning "High-voltage battery management system: a066 SOC imbalance warning";
CM_ SG_ 800 BMS_a067_CAC_Imbalance_Limiting "High-voltage battery management system: a067 CAC imbalance limiting";
CM_ SG_ 800 BMS_a068_CAC_Imbalance_Limp "High-voltage battery management system: a068 CAC imbalance limp";
CM_ SG_ 800 BMS_a069_SW_Low_Power "High-voltage battery management system: a069 SW low power";
CM_ SG_ 800 BMS_a070_BrickV_Imbalance_Limiti "High-voltage battery management system: a070 brick v imbalance limiting";
CM_ SG_ 800 BMS_a071_SW_SM_TransCon_Not_Met "High-voltage battery management system: a071 SW SM trans con not met";
CM_ SG_ 800 BMS_a072_Module_Brick_Split "High-voltage battery management system: a072 module brick split";
CM_ SG_ 800 BMS_a073_Unexpected_Loss_Of_Lv "High-voltage battery management system: a073 unexpected loss of lv";
CM_ SG_ 800 BMS_a074_Max_Charge_Level_Reduce "High-voltage battery management system: a074 max charge level reduced";
CM_ SG_ 800 BMS_a075_SW_Chg_Disable_Failure "High-voltage battery management system: a075 SW chg disable failure";
CM_ SG_ 800 BMS_a076_SW_Dch_While_Charging "High-voltage battery management system: a076 SW dch while charging";
CM_ SG_ 800 BMS_a077_SW_Charger_Regulation "High-voltage battery management system: a077 SW charger regulation";
CM_ SG_ 800 BMS_a078_Rapid_Dch_While_Chargin "High-voltage battery management system: a078 rapid dch while charging";
CM_ SG_ 800 BMS_a079_Max_Charge_Level_Exceed "High-voltage battery management system: a079 max charge level exceeded";
CM_ SG_ 800 BMS_a080_SW_Pack_Ctr_Impedance "High-voltage battery management system: a080 SW pack ctr impedance";
CM_ SG_ 800 BMS_a081_SW_Ctr_Close_Blocked "High-voltage battery management system: a081 SW ctr close blocked";
CM_ SG_ 800 BMS_a082_SW_Ctr_Force_Open "High-voltage battery management system: a082 SW ctr force open";
CM_ SG_ 800 BMS_a083_SW_Ctr_Close_Failure "High-voltage battery management system: a083 SW ctr close failure";
CM_ SG_ 800 BMS_a084_SW_Sleep_Wake_Aborted "High-voltage battery management system: a084 SW sleep wake aborted";
CM_ SG_ 800 BMS_a085_SW_Pack_Contactor_Misma "High-voltage battery management system: a085 SW pack contactor mismatch";
CM_ SG_ 800 BMS_a086_SW_FC_Contactor_Mismatc "High-voltage battery management system: a086 SW FC contactor mismatch";
CM_ SG_ 800 BMS_a087_SW_Feim_Test_Blocked "High-voltage battery management system: a087 SW feim test blocked";
CM_ SG_ 800 BMS_a088_SW_VcFront_MIA_InDrive "High-voltage battery management system: a088 SW vc front MIA in drive";
CM_ SG_ 800 BMS_a089_SW_VcFront_MIA "High-voltage battery management system: a089 SW vc front MIA";
CM_ SG_ 800 BMS_a090_SW_Gateway_MIA "High-voltage battery management system: a090 SW gateway MIA";
CM_ SG_ 800 BMS_a091_SW_ChargePort_MIA "High-voltage battery management system: a091 SW charge port MIA";
CM_ SG_ 800 BMS_a092_SW_ChargePort_Mia_On_Hv "High-voltage battery management system: a092 SW charge port mia on hvs";
CM_ SG_ 800 BMS_a094_SW_Drive_Inverter_MIA "High-voltage battery management system: a094 SW drive inverter MIA";
CM_ SG_ 800 BMS_a095_SW_UI_MIA "High-voltage battery management system: a095 SW UI MIA";
CM_ SG_ 800 BMS_a097_SW_BMB_Over_CAN_Communi "High-voltage battery management system: a097 SW BMB over CAN communication";
CM_ SG_ 800 BMS_a098_SW_BMB_Data_Integrity_L "High-voltage battery management system: a098 SW BMB data integrity loss";
CM_ SG_ 800 BMS_a099_SW_BMB_Communication "High-voltage battery management system: a099 SW BMB communication";
CM_ SG_ 800 BMS_a100_ThermalEventSuspected "High-voltage battery management system: a100 thermal event suspected";
CM_ SG_ 800 BMS_a105_SW_One_Module_Tsense "High-voltage battery management system: a105 SW one module tsense";
CM_ SG_ 800 BMS_a106_SW_All_Module_Tsense "High-voltage battery management system: a106 SW all module tsense";
CM_ SG_ 800 BMS_a107_SW_Stack_Voltage_MIA "High-voltage battery management system: a107 SW stack voltage MIA";
CM_ SG_ 800 BMS_a108_SW_BMB_Device_OT "High-voltage battery management system: a108 SW BMB device OT";
CM_ SG_ 800 BMS_a109_HW_BMB_Mute_Status_Mism "High-voltage battery management system: a109 HW BMB mute status mismatch";
CM_ SG_ 800 BMS_a110_LifeModel_AvgOffset_Cha "High-voltage battery management system: a110 life model avg offset change";
CM_ SG_ 800 BMS_a111_LifeModel_Spread_Change "High-voltage battery management system: a111 life model spread change";
CM_ SG_ 800 BMS_a112_LifeModel_Discontinuity "High-voltage battery management system: a112 life model discontinuity";
CM_ SG_ 800 BMS_a115_Energy_Rubberbanding_Re "High-voltage battery management system: a115 energy rubberbanding reset";
CM_ SG_ 800 BMS_a117_SW_Delta_SOC_Weak_Short "High-voltage battery management system: a117 SW delta SOC weak short";
CM_ SG_ 800 BMS_a118_SW_Delta_SOC_Weak_Short "High-voltage battery management system: a118 SW delta SOC weak short warning";
CM_ SG_ 800 BMS_a119_Fast_Open_Vsh_Detected "High-voltage battery management system: a119 fast open vsh detected";
CM_ SG_ 800 BMS_a120_SW_Delta_SOC_User_Warni "High-voltage battery management system: a120 SW delta SOC user warning";
CM_ SG_ 800 BMS_a121_SW_NVRAM_Config_Error "High-voltage battery management system: a121 SW NVRAM config error";
CM_ SG_ 800 BMS_a122_SW_BMS_Therm_Irrational "High-voltage battery management system: a122 SW BMS therm irrational";
CM_ SG_ 800 BMS_a123_SW_Internal_Isolation "High-voltage battery management system: a123 SW internal isolation";
CM_ SG_ 800 BMS_a124_Battery_Coolant_Flood "High-voltage battery management system: a124 battery coolant flood";
CM_ SG_ 800 BMS_a126_SW_Thermistor_Failure "High-voltage battery management system: a126 SW thermistor failure";
CM_ SG_ 800 BMS_a127_SW_shunt_SNA "High-voltage battery management system: a127 SW shunt SNA";
CM_ SG_ 800 BMS_a128_SW_shunt_MIA "High-voltage battery management system: a128 SW shunt MIA";
CM_ SG_ 800 BMS_a129_SW_VSH_Failure "High-voltage battery management system: a129 SW VSH failure";
CM_ SG_ 800 BMS_a130_IO_CAN_Error "High-voltage battery management system: a130 IO CAN error";
CM_ SG_ 800 BMS_a131_Bleed_FET_Failure "High-voltage battery management system: a131 bleed FET failure";
CM_ SG_ 800 BMS_a132_HW_BMB_OTP_Uncorrctbl "High-voltage battery management system: a132 HW BMB OTP uncorrctbl";
CM_ SG_ 800 BMS_a133_IO_CAN_Bus_Off "High-voltage battery management system: a133 IO CAN bus off";
CM_ SG_ 800 BMS_a134_SW_Delayed_Ctr_Off "High-voltage battery management system: a134 SW delayed ctr off";
CM_ SG_ 800 BMS_a135_HW_BMB_Diagnostics_Fail "High-voltage battery management system: a135 HW BMB diagnostics failure";
CM_ SG_ 800 BMS_a136_SW_Module_OT_Warning "High-voltage battery management system: a136 SW module OT warning";
CM_ SG_ 800 BMS_a137_SW_Brick_UV_Warning "High-voltage battery management system: a137 SW brick UV warning";
CM_ SG_ 800 BMS_a138_SW_Brick_OV_Warning "High-voltage battery management system: a138 SW brick OV warning";
CM_ SG_ 800 BMS_a139_SW_DC_Link_V_Irrational "High-voltage battery management system: a139 SW DC link v irrational";
CM_ SG_ 800 BMS_a140_HW_BMB_Status_Fault "High-voltage battery management system: a140 HW BMB status fault";
CM_ SG_ 800 BMS_a141_SW_BMB_Status_Warning "High-voltage battery management system: a141 SW BMB status warning";
CM_ SG_ 800 BMS_a142_SW_Isolation_Degradatio "High-voltage battery management system: a142 SW isolation degradation";
CM_ SG_ 800 BMS_a143_SW_CAC_Change "High-voltage battery management system: a143 SW CAC change";
CM_ SG_ 800 BMS_a144_Hvp_Config_Mismatch "High-voltage battery management system: a144 hvp config mismatch";
CM_ SG_ 800 BMS_a145_SW_SOC_Change "High-voltage battery management system: a145 SW SOC change";
CM_ SG_ 800 BMS_a146_SW_Brick_Overdischarged "High-voltage battery management system: a146 SW brick overdischarged";
CM_ SG_ 800 BMS_a147_SW_SOC_High_Ah_Error "High-voltage battery management system: a147 SW SOC high ah error";
CM_ SG_ 800 BMS_a148_SW_Unsupported_BMB_ASIC "High-voltage battery management system: a148 SW unsupported BMB ASIC type";
CM_ SG_ 800 BMS_a149_SW_Missing_Config_Block "High-voltage battery management system: a149 SW missing config block";
CM_ SG_ 800 BMS_a150_SW_Missing_Part_Number "High-voltage battery management system: a150 SW missing part number";
CM_ SG_ 800 BMS_a151_SW_external_isolation "High-voltage battery management system: a151 SW external isolation";
CM_ SG_ 800 BMS_a152_Isolation_In_Dc_Charge "High-voltage battery management system: a152 isolation in dc charge";
CM_ SG_ 800 BMS_a153_GridFormFaulted "High-voltage battery management system: a153 grid form faulted";
CM_ SG_ 800 BMS_a154_SW_Brick_OV_Warning_Sto "High-voltage battery management system: a154 SW brick OV warning stop charge";
CM_ SG_ 800 BMS_a155_SW_Weak_short_impedence "High-voltage battery management system: a155 SW weak short impedence";
CM_ SG_ 800 BMS_a156_SW_BMB_Vref_bad "High-voltage battery management system: a156 SW BMB vref bad";
CM_ SG_ 800 BMS_a157_SW_Hist_Update_Missed "High-voltage battery management system: a157 SW hist update missed";
CM_ SG_ 800 BMS_a158_SW_HVP_HVI_Comms "High-voltage battery management system: a158 SW HVP HVI comms";
CM_ SG_ 800 BMS_a159_SW_HVP_ECU_Error "High-voltage battery management system: a159 SW HVP ECU error";
CM_ SG_ 800 BMS_a160_SW_FC_Ctr_Clean_Failed "High-voltage battery management system: a160 SW FC ctr clean failed";
CM_ SG_ 800 BMS_a161_SW_BMB_Vref_warning "High-voltage battery management system: a161 SW BMB vref warning";
CM_ SG_ 800 BMS_a162_SW_No_Power_For_Support "High-voltage battery management system: a162 SW no power for support";
CM_ SG_ 800 BMS_a163_GridFormAborted "High-voltage battery management system: a163 grid form aborted";
CM_ SG_ 800 BMS_a164_SW_Uncontrolled_Regen "High-voltage battery management system: a164 SW uncontrolled regen";
CM_ SG_ 800 BMS_a165_SW_Pack_Partial_Weld "High-voltage battery management system: a165 SW pack partial weld";
CM_ SG_ 800 BMS_a166_SW_Pack_Full_Weld "High-voltage battery management system: a166 SW pack full weld";
CM_ SG_ 800 BMS_a167_SW_FC_Partial_Weld "High-voltage battery management system: a167 SW FC partial weld";
CM_ SG_ 800 BMS_a168_SW_FC_Full_Weld "High-voltage battery management system: a168 SW FC full weld";
CM_ SG_ 800 BMS_a169_SW_FC_Pack_Weld "High-voltage battery management system: a169 SW FC pack weld";
CM_ SG_ 800 BMS_a170_SW_Limp_Mode "High-voltage battery management system: a170 SW limp mode";
CM_ SG_ 800 BMS_a171_SW_Stack_Voltage_Sense "High-voltage battery management system: a171 SW stack voltage sense";
CM_ SG_ 800 BMS_a172_SW_Isolation_Failure_In "High-voltage battery management system: a172 SW isolation failure in drive warning";
CM_ SG_ 800 BMS_a173_FullPackEnergyDegraded "High-voltage battery management system: a173 full pack energy degraded";
CM_ SG_ 800 BMS_a174_SW_Charge_Failure "High-voltage battery management system: a174 SW charge failure";
CM_ SG_ 800 BMS_a175_Charge_Failure_External "High-voltage battery management system: a175 charge failure external";
CM_ SG_ 800 BMS_a176_SW_GracefulPowerOff "High-voltage battery management system: a176 SW graceful power off";
CM_ SG_ 800 BMS_a177_SW_Energy_Buffer_Size "High-voltage battery management system: a177 SW energy buffer size";
CM_ SG_ 800 BMS_a178_SW_Uncontrolled_Regen_P "High-voltage battery management system: a178 SW uncontrolled regen pwr b";
CM_ SG_ 800 BMS_a179_HvpGpoRequestActive "High-voltage battery management system: a179 hvp gpo request active";
CM_ SG_ 800 BMS_a180_SW_ECU_reset_blocked "High-voltage battery management system: a180 SW ECU reset blocked";
CM_ SG_ 800 BMS_a181_SW_Shunt_Over_Temperatu "High-voltage battery management system: a181 SW shunt over temperature";
CM_ SG_ 800 BMS_a182_LifeModel_NoCurrentLoss "High-voltage battery management system: a182 life model no current loss change";
CM_ SG_ 800 BMS_a183_LifeModel_StoDcrGrowth_ "High-voltage battery management system: a183 life model sto dcr growth change";
CM_ SG_ 800 BMS_a184_LifeModel_CyclingLoss_C "High-voltage battery management system: a184 life model cycling loss change";
CM_ SG_ 800 BMS_a185_LifeModel_CyclingDcrGro "High-voltage battery management system: a185 life model cycling dcr growth change";
CM_ SG_ 800 BMS_a186_RippleHeatingChargeFaul "High-voltage battery management system: a186 ripple heating charge fault";
CM_ SG_ 800 BMS_a187_RippleHeatingEmergencyS "High-voltage battery management system: a187 ripple heating emergency shutdown";
CM_ SG_ 800 BMS_a188_PowershareChargeCurrent "High-voltage battery management system: a188 powershare charge current violation";
CM_ SG_ 800 BMS_a189_PowershareDischargeCurr "High-voltage battery management system: a189 powershare discharge current violation";
CM_ SG_ 800 BMS_a190_PowershareMaxVoltageVio "High-voltage battery management system: a190 powershare max voltage violation";
CM_ SG_ 800 BMS_a191_PowershareMinVoltageVio "High-voltage battery management system: a191 powershare min voltage violation";
CM_ SG_ 800 BMS_a192_PowershareExternalCharg "High-voltage battery management system: a192 powershare external charge regulation";
CM_ SG_ 800 BMS_a193_PowershareMaxBrickVolta "High-voltage battery management system: a193 powershare max brick voltage violation";
CM_ SG_ 800 BMS_a194_PowershareLimitViolatio "High-voltage battery management system: a194 powershare limit violation";
CM_ SG_ 800 BMS_a195_SW_DeltaTempOverThresho "High-voltage battery management system: a195 SW delta temp over threshold";
CM_ SG_ 800 BMS_a196_SW_PackVoltageUnderThre "High-voltage battery management system: a196 SW pack voltage under threshold";
CM_ SG_ 800 BMS_a197_SW_High_SOC_OV "High-voltage battery management system: a197 SW high SOC OV";
CM_ SG_ 800 BMS_a198_SW_SOC_Abrupt_Change "High-voltage battery management system: a198 SW SOC abrupt change";
CM_ SG_ 800 BMS_a199_GridFollowAborted "High-voltage battery management system: a199 grid follow aborted";
CM_ SG_ 800 BMS_a200_GridFollowFaulted "High-voltage battery management system: a200 grid follow faulted";
CM_ SG_ 800 BMS_a201_SW_Brick_OV_During_Char "High-voltage battery management system: a201 SW brick OV during charge";
CM_ SG_ 800 BMS_a202_AcChargeFaulted "High-voltage battery management system: a202 ac charge faulted";
CM_ SG_ 800 BMS_a204_AcCpEmergencyShutdownRe "High-voltage battery management system: a204 ac cp emergency shutdown requested";
CM_ SG_ 800 BMS_a214_AcChargeAborted "High-voltage battery management system: a214 ac charge aborted";
CM_ SG_ 800 BMS_a221_PcsEmergencyShutdownReq "High-voltage battery management system: a221 pcs emergency shutdown requested";
CM_ SG_ 800 BMS_a227_ExcessChargeCurrentInCh "High-voltage battery management system: a227 excess charge current in charge";
CM_ SG_ 800 BMS_a254_LdcsCacImbalance "High-voltage battery management system: a254 ldcs cac imbalance";
CM_ SG_ 800 BMS_a255_EstimatedRangeReduced "High-voltage battery management system: a255 estimated range reduced";
CM_ SG_ 800 BMS_a256_SW_Low_Power_Warning "High-voltage battery management system: a256 SW low power warning";
CM_ SG_ 800 BMS_d257_internalIsolationFault "High-voltage battery management system: d257 internal isolation fault";
CM_ SG_ 800 BMS_d258_externalIsolationFault "High-voltage battery management system: d258 external isolation fault";
CM_ SG_ 800 BMS_d259_highVoltageInterlockFai "High-voltage battery management system: d259 high voltage interlock failure";
CM_ SG_ 800 BMS_d260_chargePortInterlockFail "High-voltage battery management system: d260 charge port interlock failure";
CM_ SG_ 800 BMS_d261_batteryPackCellVoltageH "High-voltage battery management system: d261 battery pack cell voltage high";
CM_ SG_ 800 BMS_d262_batteryPackLowStateOfCh "High-voltage battery management system: d262 battery pack low state of charge";
CM_ SG_ 800 BMS_d263_batterySystemCurrentHig "High-voltage battery management system: d263 battery system current high";
CM_ SG_ 800 BMS_d264_invalidFirmwareConfig "High-voltage battery management system: d264 invalid firmware config";
CM_ SG_ 800 BMS_d265_replaceBatteryPack "High-voltage battery management system: d265 replace battery pack";
CM_ SG_ 800 BMS_d266_energyReserveVoltageLow "High-voltage battery management system: d266 energy reserve voltage low";
CM_ SG_ 800 BMS_d267_batteryPackCellVoltageS "High-voltage battery management system: d267 battery pack cell voltage sense harness failure";
CM_ SG_ 800 BMS_d268_hvpInvalidFirmwareConfi "High-voltage battery management system: d268 hvp invalid firmware config";
CM_ SG_ 800 BMS_d269_highVoltageFuseABlown "High-voltage battery management system: d269 high voltage fuse a blown";
CM_ SG_ 800 BMS_d270_hvpCommsLost "High-voltage battery management system: d270 hvp comms lost";
CM_ SG_ 800 BMS_d271_batteryPackSensorFailur "High-voltage battery management system: d271 battery pack sensor failure";
CM_ SG_ 800 BMS_d272_batteryPackSensorCommsL "High-voltage battery management system: d272 battery pack sensor comms lost";
CM_ SG_ 800 BMS_d273_vcFrontCommsLost "High-voltage battery management system: d273 vc front comms lost";
CM_ SG_ 800 BMS_d274_packCurrentSensorACircu "High-voltage battery management system: d274 pack current sensor a circuit failure";
CM_ SG_ 800 BMS_d275_packPosContactorACircui "High-voltage battery management system: d275 pack pos contactor a circuit failure";
CM_ SG_ 800 BMS_d276_packPosContactorAStuckC "High-voltage battery management system: d276 pack pos contactor a stuck closed";
CM_ SG_ 800 BMS_d277_packNegContactorACircui "High-voltage battery management system: d277 pack neg contactor a circuit failure";
CM_ SG_ 800 BMS_d278_packNegContactorAStuckC "High-voltage battery management system: d278 pack neg contactor a stuck closed";
CM_ SG_ 800 BMS_d279_fastChargePosContactorA "High-voltage battery management system: d279 fast charge pos contactor a circuit failure";
CM_ SG_ 800 BMS_d280_fastChargePosContactorA "High-voltage battery management system: d280 fast charge pos contactor a stuck closed";
CM_ SG_ 800 BMS_d281_fastChargePosContactorA "High-voltage battery management system: d281 fast charge pos contactor a stuck open";
CM_ SG_ 800 BMS_d282_fastChargeNegContactorA "High-voltage battery management system: d282 fast charge neg contactor a circuit failure";
CM_ SG_ 800 BMS_d283_fastChargeNegContactorA "High-voltage battery management system: d283 fast charge neg contactor a stuck closed";
CM_ SG_ 800 BMS_d284_fastChargeNegContactorA "High-voltage battery management system: d284 fast charge neg contactor a stuck open";
CM_ SG_ 800 BMS_d285_packVoltageSensorACircu "High-voltage battery management system: d285 pack voltage sensor a circuit failure";
CM_ SG_ 800 BMS_d286_dcLinkVoltageHigh "High-voltage battery management system: d286 dc link voltage high";
CM_ SG_ 800 BMS_d287_systemIsolationWarning "High-voltage battery management system: d287 system isolation warning";
CM_ SG_ 800 BMS_d288_batteryPackCellVoltageL "High-voltage battery management system: d288 battery pack cell voltage low";
CM_ SG_ 800 BMS_d289_batteryPackAOverTempera "High-voltage battery management system: d289 battery pack a over temperature";
CM_ SG_ 800 BMS_d290_batteryPackTempSensorAC "High-voltage battery management system: d290 battery pack temp sensor a circuit failure";
CM_ SG_ 800 BMS_a291_SOC_Imbalance_By_Delta_ "High-voltage battery management system: a291 SOC imbalance by delta voltage over delta SOC";
CM_ SG_ 800 BMS_a299_PowershareFailure "High-voltage battery management system: a299 powershare failure";
CM_ BO_ 818 "High-voltage battery management system message: bmb min max";
CM_ SG_ 818 BMS_bmbMinMaxMultiplexer "High-voltage battery management system: bmb min max multiplexer";
CM_ SG_ 818 BMS_thermistorNumTMin "BMB module number with minimum temperature.";
CM_ SG_ 818 BMS_thermistorNumTMax "BMB module number with maximum temperature.";
CM_ SG_ 818 BMS_thermistorTMax "Max temperature of all valid filtered thermistors";
CM_ SG_ 818 BMS_thermistorTMin "Min temperature of all valid filtered thermistors";
CM_ SG_ 818 BMS_thermistorTAvg "Average temperature of all valid filtered thermistors";
CM_ SG_ 818 BMS_brickVoltageMax "Brick voltage maximum.";
CM_ SG_ 818 BMS_brickVoltageMin "Brick voltage minimum.";
CM_ SG_ 818 BMS_brickNumVoltageMax "Brick number with maximum voltage (1 indexed)";
CM_ SG_ 818 BMS_brickNumVoltageMin "Brick number with minimum voltage (1 indexed)";
BA_DEF_ BO_ "GenMsgCycleTime" INT 0 3600000;
BA_DEF_ BO_ "GenMsgSendType" ENUM "Cyclic","NotUsed","NotUsed","NotUsed","NotUsed","NotUsed","NotUsed","IfActive","NoMsgSendType","NotUsed";
BA_DEF_ BO_ "VFrameFormat" ENUM "StandardCAN","ExtendedCAN","reserved","J1939PG","reserved","reserved","reserved","reserved","reserved","reserved","reserved","reserved","reserved","reserved","StandardCAN_FD","ExtendedCAN_FD";
BA_DEF_ BO_ "CANFD_BRS" ENUM "0","1";
BA_DEF_ SG_ "SystemSignalLongSymbol" STRING;
BA_DEF_ SG_ "Confidence" ENUM "layout-only","plausible","validated";
BA_DEF_DEF_ "GenMsgCycleTime" 0;
BA_DEF_DEF_ "GenMsgSendType" "NoMsgSendType";
BA_DEF_DEF_ "VFrameFormat" "StandardCAN";
BA_DEF_DEF_ "CANFD_BRS" "1";
BA_DEF_DEF_ "SystemSignalLongSymbol" "";
BA_DEF_DEF_ "Confidence" "layout-only";
BA_ "SystemSignalLongSymbol" SG_ 848 APS_w245_eloopRxFromUnexpectedSo "APS_w245_eloopRxFromUnexpectedSourceMAC";
BA_ "SystemSignalLongSymbol" SG_ 848 APS_w246_ethloopSwitchPortLinkDo "APS_w246_ethloopSwitchPortLinkDown";
BA_ "SystemSignalLongSymbol" SG_ 848 APS_w250_ethloopSwitchMemUsageTo "APS_w250_ethloopSwitchMemUsageTooHighPort2";
BA_ "SystemSignalLongSymbol" SG_ 848 APS_w251_ethloopSwitchMemUsageTo "APS_w251_ethloopSwitchMemUsageTooHighPort3";
BA_ "SystemSignalLongSymbol" SG_ 784 APS_w258_qspiFlashSectorChecksum "APS_w258_qspiFlashSectorChecksumMismatch";
BA_ "SystemSignalLongSymbol" SG_ 784 APS_w269_ethSwitchRxPageCountToo "APS_w269_ethSwitchRxPageCountTooHighPort0_3";
BA_ "SystemSignalLongSymbol" SG_ 784 APS_w270_ethSwitchRxPageCountToo "APS_w270_ethSwitchRxPageCountTooHighPort4_7";
BA_ "SystemSignalLongSymbol" SG_ 784 APS_w284_cam12VBuckBoostAPwrIssu "APS_w284_cam12VBuckBoostAPwrIssue";
BA_ "SystemSignalLongSymbol" SG_ 784 APS_w285_cam12VBuckBoostBPwrIssu "APS_w285_cam12VBuckBoostBPwrIssue";
BA_ "SystemSignalLongSymbol" SG_ 784 APS_w286_cam12VEFuseAPrimaryIssu "APS_w286_cam12VEFuseAPrimaryIssue";
BA_ "SystemSignalLongSymbol" SG_ 784 APS_w287_cam12VEFuseASecondaryIs "APS_w287_cam12VEFuseASecondaryIssue";
BA_ "SystemSignalLongSymbol" SG_ 784 APS_w290_cam12VBuckBoostBPwrRing "APS_w290_cam12VBuckBoostBPwrRinging";
BA_ "SystemSignalLongSymbol" SG_ 784 APS_w298_cpuToApCanSharedMemErro "APS_w298_cpuToApCanSharedMemError";
BA_ "SystemSignalLongSymbol" SG_ 784 APS_w299_apToCpuCanSharedMemErro "APS_w299_apToCpuCanSharedMemError";
BA_ "SystemSignalLongSymbol" SG_ 784 APS_w318_ethernetNetworkBufferHi "APS_w318_ethernetNetworkBufferHighWatermark";
BA_ "SystemSignalLongSymbol" SG_ 784 APS_w320_eplannerPreconditionsMe "APS_w320_eplannerPreconditionsMet";
BA_ "Confidence" SG_ 943 BB_sOutputRod 1;
BA_ "Confidence" SG_ 943 BB_sOutputRodQF 1;
BA_ "Confidence" SG_ 943 BB_sInputRod 1;
BA_ "Confidence" SG_ 943 BB_sInputRodQF 1;
BA_ "Confidence" SG_ 943 BB_driverBrakeApply 1;
BA_ "Confidence" SG_ 943 BB_driverBrakeApplyQF 1;
BA_ "Confidence" SG_ 943 BB_boosterStatus 1;
BA_ "Confidence" SG_ 943 BB_warningLampRequest 1;
BA_ "Confidence" SG_ 943 BB_brakeFluidLevel 1;
BA_ "Confidence" SG_ 943 BB_internalState 1;
BA_ "Confidence" SG_ 943 BB_unfilteredFluidLevelLow 1;
BA_ "SystemSignalLongSymbol" SG_ 1343 BMS_a002_gatewayPackPerformanceD "BMS_a002_gatewayPackPerformanceDeviation";
BA_ "SystemSignalLongSymbol" SG_ 1343 BMS_a002_expectedPackPerformance "BMS_a002_expectedPackPerformanceDeviation";
BA_ "SystemSignalLongSymbol" SG_ 1343 BMS_a022_chargeAccumulatorViolat "BMS_a022_chargeAccumulatorViolation";
BA_ "SystemSignalLongSymbol" SG_ 1343 BMS_a030_maxNormalizedImpedanceD "BMS_a030_maxNormalizedImpedanceDev";
BA_ "SystemSignalLongSymbol" SG_ 1343 BMS_a069_dischargePowerPackVolta "BMS_a069_dischargePowerPackVoltageFloor";
BA_ "SystemSignalLongSymbol" SG_ 1343 BMS_a069_dischargePowerBrickVolt "BMS_a069_dischargePowerBrickVoltageFloor";
BA_ "SystemSignalLongSymbol" SG_ 1343 BMS_a085_packContactorSetStatePr "BMS_a085_packContactorSetStatePrev";
BA_ "SystemSignalLongSymbol" SG_ 1343 BMS_a085_packContactorSetRe_0001 "BMS_a085_packContactorSetRequestPrev";
BA_ "SystemSignalLongSymbol" SG_ 1343 BMS_a086_fcContactorSetRequestPr "BMS_a086_fcContactorSetRequestPrev";
BA_ "SystemSignalLongSymbol" SG_ 1343 BMS_a122_irrationalThermistorTem "BMS_a122_irrationalThermistorTemp";
BA_ "SystemSignalLongSymbol" SG_ 1343 BMS_a122_averageRawThermistorTem "BMS_a122_averageRawThermistorTemp";
BA_ "SystemSignalLongSymbol" SG_ 800 BMS_a002_Pack_Performance_Config "BMS_a002_Pack_Performance_Config_Mismatch";
BA_ "SystemSignalLongSymbol" SG_ 800 BMS_a003_SW_Pack_Birth_Date_Miss "BMS_a003_SW_Pack_Birth_Date_Missing";
BA_ "SystemSignalLongSymbol" SG_ 800 BMS_a004_Cal_Vs_Serial_Birth_Dat "BMS_a004_Cal_Vs_Serial_Birth_Date_Mismatch";
BA_ "SystemSignalLongSymbol" SG_ 800 BMS_a027_SW_Repeated_Isolation_F "BMS_a027_SW_Repeated_Isolation_Failure_In_Drive";
BA_ "SystemSignalLongSymbol" SG_ 800 BMS_a028_ShuntAsicCurrentOffsetD "BMS_a028_ShuntAsicCurrentOffsetDeviation";
BA_ "SystemSignalLongSymbol" SG_ 800 BMS_a040_SW_Watch_Dog_HW_Trigger "BMS_a040_SW_Watch_Dog_HW_Triggered";
BA_ "SystemSignalLongSymbol" SG_ 800 BMS_a041_SW_Destructive_Reset_So "BMS_a041_SW_Destructive_Reset_Source";
BA_ "SystemSignalLongSymbol" SG_ 800 BMS_a057_SW_Bandolier_Model_Warn "BMS_a057_SW_Bandolier_Model_Warning";
BA_ "SystemSignalLongSymbol" SG_ 800 BMS_a058_SW_Bandolier_Model_Rese "BMS_a058_SW_Bandolier_Model_Reset";
BA_ "SystemSignalLongSymbol" SG_ 800 BMS_a070_BrickV_Imbalance_Limiti "BMS_a070_BrickV_Imbalance_Limiting";
BA_ "SystemSignalLongSymbol" SG_ 800 BMS_a074_Max_Charge_Level_Reduce "BMS_a074_Max_Charge_Level_Reduced";
BA_ "SystemSignalLongSymbol" SG_ 800 BMS_a078_Rapid_Dch_While_Chargin "BMS_a078_Rapid_Dch_While_Charging";
BA_ "SystemSignalLongSymbol" SG_ 800 BMS_a079_Max_Charge_Level_Exceed "BMS_a079_Max_Charge_Level_Exceeded";
BA_ "SystemSignalLongSymbol" SG_ 800 BMS_a085_SW_Pack_Contactor_Misma "BMS_a085_SW_Pack_Contactor_Mismatch";
BA_ "SystemSignalLongSymbol" SG_ 800 BMS_a086_SW_FC_Contactor_Mismatc "BMS_a086_SW_FC_Contactor_Mismatch";
BA_ "SystemSignalLongSymbol" SG_ 800 BMS_a092_SW_ChargePort_Mia_On_Hv "BMS_a092_SW_ChargePort_Mia_On_Hvs";
BA_ "SystemSignalLongSymbol" SG_ 800 BMS_a097_SW_BMB_Over_CAN_Communi "BMS_a097_SW_BMB_Over_CAN_Communication";
BA_ "SystemSignalLongSymbol" SG_ 800 BMS_a098_SW_BMB_Data_Integrity_L "BMS_a098_SW_BMB_Data_Integrity_Loss";
BA_ "SystemSignalLongSymbol" SG_ 800 BMS_a109_HW_BMB_Mute_Status_Mism "BMS_a109_HW_BMB_Mute_Status_Mismatch";
BA_ "SystemSignalLongSymbol" SG_ 800 BMS_a110_LifeModel_AvgOffset_Cha "BMS_a110_LifeModel_AvgOffset_Change";
BA_ "SystemSignalLongSymbol" SG_ 800 BMS_a115_Energy_Rubberbanding_Re "BMS_a115_Energy_Rubberbanding_Reset";
BA_ "SystemSignalLongSymbol" SG_ 800 BMS_a118_SW_Delta_SOC_Weak_Short "BMS_a118_SW_Delta_SOC_Weak_Short_Warning";
BA_ "SystemSignalLongSymbol" SG_ 800 BMS_a120_SW_Delta_SOC_User_Warni "BMS_a120_SW_Delta_SOC_User_Warning";
BA_ "SystemSignalLongSymbol" SG_ 800 BMS_a135_HW_BMB_Diagnostics_Fail "BMS_a135_HW_BMB_Diagnostics_Failure";
BA_ "SystemSignalLongSymbol" SG_ 800 BMS_a142_SW_Isolation_Degradatio "BMS_a142_SW_Isolation_Degradation";
BA_ "SystemSignalLongSymbol" SG_ 800 BMS_a148_SW_Unsupported_BMB_ASIC "BMS_a148_SW_Unsupported_BMB_ASIC_Type";
BA_ "SystemSignalLongSymbol" SG_ 800 BMS_a154_SW_Brick_OV_Warning_Sto "BMS_a154_SW_Brick_OV_Warning_Stop_Charge";
BA_ "SystemSignalLongSymbol" SG_ 800 BMS_a172_SW_Isolation_Failure_In "BMS_a172_SW_Isolation_Failure_In_Drive_Warning";
BA_ "SystemSignalLongSymbol" SG_ 800 BMS_a178_SW_Uncontrolled_Regen_P "BMS_a178_SW_Uncontrolled_Regen_PwrB";
BA_ "SystemSignalLongSymbol" SG_ 800 BMS_a181_SW_Shunt_Over_Temperatu "BMS_a181_SW_Shunt_Over_Temperature";
BA_ "SystemSignalLongSymbol" SG_ 800 BMS_a182_LifeModel_NoCurrentLoss "BMS_a182_LifeModel_NoCurrentLoss_Change";
BA_ "SystemSignalLongSymbol" SG_ 800 BMS_a183_LifeModel_StoDcrGrowth_ "BMS_a183_LifeModel_StoDcrGrowth_Change";
BA_ "SystemSignalLongSymbol" SG_ 800 BMS_a184_LifeModel_CyclingLoss_C "BMS_a184_LifeModel_CyclingLoss_Change";
BA_ "SystemSignalLongSymbol" SG_ 800 BMS_a185_LifeModel_CyclingDcrGro "BMS_a185_LifeModel_CyclingDcrGrowth_Change";
BA_ "SystemSignalLongSymbol" SG_ 800 BMS_a186_RippleHeatingChargeFaul "BMS_a186_RippleHeatingChargeFault";
BA_ "SystemSignalLongSymbol" SG_ 800 BMS_a187_RippleHeatingEmergencyS "BMS_a187_RippleHeatingEmergencyShutdown";
BA_ "SystemSignalLongSymbol" SG_ 800 BMS_a188_PowershareChargeCurrent "BMS_a188_PowershareChargeCurrentViolation";
BA_ "SystemSignalLongSymbol" SG_ 800 BMS_a189_PowershareDischargeCurr "BMS_a189_PowershareDischargeCurrentViolation";
BA_ "SystemSignalLongSymbol" SG_ 800 BMS_a190_PowershareMaxVoltageVio "BMS_a190_PowershareMaxVoltageViolation";
BA_ "SystemSignalLongSymbol" SG_ 800 BMS_a191_PowershareMinVoltageVio "BMS_a191_PowershareMinVoltageViolation";
BA_ "SystemSignalLongSymbol" SG_ 800 BMS_a192_PowershareExternalCharg "BMS_a192_PowershareExternalChargeRegulation";
BA_ "SystemSignalLongSymbol" SG_ 800 BMS_a193_PowershareMaxBrickVolta "BMS_a193_PowershareMaxBrickVoltageViolation";
BA_ "SystemSignalLongSymbol" SG_ 800 BMS_a194_PowershareLimitViolatio "BMS_a194_PowershareLimitViolation";
BA_ "SystemSignalLongSymbol" SG_ 800 BMS_a195_SW_DeltaTempOverThresho "BMS_a195_SW_DeltaTempOverThreshold";
BA_ "SystemSignalLongSymbol" SG_ 800 BMS_a196_SW_PackVoltageUnderThre "BMS_a196_SW_PackVoltageUnderThreshold";
BA_ "SystemSignalLongSymbol" SG_ 800 BMS_a201_SW_Brick_OV_During_Char "BMS_a201_SW_Brick_OV_During_Charge";
BA_ "SystemSignalLongSymbol" SG_ 800 BMS_a204_AcCpEmergencyShutdownRe "BMS_a204_AcCpEmergencyShutdownRequested";
BA_ "SystemSignalLongSymbol" SG_ 800 BMS_a221_PcsEmergencyShutdownReq "BMS_a221_PcsEmergencyShutdownRequested";
BA_ "SystemSignalLongSymbol" SG_ 800 BMS_a227_ExcessChargeCurrentInCh "BMS_a227_ExcessChargeCurrentInCharge";
BA_ "SystemSignalLongSymbol" SG_ 800 BMS_d259_highVoltageInterlockFai "BMS_d259_highVoltageInterlockFailure";
BA_ "SystemSignalLongSymbol" SG_ 800 BMS_d260_chargePortInterlockFail "BMS_d260_chargePortInterlockFailure";
BA_ "SystemSignalLongSymbol" SG_ 800 BMS_d261_batteryPackCellVoltageH "BMS_d261_batteryPackCellVoltageHigh";
BA_ "SystemSignalLongSymbol" SG_ 800 BMS_d262_batteryPackLowStateOfCh "BMS_d262_batteryPackLowStateOfCharge";
BA_ "SystemSignalLongSymbol" SG_ 800 BMS_d263_batterySystemCurrentHig "BMS_d263_batterySystemCurrentHigh";
BA_ "SystemSignalLongSymbol" SG_ 800 BMS_d267_batteryPackCellVoltageS "BMS_d267_batteryPackCellVoltageSenseHarnessFailure";
BA_ "SystemSignalLongSymbol" SG_ 800 BMS_d268_hvpInvalidFirmwareConfi "BMS_d268_hvpInvalidFirmwareConfig";
BA_ "SystemSignalLongSymbol" SG_ 800 BMS_d271_batteryPackSensorFailur "BMS_d271_batteryPackSensorFailure";
BA_ "SystemSignalLongSymbol" SG_ 800 BMS_d272_batteryPackSensorCommsL "BMS_d272_batteryPackSensorCommsLost";
BA_ "SystemSignalLongSymbol" SG_ 800 BMS_d274_packCurrentSensorACircu "BMS_d274_packCurrentSensorACircuitFailure";
BA_ "SystemSignalLongSymbol" SG_ 800 BMS_d275_packPosContactorACircui "BMS_d275_packPosContactorACircuitFailure";
BA_ "SystemSignalLongSymbol" SG_ 800 BMS_d276_packPosContactorAStuckC "BMS_d276_packPosContactorAStuckClosed";
BA_ "SystemSignalLongSymbol" SG_ 800 BMS_d277_packNegContactorACircui "BMS_d277_packNegContactorACircuitFailure";
BA_ "SystemSignalLongSymbol" SG_ 800 BMS_d278_packNegContactorAStuckC "BMS_d278_packNegContactorAStuckClosed";
BA_ "SystemSignalLongSymbol" SG_ 800 BMS_d279_fastChargePosContactorA "BMS_d279_fastChargePosContactorACircuitFailure";
BA_ "SystemSignalLongSymbol" SG_ 800 BMS_d280_fastChargePosContactorA "BMS_d280_fastChargePosContactorAStuckClosed";
BA_ "SystemSignalLongSymbol" SG_ 800 BMS_d281_fastChargePosContactorA "BMS_d281_fastChargePosContactorAStuckOpen";
BA_ "SystemSignalLongSymbol" SG_ 800 BMS_d282_fastChargeNegContactorA "BMS_d282_fastChargeNegContactorACircuitFailure";
BA_ "SystemSignalLongSymbol" SG_ 800 BMS_d283_fastChargeNegContactorA "BMS_d283_fastChargeNegContactorAStuckClosed";
BA_ "SystemSignalLongSymbol" SG_ 800 BMS_d284_fastChargeNegContactorA "BMS_d284_fastChargeNegContactorAStuckOpen";
BA_ "SystemSignalLongSymbol" SG_ 800 BMS_d285_packVoltageSensorACircu "BMS_d285_packVoltageSensorACircuitFailure";
BA_ "SystemSignalLongSymbol" SG_ 800 BMS_d288_batteryPackCellVoltageL "BMS_d288_batteryPackCellVoltageLow";
BA_ "SystemSignalLongSymbol" SG_ 800 BMS_d289_batteryPackAOverTempera "BMS_d289_batteryPackAOverTemperature";
BA_ "SystemSignalLongSymbol" SG_ 800 BMS_d290_batteryPackTempSensorAC "BMS_d290_batteryPackTempSensorACircuitFailure";
BA_ "SystemSignalLongSymbol" SG_ 800 BMS_a291_SOC_Imbalance_By_Delta_ "BMS_a291_SOC_Imbalance_By_Delta_Voltage_Over_Delta_SOC";
BA_ "Confidence" SG_ 818 BMS_thermistorNumTMin 1;
BA_ "Confidence" SG_ 818 BMS_thermistorNumTMax 1;
BA_ "Confidence" SG_ 818 BMS_thermistorTMax 1;
BA_ "Confidence" SG_ 818 BMS_thermistorTMin 1;
BA_ "Confidence" SG_ 818 BMS_thermistorTAvg 1;
BA_ "Confidence" SG_ 818 BMS_brickVoltageMax 1;
BA_ "Confidence" SG_ 818 BMS_brickVoltageMin 1;
BA_ "Confidence" SG_ 818 BMS_brickNumVoltageMax 1;
BA_ "Confidence" SG_ 818 BMS_brickNumVoltageMin 1;
VAL_ 943 BB_sOutputRodQF 2 "Faulty" 1 "Normal" 0 "NotInit_orOff" ;
VAL_ 943 BB_sInputRodQF 2 "Faulty" 1 "Normal" 0 "NotInit_orOff" ;
VAL_ 943 BB_driverBrakeApply 1 "DRIVER_APPLYING_BRAKES" 0 "BRAKES_NOT_APPLIED" ;
VAL_ 943 BB_driverBrakeApplyQF 2 "Faulty" 1 "Normal" 0 "NotInit_orOff" ;
VAL_ 943 BB_boosterStatus 6 "ACTUATION" 5 "READY" 4 "ACTIVE_GOOD_CHECK" 3 "DIAGNOSTIC" 2 "FAILURE" 1 "INIT" 0 "OFF" ;
VAL_ 943 BB_warningLampRequest 2 "RED_BRAKE_LAMP_REQUEST" 1 "YELLOW_BRAKE_LAMP_REQUEST" 0 "NO_LAMP_REQUEST" ;
VAL_ 943 BB_brakeFluidLevel 3 "BRAKE_FLUID_LEVEL_INVALID" 2 "BRAKE_FLUID_LEVEL_NORMAL" 1 "BRAKE_FLUID_LEVEL_LOW" 0 "BRAKE_FLUID_LEVEL_UNKNOWN" ;
VAL_ 943 BB_internalState 7 "READY_TO_SHUTDOWN" 6 "POST_DRIVE_CHECK" 5 "TRANSITION_TO_IDLE" 4 "DIAGNOSTIC" 3 "EXTERNAL_BRAKE_REQUEST" 2 "LOCAL_BRAKE_REQUEST" 1 "PRE_DRIVE_CHECK" 0 "NO_MODE_ACTIVE" ;
VAL_ 943 BB_unfilteredFluidLevelLow 1 "LEVEL_LOW" 0 "LEVEL_NORMAL_OR_UNKNOWN_OR_INVALID" ;
